VERSION ""

NS_ :

BS_:

BU_: PowertrainControlModule AtmosphericSensor SafetyRestraintSystem2 Aftertreatment_2_GasOutlet Aftertreatment_2_GasIntake DieselParticulateFilterControl Turbocharger SafetyRestraintSystem1 CabDisplay2 Aftertreatment_1_GasOutlet Aftertreatment_1_GasIntake OnBoardDataLogger OffBoardDiagnosticTool2 OffBoardDiagnosticTool1 FileServer ParkingBrakeController SeatController2 FanDriveController SteeringColumnUnit CommunicationUnitRadio CommunicationUnitSatellite CommunicationUnitCellular PropulsionBatteryCharger ChassisController2 ChassisController1 EngineValveControl AuxiliaryHeater2 AuxiliaryHeater1 ClutchUnit RampControl InformationSystem1 SuspensionSystemController2 OilSensor VehicleDynamicStability ExhaustEmissionController TransmissionDisplay2 TransmissionDisplay1 ClimateControl2 WaterPumpController RearAxleSteeringController LightingOperatorControl SeatController1 IgnitionController2 IgnitionController1 TirePressureController CabController2 CabController1 PneumaticSystemController SuspensionSystemController1 HydraulicPumpController EnduranceBrakingSystem RetarderExhaustEngine2 OnBoardDiagnosticUnit HeadwayController RetarderExhaustEngine1 CabDisplay1 ManagementComputer VirtualTerminal OffVehicleGateway PowerTakeOffFront HitchControl AuxiliaryValveControl BodyController TractorTrailerBridge1 StarterSystem ElectricalSystem VehicleSecurity VehicleNavigation AerodynamicControl ElectricalChargingSystem ClimateControl1 TripRecorder InstrumentCluster SuspensionDriveAxle2 SuspensionDriveAxle1 SuspensionSteerAxle SteeringController FuelSystem CruiseControl RetarderDriveline RetarderEngine BrakesDriveAxle2 BrakesDriveAxle1 BrakesSystemController BrakesSteerAxle AxleDrive2 AxleDrive1 AxleSteering PowerTakeOff ShiftConsoleSecondary ShiftConsolePrimary Transmission2 Transmission1 Engine2 Engine1

BO_ 2566835710 DM4: 13 Vector__XXX
 SG_ EngIntakeManifold1Press : 48|8@1+ (2,0) [0|500] "kPa" Vector__XXX
 SG_ FreezeFrameLength : 0|8@1+ (1,0) [0|255] "" Vector__XXX
 SG_ EngSpeed : 56|16@1+ (0.125,0) [0|8031.875] "rpm" Vector__XXX
 SG_ EngTorqueMode : 40|4@1+ (1,0) [0|15] "" Vector__XXX
 SG_ WheelBasedVehicleSpeed : 88|16@1+ (0.00390625,0) [0|250.996] "km/h" Vector__XXX
 SG_ EngPercentLoadAtCurrentSpeed : 72|8@1+ (1,0) [0|125] "%" Vector__XXX
 SG_ EngCoolantTemp : 80|8@1+ (1,-40) [-40|210] "°C" Vector__XXX
 SG_ DTC1 : 8|32@1+ (1,0) [0|4294967295] "" Vector__XXX

BO_ 2365508862 DM3: 0 Vector__XXX

BO_ 2566764542 DM25: 13 Vector__XXX
 SG_ ExpandedFreezeFrameLength : 0|8@1+ (1,0) [0|255] "" Vector__XXX
 SG_ DTC1 : 8|32@1+ (1,0) [0|4294967295] "" Vector__XXX

BO_ 2566764286 DM24: 12 Vector__XXX
 SG_ SPNSupported1High : 21|3@1+ (1,0) [0|7] "" Vector__XXX
 SG_ SPNSupportTypeSTR3 : 82|1@1+ (1,0) [0|1] "" Vector__XXX
 SG_ SPNSupportTypeSTR2 : 50|1@1+ (1,0) [0|1] "" Vector__XXX
 SG_ SPNSupportTypeEFF3 : 80|1@1+ (1,0) [0|1] "" Vector__XXX
 SG_ SPNSupportTypeEFF2 : 48|1@1+ (1,0) [0|1] "" Vector__XXX
 SG_ SPNSupportTypeDS3 : 81|1@1+ (1,0) [0|1] "" Vector__XXX
 SG_ SPNSupportTypeDS2 : 49|1@1+ (1,0) [0|1] "" Vector__XXX
 SG_ SPNSupported3High : 85|3@1+ (1,0) [0|7] "" Vector__XXX
 SG_ SPNSupported2High : 53|3@1+ (1,0) [0|7] "" Vector__XXX
 SG_ SPNSupported3 : 64|16@1+ (1,0) [0|65535] "" Vector__XXX
 SG_ SPNSupported2 : 32|16@1+ (1,0) [0|65535] "" Vector__XXX
 SG_ SPNDataLength3 : 88|8@1+ (1,0) [0|240] "" Vector__XXX
 SG_ SPNSupportTypeSTR1 : 18|1@1+ (1,0) [0|1] "" Vector__XXX
 SG_ SPNSupportTypeDS1 : 17|1@1+ (1,0) [0|1] "" Vector__XXX
 SG_ SPNSupportTypeEFF1 : 16|1@1+ (1,0) [0|1] "" Vector__XXX
 SG_ SPNDataLength2 : 56|8@1+ (1,0) [0|240] "" Vector__XXX
 SG_ SPNDataLength1 : 24|8@1+ (1,0) [0|250] "" Vector__XXX
 SG_ SPNSupported1 : 0|16@1+ (1,0) [0|524287] "" Vector__XXX

BO_ 2566764030 DM23: 22 Vector__XXX
 SG_ FlashRedStopLamp : 12|2@1+ (1,0) [0|3] "" Vector__XXX
 SG_ FlashProtectLamp : 8|2@1+ (1,0) [0|3] "" Vector__XXX
 SG_ FlashMalfuncIndicatorLamp : 14|2@1+ (1,0) [0|3] "" Vector__XXX
 SG_ FlashAmberWarningLamp : 10|2@1+ (1,0) [0|3] "" Vector__XXX
 SG_ MalfunctionIndicatorLampStatus : 6|2@1+ (1,0) [0|3] "" Vector__XXX
 SG_ RedStopLampState : 4|2@1+ (1,0) [0|3] "" Vector__XXX
 SG_ AmberWarningLampStatus : 2|2@1+ (1,0) [0|3] "" Vector__XXX
 SG_ ProtectLampStatus : 0|2@1+ (1,0) [0|3] "" Vector__XXX
 SG_ DTC5 : 144|32@1+ (1,0) [0|4294967295] "" Vector__XXX
 SG_ DTC4 : 112|32@1+ (1,0) [0|4294967295] "" Vector__XXX
 SG_ DTC3 : 80|32@1+ (1,0) [0|4294967295] "" Vector__XXX
 SG_ DTC2 : 48|32@1+ (1,0) [0|4294967295] "" Vector__XXX
 SG_ DTC1 : 16|32@1+ (1,0) [0|4294967295] "" Vector__XXX

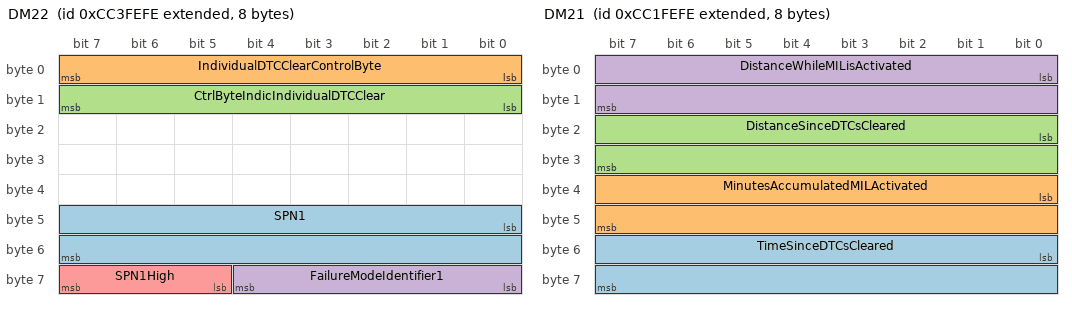
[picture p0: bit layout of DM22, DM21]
BO_ 2361655038 DM22: 8 Vector__XXX
 SG_ SPN1 : 40|16@1+ (1,0) [0|524287] "" Vector__XXX
 SG_ IndividualDTCClearControlByte : 0|8@1+ (1,0) [0|255] "" Vector__XXX
 SG_ CtrlByteIndicIndividualDTCClear : 8|8@1+ (1,0) [0|255] "" Vector__XXX
 SG_ FailureModeIdentifier1 : 56|5@1+ (1,0) [0|31] "" Vector__XXX
 SG_ SPN1High : 61|3@1+ (1,0) [0|7] "" Vector__XXX

BO_ 2361523966 DM21: 8 Vector__XXX
 SG_ TimeSinceDTCsCleared : 48|16@1+ (1,0) [0|64255] "min" Vector__XXX
 SG_ MinutesAccumulatedMILActivated : 32|16@1+ (1,0) [0|64255] "min" Vector__XXX
 SG_ DistanceSinceDTCsCleared : 16|16@1+ (1,0) [0|64255] "km" Vector__XXX
 SG_ DistanceWhileMILisActivated : 0|16@1+ (1,0) [0|64255] "km" Vector__XXX

BO_ 2562916094 DM20: 11 Vector__XXX
 SG_ ApplSysMonitorDenominator : 72|16@1+ (1,0) [0|65535] "" Vector__XXX
 SG_ ApplSysMonitorNumerator : 56|16@1+ (1,0) [0|65535] "" Vector__XXX
 SG_ SPNofApplSysMonitor : 32|24@1+ (1,0) [0|524287] "" Vector__XXX
 SG_ OBDMonitoringCondEncountered : 16|16@1+ (1,0) [0|65535] "" Vector__XXX
 SG_ IgnitionCycleCounter : 0|16@1+ (1,0) [0|65535] "" Vector__XXX

BO_ 2566834945 DM2: 22 Vector__XXX
 SG_ MalfunctionIndicatorLampStatus : 6|2@1+ (1,0) [0|3] "" Vector__XXX
 SG_ RedStopLampState : 4|2@1+ (1,0) [0|3] "" Vector__XXX
 SG_ AmberWarningLampStatus : 2|2@1+ (1,0) [0|3] "" Vector__XXX
 SG_ ProtectLampStatus : 0|2@1+ (1,0) [0|3] "" Vector__XXX
 SG_ FlashRedStopLamp : 12|2@1+ (1,0) [0|3] "" Vector__XXX
 SG_ FlashProtectLamp : 8|2@1+ (1,0) [0|3] "" Vector__XXX
 SG_ FlashMalfuncIndicatorLamp : 14|2@1+ (1,0) [0|3] "" Vector__XXX
 SG_ FlashAmberWarningLamp : 10|2@1+ (1,0) [0|3] "" Vector__XXX
 SG_ DTC5 : 144|32@1+ (1,0) [0|4294967295] "" Vector__XXX
 SG_ DTC4 : 112|32@1+ (1,0) [0|4294967295] "" Vector__XXX
 SG_ DTC3 : 80|32@1+ (1,0) [0|4294967295] "" Vector__XXX
 SG_ DTC2 : 48|32@1+ (1,0) [0|4294967295] "" Vector__XXX
 SG_ DTC1 : 16|32@1+ (1,0) [0|4294967295] "" Vector__XXX

BO_ 2564030206 DM19: 20 Vector__XXX
 SG_ CalibrationID4 : 128|32@1+ (1,0) [0|4294967295] "" Vector__XXX
 SG_ CalibrationID3 : 96|32@1+ (1,0) [0|4294967295] "" Vector__XXX
 SG_ CalibrationID2 : 64|32@1+ (1,0) [0|4294967295] "" Vector__XXX
 SG_ CalibrationID1 : 32|32@1+ (1,0) [0|255] "" Vector__XXX
 SG_ CalibrationVerificationNumber : 0|32@1+ (1,0) [0|4294967295] "" Vector__XXX

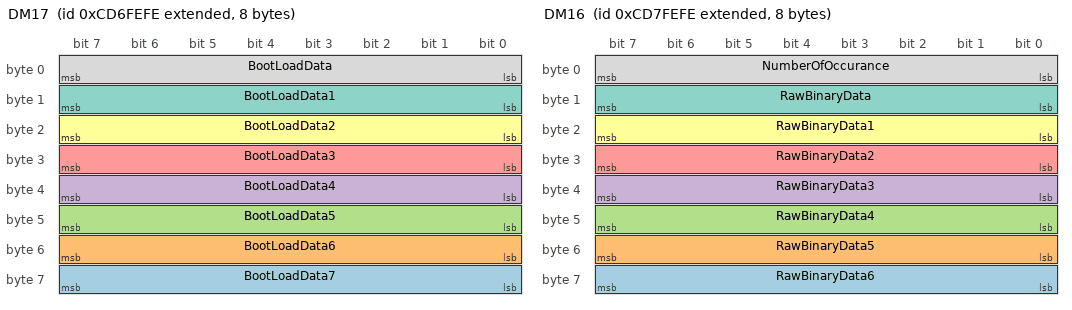
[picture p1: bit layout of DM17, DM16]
BO_ 2362900222 DM17: 8 Vector__XXX
 SG_ BootLoadData7 : 56|8@1- (1,0) [0|0] "" Vector__XXX
 SG_ BootLoadData6 : 48|8@1- (1,0) [0|0] "" Vector__XXX
 SG_ BootLoadData5 : 40|8@1- (1,0) [0|0] "" Vector__XXX
 SG_ BootLoadData4 : 32|8@1- (1,0) [0|0] "" Vector__XXX
 SG_ BootLoadData3 : 24|8@1- (1,0) [0|0] "" Vector__XXX
 SG_ BootLoadData2 : 16|8@1- (1,0) [0|0] "" Vector__XXX
 SG_ BootLoadData1 : 8|8@1- (1,0) [0|0] "" Vector__XXX
 SG_ BootLoadData : 0|8@1+ (1,0) [0|0] "" Vector__XXX

BO_ 2362965758 DM16: 8 Vector__XXX
 SG_ RawBinaryData6 : 56|8@1- (1,0) [0|0] "" Vector__XXX
 SG_ RawBinaryData5 : 48|8@1- (1,0) [0|0] "" Vector__XXX
 SG_ RawBinaryData4 : 40|8@1- (1,0) [0|0] "" Vector__XXX
 SG_ RawBinaryData3 : 32|8@1- (1,0) [0|0] "" Vector__XXX
 SG_ RawBinaryData2 : 24|8@1- (1,0) [0|0] "" Vector__XXX
 SG_ RawBinaryData1 : 16|8@1- (1,0) [0|0] "" Vector__XXX
 SG_ RawBinaryData : 8|8@1+ (1,0) [0|0] "" Vector__XXX
 SG_ NumberOfOccurance : 0|8@1+ (1,0) [0|255] "" Vector__XXX

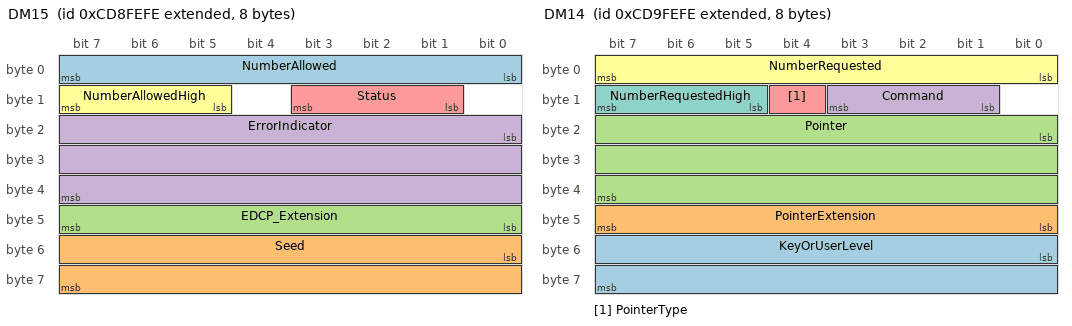
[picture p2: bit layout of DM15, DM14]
BO_ 2363031294 DM15: 8 Vector__XXX
 SG_ NumberAllowed : 0|8@1+ (1,0) [0|2047] "" Vector__XXX
 SG_ Seed : 48|16@1+ (1,0) [0|65535] "" Vector__XXX
 SG_ EDCP_Extension : 40|8@1+ (1,0) [0|255] "" Vector__XXX
 SG_ ErrorIndicator : 16|24@1+ (1,0) [0|16777215] "" Vector__XXX
 SG_ Status : 9|3@1+ (1,0) [0|7] "" Vector__XXX
 SG_ NumberAllowedHigh : 13|3@1+ (1,0) [0|7] "" Vector__XXX

BO_ 2363096830 DM14: 8 Vector__XXX
 SG_ KeyOrUserLevel : 48|16@1+ (1,0) [0|65535] "" Vector__XXX
 SG_ PointerExtension : 40|8@1+ (1,0) [0|255] "" Vector__XXX
 SG_ Pointer : 16|24@1+ (1,0) [0|16777215] "" Vector__XXX
 SG_ Command : 9|3@1+ (1,0) [0|7] "" Vector__XXX
 SG_ PointerType : 12|1@1+ (1,0) [0|1] "" Vector__XXX
 SG_ NumberRequested : 0|8@1+ (1,0) [0|2047] "" Vector__XXX
 SG_ NumberRequestedHigh : 13|3@1+ (1,0) [0|7] "" Vector__XXX

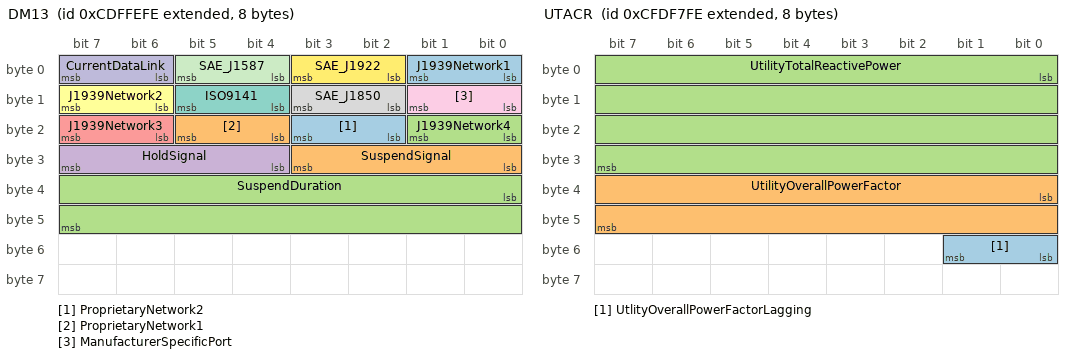
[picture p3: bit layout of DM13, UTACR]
BO_ 2363490046 DM13: 8 Vector__XXX
 SG_ ProprietaryNetwork2 : 18|2@1+ (1,0) [0|3] "" Vector__XXX
 SG_ ProprietaryNetwork1 : 20|2@1+ (1,0) [0|3] "" Vector__XXX
 SG_ J1939Network4 : 16|2@1+ (1,0) [0|3] "" Vector__XXX
 SG_ HoldSignal : 28|4@1+ (1,0) [0|15] "" Vector__XXX
 SG_ J1939Network3 : 22|2@1+ (1,0) [0|3] "" Vector__XXX
 SG_ J1939Network2 : 14|2@1+ (1,0) [0|3] "" Vector__XXX
 SG_ ISO9141 : 12|2@1+ (1,0) [0|3] "" Vector__XXX
 SG_ SAE_J1850 : 10|2@1+ (1,0) [0|3] "" Vector__XXX
 SG_ ManufacturerSpecificPort : 8|2@1+ (1,0) [0|3] "" Vector__XXX
 SG_ CurrentDataLink : 6|2@1+ (1,0) [0|3] "" Vector__XXX
 SG_ SAE_J1587 : 4|2@1+ (1,0) [0|3] "" Vector__XXX
 SG_ SAE_J1922 : 2|2@1+ (1,0) [0|3] "" Vector__XXX
 SG_ J1939Network1 : 0|2@1+ (1,0) [0|3] "" Vector__XXX
 SG_ SuspendSignal : 24|4@1+ (1,0) [0|15] "" Vector__XXX
 SG_ SuspendDuration : 32|16@1+ (1,0) [0|64255] "s" Vector__XXX

BO_ 2566837502 DM12: 22 Vector__XXX
 SG_ FlashRedStopLamp : 12|2@1+ (1,0) [0|3] "" Vector__XXX
 SG_ FlashProtectLamp : 8|2@1+ (1,0) [0|3] "" Vector__XXX
 SG_ MalfunctionIndicatorLampStatus : 6|2@1+ (1,0) [0|3] "" Vector__XXX
 SG_ RedStopLampState : 4|2@1+ (1,0) [0|3] "" Vector__XXX
 SG_ AmberWarningLampStatus : 2|2@1+ (1,0) [0|3] "" Vector__XXX
 SG_ ProtectLampStatus : 0|2@1+ (1,0) [0|3] "" Vector__XXX
 SG_ FlashMalfuncIndicatorLamp : 14|2@1+ (1,0) [0|3] "" Vector__XXX
 SG_ FlashAmberWarningLamp : 10|2@1+ (1,0) [0|3] "" Vector__XXX
 SG_ DTC5 : 144|32@1+ (1,0) [0|4294967295] "" Vector__XXX
 SG_ DTC4 : 112|32@1+ (1,0) [0|4294967295] "" Vector__XXX
 SG_ DTC3 : 80|32@1+ (1,0) [0|4294967295] "" Vector__XXX
 SG_ DTC2 : 48|32@1+ (1,0) [0|4294967295] "" Vector__XXX
 SG_ DTC1 : 16|32@1+ (1,0) [0|4294967295] "" Vector__XXX

BO_ 2365510654 DM11: 0 Vector__XXX

BO_ 2365510398 DM10: 8 Vector__XXX
 SG_ TestIdentifierSupported : 0|64@1+ (1,0) [0|0] "" Vector__XXX

BO_ 2566834942 DM1: 22 Vector__XXX
 SG_ FlashRedStopLamp : 12|2@1+ (1,0) [0|3] "" Vector__XXX
 SG_ FlashProtectLamp : 8|2@1+ (1,0) [0|3] "" Vector__XXX
 SG_ FlashMalfuncIndicatorLamp : 14|2@1+ (1,0) [0|3] "" Vector__XXX
 SG_ FlashAmberWarningLamp : 10|2@1+ (1,0) [0|3] "" Vector__XXX
 SG_ MalfunctionIndicatorLampStatus : 6|2@1+ (1,0) [0|3] "" Vector__XXX
 SG_ AmberWarningLampStatus : 2|2@1+ (1,0) [0|3] "" Vector__XXX
 SG_ RedStopLampState : 4|2@1+ (1,0) [0|3] "" Vector__XXX
 SG_ ProtectLampStatus : 0|2@1+ (1,0) [0|3] "" Vector__XXX
 SG_ DTC5 : 144|32@1+ (1,0) [0|4294967295] "" Vector__XXX
 SG_ DTC4 : 112|32@1+ (1,0) [0|4294967295] "" Vector__XXX
 SG_ DTC3 : 80|32@1+ (1,0) [0|4294967295] "" Vector__XXX
 SG_ DTC2 : 48|32@1+ (1,0) [0|4294967295] "" Vector__XXX
 SG_ DTC1 : 16|32@1+ (1,0) [0|4294967295] "" Vector__XXX

BO_ 2365454334 UTACR: 8 Vector__XXX
 SG_ UtlityOverallPowerFactorLagging : 48|2@1+ (1,0) [0|3] "" Vector__XXX
 SG_ UtilityOverallPowerFactor : 32|16@1+ (6.103515625E-005,-1) [-1|2.921814] "" Vector__XXX
 SG_ UtilityTotalReactivePower : 0|32@1+ (1,-2000000000) [-2000000000|2211081215] "VAr" Vector__XXX

BO_ 2365454590 UTACP: 8 Vector__XXX
 SG_ UtilityTotalApparentPower : 32|32@1+ (1,-2000000000) [-2000000000|2211081215] "VA" Vector__XXX
 SG_ UtilityTotalRealPower : 0|32@1+ (1,-2000000000) [-2000000000|2211081215] "W" Vector__XXX

BO_ 2365451774 UTACE: 8 Vector__XXX
 SG_ UtilityTotalKWHoursImport : 32|32@1+ (1,0) [0|4211081215] "kWh" Vector__XXX
 SG_ UtilityTotalKWHoursExport : 0|32@1+ (1,0) [0|4211081215] "kWh" Vector__XXX

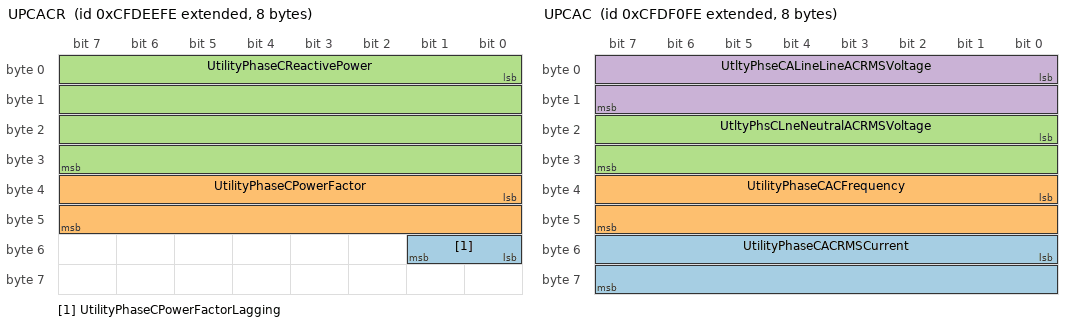
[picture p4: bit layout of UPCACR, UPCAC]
BO_ 2365452030 UPCACR: 8 Vector__XXX
 SG_ UtilityPhaseCPowerFactorLagging : 48|2@1+ (1,0) [0|3] "" Vector__XXX
 SG_ UtilityPhaseCPowerFactor : 32|16@1+ (6.103515625E-005,-1) [-1|2.921814] "" Vector__XXX
 SG_ UtilityPhaseCReactivePower : 0|32@1+ (1,-2000000000) [-2000000000|2211081215] "VAr" Vector__XXX

BO_ 2365452286 UPCACP: 8 Vector__XXX
 SG_ UtilityPhaseCApparentPower : 32|32@1+ (1,-2000000000) [-2000000000|2211081215] "VA" Vector__XXX
 SG_ UtilityPhaseCRealPower : 0|32@1+ (1,-2000000000) [-2000000000|2211081215] "W" Vector__XXX

BO_ 2365452542 UPCAC: 8 Vector__XXX
 SG_ UtilityPhaseCACRMSCurrent : 48|16@1+ (1,0) [0|64255] "A" Vector__XXX
 SG_ UtilityPhaseCACFrequency : 32|16@1+ (0.0078125,0) [0|501.9921875] "Hz" Vector__XXX
 SG_ UtltyPhsCLneNeutralACRMSVoltage : 16|16@1+ (1,0) [0|64255] "V" Vector__XXX
 SG_ UtltyPhseCALineLineACRMSVoltage : 0|16@1+ (1,0) [0|64255] "V" Vector__XXX

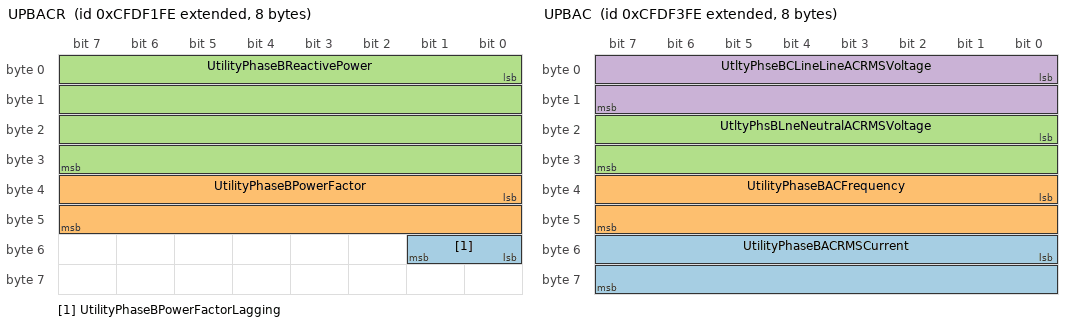
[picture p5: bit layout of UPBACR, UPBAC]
BO_ 2365452798 UPBACR: 8 Vector__XXX
 SG_ UtilityPhaseBPowerFactorLagging : 48|2@1+ (1,0) [0|3] "" Vector__XXX
 SG_ UtilityPhaseBPowerFactor : 32|16@1+ (6.103515625E-005,-1) [-1|2.921814] "" Vector__XXX
 SG_ UtilityPhaseBReactivePower : 0|32@1+ (1,-2000000000) [-2000000000|2211081215] "VAr" Vector__XXX

BO_ 2365453054 UPBACP: 8 Vector__XXX
 SG_ UtilityPhaseBApparentPower : 32|32@1+ (1,-2000000000) [-2000000000|2211081215] "VA" Vector__XXX
 SG_ UtilityPhaseBRealPower : 0|32@1+ (1,-2000000000) [-2000000000|2211081215] "W" Vector__XXX

BO_ 2365453310 UPBAC: 8 Vector__XXX
 SG_ UtilityPhaseBACRMSCurrent : 48|16@1+ (1,0) [0|64255] "A" Vector__XXX
 SG_ UtilityPhaseBACFrequency : 32|16@1+ (0.0078125,0) [0|501.9921875] "Hz" Vector__XXX
 SG_ UtltyPhsBLneNeutralACRMSVoltage : 16|16@1+ (1,0) [0|64255] "V" Vector__XXX
 SG_ UtltyPhseBCLineLineACRMSVoltage : 0|16@1+ (1,0) [0|64255] "V" Vector__XXX

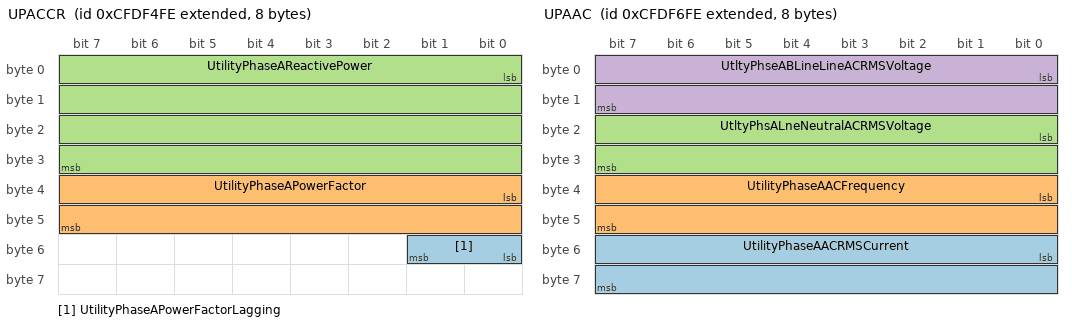
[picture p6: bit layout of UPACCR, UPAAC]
BO_ 2365453566 UPACCR: 8 Vector__XXX
 SG_ UtilityPhaseAPowerFactorLagging : 48|2@1+ (1,0) [0|3] "" Vector__XXX
 SG_ UtilityPhaseAPowerFactor : 32|16@1+ (6.103515625E-005,-1) [-1|2.921814] "" Vector__XXX
 SG_ UtilityPhaseAReactivePower : 0|32@1+ (1,-2000000000) [-2000000000|2211081215] "VAr" Vector__XXX

BO_ 2365453822 UPAACP: 8 Vector__XXX
 SG_ UtilityPhaseAApparentPower : 32|32@1+ (1,-2000000000) [-2000000000|2211081215] "VA" Vector__XXX
 SG_ UtilityPhaseARealPower : 0|32@1+ (1,-2000000000) [-2000000000|2211081215] "W" Vector__XXX

BO_ 2365454078 UPAAC: 8 Vector__XXX
 SG_ UtilityPhaseAACRMSCurrent : 48|16@1+ (1,0) [0|64255] "A" Vector__XXX
 SG_ UtilityPhaseAACFrequency : 32|16@1+ (0.0078125,0) [0|501.9921875] "Hz" Vector__XXX
 SG_ UtltyPhsALneNeutralACRMSVoltage : 16|16@1+ (1,0) [0|64255] "V" Vector__XXX
 SG_ UtltyPhseABLineLineACRMSVoltage : 0|16@1+ (1,0) [0|64255] "V" Vector__XXX

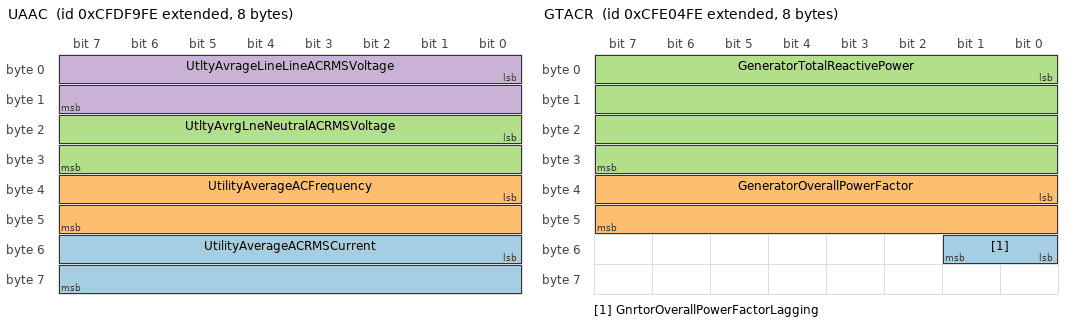
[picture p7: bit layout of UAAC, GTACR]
BO_ 2365454846 UAAC: 8 Vector__XXX
 SG_ UtilityAverageACRMSCurrent : 48|16@1+ (1,0) [0|64255] "A" Vector__XXX
 SG_ UtilityAverageACFrequency : 32|16@1+ (0.0078125,0) [0|501.9921875] "Hz" Vector__XXX
 SG_ UtltyAvrgLneNeutralACRMSVoltage : 16|16@1+ (1,0) [0|64255] "V" Vector__XXX
 SG_ UtltyAvrageLineLineACRMSVoltage : 0|16@1+ (1,0) [0|64255] "V" Vector__XXX

BO_ 2365457662 GTACR: 8 Vector__XXX
 SG_ GnrtorOverallPowerFactorLagging : 48|2@1+ (1,0) [0|3] "" Vector__XXX
 SG_ GeneratorOverallPowerFactor : 32|16@1+ (6.103515625E-005,-1) [-1|1] "" Vector__XXX
 SG_ GeneratorTotalReactivePower : 0|32@1+ (1,-2000000000) [-2000000000|2211081215] "VAr" Vector__XXX

BO_ 2365457918 GTACP: 8 Vector__XXX
 SG_ GeneratorTotalApparentPower : 32|32@1+ (1,-2000000000) [-2000000000|2211081215] "VA" Vector__XXX
 SG_ GeneratorTotalRealPower : 0|32@1+ (1,-2000000000) [-2000000000|2211081215] "W" Vector__XXX

BO_ 2365455102 GTACE: 8 Vector__XXX
 SG_ GeneratorTotalKWHoursImport : 32|32@1+ (1,0) [0|4211081215] "kWh" Vector__XXX
 SG_ GeneratorTotalKWHoursExport : 0|32@1+ (1,0) [0|4211081215] "kWh" Vector__XXX

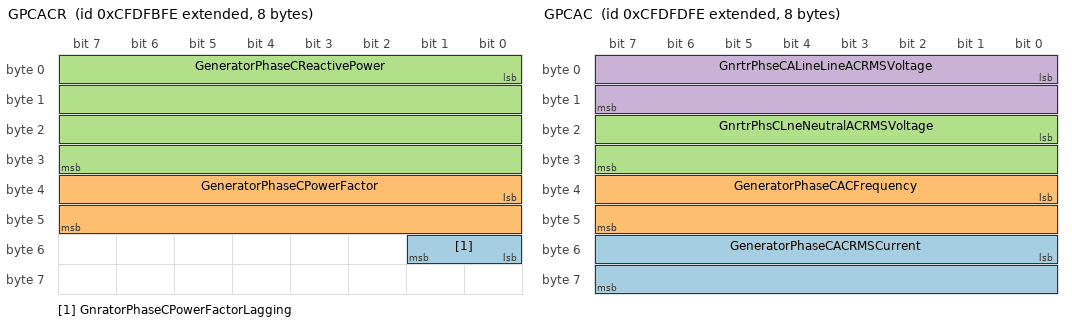
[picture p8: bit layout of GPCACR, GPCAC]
BO_ 2365455358 GPCACR: 8 Vector__XXX
 SG_ GnratorPhaseCPowerFactorLagging : 48|2@1+ (1,0) [0|3] "" Vector__XXX
 SG_ GeneratorPhaseCPowerFactor : 32|16@1+ (6.103515625E-005,-1) [-1|1] "" Vector__XXX
 SG_ GeneratorPhaseCReactivePower : 0|32@1+ (1,-2000000000) [-2000000000|2211081215] "VAr" Vector__XXX

BO_ 2365455614 GPCACP: 8 Vector__XXX
 SG_ GeneratorPhaseCApparentPower : 32|32@1+ (1,-2000000000) [-2000000000|2211081215] "VA" Vector__XXX
 SG_ GeneratorPhaseCRealPower : 0|32@1+ (1,-2000000000) [-2000000000|2211081215] "W" Vector__XXX

BO_ 2365455870 GPCAC: 8 Vector__XXX
 SG_ GeneratorPhaseCACRMSCurrent : 48|16@1+ (1,0) [0|64255] "A" Vector__XXX
 SG_ GeneratorPhaseCACFrequency : 32|16@1+ (0.0078125,0) [0|501.9921875] "Hz" Vector__XXX
 SG_ GnrtrPhsCLneNeutralACRMSVoltage : 16|16@1+ (1,0) [0|64255] "V" Vector__XXX
 SG_ GnrtrPhseCALineLineACRMSVoltage : 0|16@1+ (1,0) [0|64255] "V" Vector__XXX

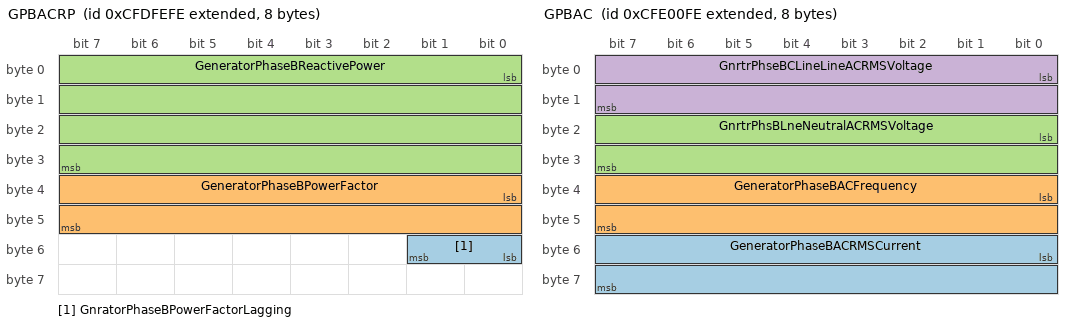
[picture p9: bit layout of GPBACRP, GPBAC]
BO_ 2365456126 GPBACRP: 8 Vector__XXX
 SG_ GnratorPhaseBPowerFactorLagging : 48|2@1+ (1,0) [0|3] "" Vector__XXX
 SG_ GeneratorPhaseBPowerFactor : 32|16@1+ (6.103515625E-005,-1) [-1|1] "" Vector__XXX
 SG_ GeneratorPhaseBReactivePower : 0|32@1+ (1,-2000000000) [-2000000000|2211081215] "VAr" Vector__XXX

BO_ 2365456382 GPBACP: 8 Vector__XXX
 SG_ GeneratorPhaseBApparentPower : 32|32@1+ (1,-2000000000) [-2000000000|2211081215] "VA" Vector__XXX
 SG_ GeneratorPhaseBRealPower : 0|32@1+ (1,-2000000000) [-2000000000|2211081215] "W" Vector__XXX

BO_ 2365456638 GPBAC: 8 Vector__XXX
 SG_ GeneratorPhaseBACRMSCurrent : 48|16@1+ (1,0) [0|64255] "A" Vector__XXX
 SG_ GeneratorPhaseBACFrequency : 32|16@1+ (0.0078125,0) [0|501.9921875] "Hz" Vector__XXX
 SG_ GnrtrPhsBLneNeutralACRMSVoltage : 16|16@1+ (1,0) [0|64255] "V" Vector__XXX
 SG_ GnrtrPhseBCLineLineACRMSVoltage : 0|16@1+ (1,0) [0|64255] "V" Vector__XXX

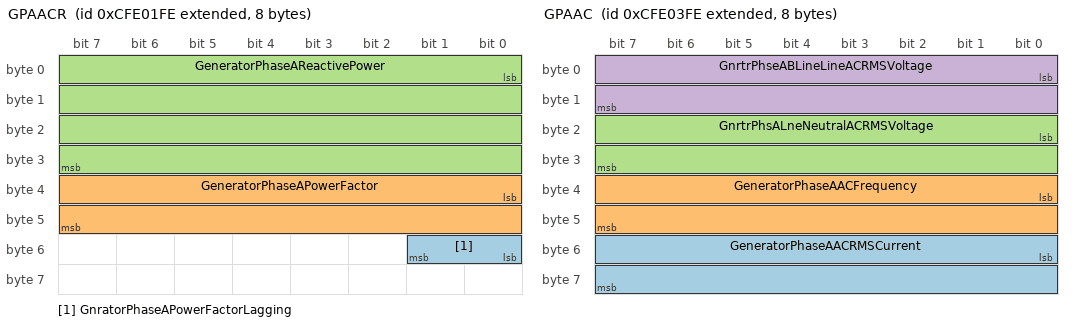
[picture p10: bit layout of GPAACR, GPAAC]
BO_ 2365456894 GPAACR: 8 Vector__XXX
 SG_ GnratorPhaseAPowerFactorLagging : 48|2@1+ (1,0) [0|3] "" Vector__XXX
 SG_ GeneratorPhaseAPowerFactor : 32|16@1+ (6.103515625E-005,-1) [-1|1] "" Vector__XXX
 SG_ GeneratorPhaseAReactivePower : 0|32@1+ (1,-2000000000) [-2000000000|2211081215] "VAr" Vector__XXX

BO_ 2365457150 GPAACP: 8 Vector__XXX
 SG_ GeneratorPhaseAApparentPower : 32|32@1+ (1,-2000000000) [-2000000000|2211081215] "VA" Vector__XXX
 SG_ GeneratorPhaseARealPower : 0|32@1+ (1,-2000000000) [-2000000000|2211081215] "W" Vector__XXX

BO_ 2365457406 GPAAC: 8 Vector__XXX
 SG_ GeneratorPhaseAACRMSCurrent : 48|16@1+ (1,0) [0|64255] "A" Vector__XXX
 SG_ GeneratorPhaseAACFrequency : 32|16@1+ (0.0078125,0) [0|501.9921875] "Hz" Vector__XXX
 SG_ GnrtrPhsALneNeutralACRMSVoltage : 16|16@1+ (1,0) [0|64255] "V" Vector__XXX
 SG_ GnrtrPhseABLineLineACRMSVoltage : 0|16@1+ (1,0) [0|64255] "V" Vector__XXX

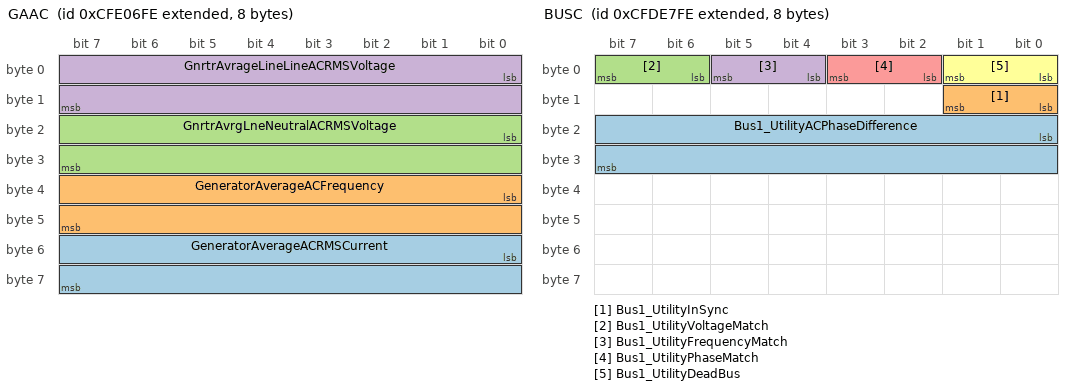
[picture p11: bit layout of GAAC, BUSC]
BO_ 2365458174 GAAC: 8 Vector__XXX
 SG_ GeneratorAverageACRMSCurrent : 48|16@1+ (1,0) [0|64255] "A" Vector__XXX
 SG_ GeneratorAverageACFrequency : 32|16@1+ (0.0078125,0) [0|501.9921875] "Hz" Vector__XXX
 SG_ GnrtrAvrgLneNeutralACRMSVoltage : 16|16@1+ (1,0) [0|64255] "V" Vector__XXX
 SG_ GnrtrAvrageLineLineACRMSVoltage : 0|16@1+ (1,0) [0|64255] "V" Vector__XXX

BO_ 2365450238 BUSC: 8 Vector__XXX
 SG_ Bus1_UtilityACPhaseDifference : 16|16@1+ (0.0078125,-200) [-200|301.99] "deg" Vector__XXX
 SG_ Bus1_UtilityInSync : 8|2@1+ (1,0) [0|3] "" Vector__XXX
 SG_ Bus1_UtilityVoltageMatch : 6|2@1+ (1,0) [0|3] "" Vector__XXX
 SG_ Bus1_UtilityFrequencyMatch : 4|2@1+ (1,0) [0|3] "" Vector__XXX
 SG_ Bus1_UtilityPhaseMatch : 2|2@1+ (1,0) [0|3] "" Vector__XXX
 SG_ Bus1_UtilityDeadBus : 0|2@1+ (1,0) [0|3] "" Vector__XXX

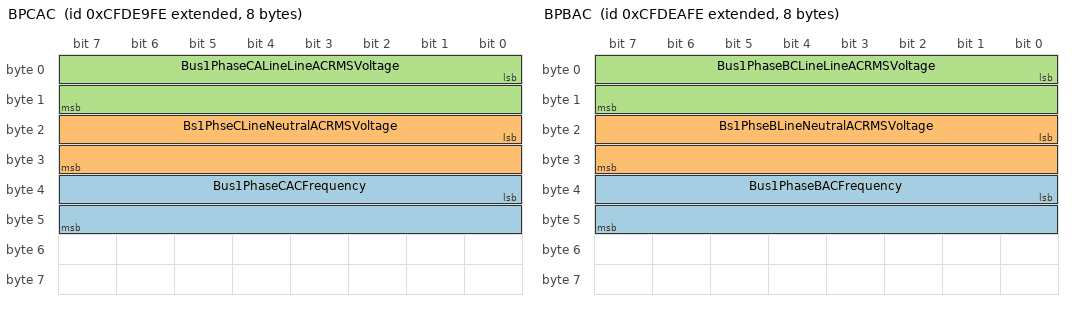
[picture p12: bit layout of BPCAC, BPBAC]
BO_ 2365450750 BPCAC: 8 Vector__XXX
 SG_ Bus1PhaseCACFrequency : 32|16@1+ (0.0078125,0) [0|501.9921875] "Hz" Vector__XXX
 SG_ Bs1PhseCLineNeutralACRMSVoltage : 16|16@1+ (1,0) [0|64255] "V" Vector__XXX
 SG_ Bus1PhaseCALineLineACRMSVoltage : 0|16@1+ (1,0) [0|64255] "V" Vector__XXX

BO_ 2365451006 BPBAC: 8 Vector__XXX
 SG_ Bus1PhaseBACFrequency : 32|16@1+ (0.0078125,0) [0|501.9921875] "Hz" Vector__XXX
 SG_ Bs1PhseBLineNeutralACRMSVoltage : 16|16@1+ (1,0) [0|64255] "V" Vector__XXX
 SG_ Bus1PhaseBCLineLineACRMSVoltage : 0|16@1+ (1,0) [0|64255] "V" Vector__XXX

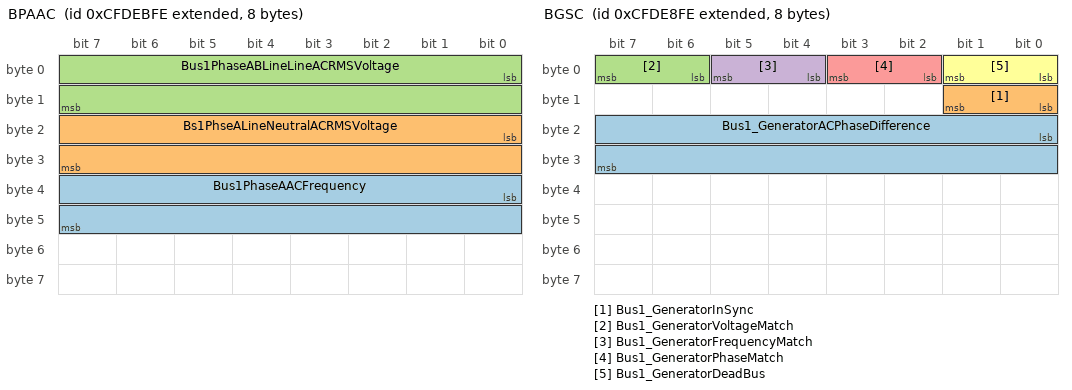
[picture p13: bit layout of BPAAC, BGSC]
BO_ 2365451262 BPAAC: 8 Vector__XXX
 SG_ Bus1PhaseAACFrequency : 32|16@1+ (0.0078125,0) [0|501.9921875] "Hz" Vector__XXX
 SG_ Bs1PhseALineNeutralACRMSVoltage : 16|16@1+ (1,0) [0|64255] "V" Vector__XXX
 SG_ Bus1PhaseABLineLineACRMSVoltage : 0|16@1+ (1,0) [0|64255] "V" Vector__XXX

BO_ 2365450494 BGSC: 8 Vector__XXX
 SG_ Bus1_GeneratorACPhaseDifference : 16|16@1+ (0.0078125,-200) [-200|301.99] "deg" Vector__XXX
 SG_ Bus1_GeneratorInSync : 8|2@1+ (1,0) [0|3] "" Vector__XXX
 SG_ Bus1_GeneratorVoltageMatch : 6|2@1+ (1,0) [0|3] "" Vector__XXX
 SG_ Bus1_GeneratorFrequencyMatch : 4|2@1+ (1,0) [0|3] "" Vector__XXX
 SG_ Bus1_GeneratorPhaseMatch : 2|2@1+ (1,0) [0|3] "" Vector__XXX
 SG_ Bus1_GeneratorDeadBus : 0|2@1+ (1,0) [0|3] "" Vector__XXX

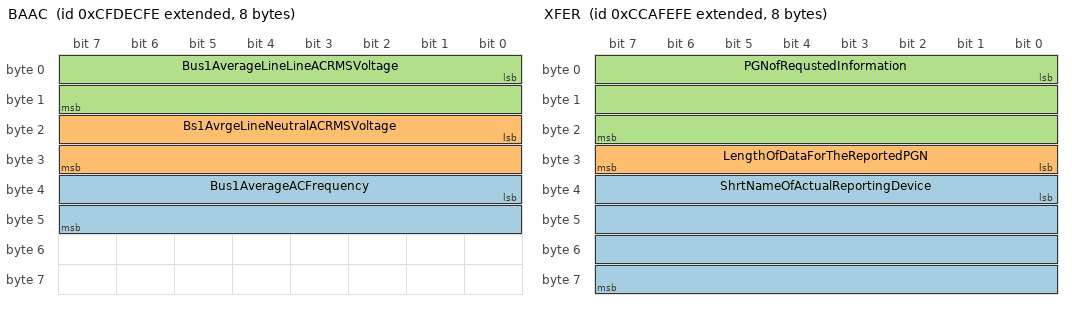
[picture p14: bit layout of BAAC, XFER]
BO_ 2365451518 BAAC: 8 Vector__XXX
 SG_ Bus1AverageACFrequency : 32|16@1+ (0.0078125,0) [0|501.9921875] "Hz" Vector__XXX
 SG_ Bs1AvrgeLineNeutralACRMSVoltage : 16|16@1+ (1,0) [0|64255] "V" Vector__XXX
 SG_ Bus1AverageLineLineACRMSVoltage : 0|16@1+ (1,0) [0|64255] "V" Vector__XXX

BO_ 2365459966 WSMSTR: 8 Vector__XXX
 SG_ NumberOfMembers : 0|8@1+ (1,0) [0|0] "" Vector__XXX

BO_ 2566838526 CA: 9 Vector__XXX
 SG_ AddressAssignment : 64|8@1+ (1,0) [0|255] "" Vector__XXX
 SG_ ArbitraryAddressCapable : 63|1@1+ (1,0) [0|1] "" Vector__XXX
 SG_ IndustryGroup M : 60|3@1+ (1,0) [0|7] "" Vector__XXX
 SG_ VehicleSystemInstance : 56|4@1+ (1,0) [0|15] "" Vector__XXX
 SG_ Function : 40|8@1+ (1,0) [0|255] "" Vector__XXX
 SG_ VehicleSystem m0 : 49|7@1+ (1,0) [0|127] "" Vector__XXX
 SG_ FunctionInstance : 35|5@1+ (1,0) [0|31] "" Vector__XXX
 SG_ ECUInstance : 32|3@1+ (1,0) [0|7] "" Vector__XXX
 SG_ ManufacturerCode : 21|11@1+ (1,0) [0|2047] "" Vector__XXX
 SG_ IdentityNumber : 0|21@1+ (1,0) [0|2097152] "" Vector__XXX
 SG_ VehicleSystem5 m5 : 49|7@1+ (1,0) [0|127] "" Vector__XXX
 SG_ VehicleSystem4 m4 : 49|7@1+ (1,0) [0|127] "" Vector__XXX
 SG_ VehicleSystem3 m3 : 49|7@1+ (1,0) [0|127] "" Vector__XXX
 SG_ VehicleSystem2 m2 : 49|7@1+ (1,0) [0|127] "" Vector__XXX
 SG_ VehicleSystem1 m1 : 49|7@1+ (1,0) [0|127] "" Vector__XXX

BO_ 2364473086 ACL: 8 Vector__XXX
 SG_ ArbitraryAddressCapable : 63|1@1+ (1,0) [0|1] "" Vector__XXX
 SG_ IndustryGroup M : 60|3@1+ (1,0) [0|7] "" Vector__XXX
 SG_ VehicleSystemInstance : 56|4@1+ (1,0) [0|15] "" Vector__XXX
 SG_ Function : 40|8@1+ (1,0) [0|255] "" Vector__XXX
 SG_ FunctionInstance : 35|5@1+ (1,0) [0|31] "" Vector__XXX
 SG_ ECUInstance : 32|3@1+ (1,0) [0|7] "" Vector__XXX
 SG_ ManufacturerCode : 21|11@1+ (1,0) [0|2047] "" Vector__XXX
 SG_ IdentityNumber : 0|21@1+ (1,0) [0|2097152] "" Vector__XXX
 SG_ VehicleSystem m0 : 49|7@1+ (1,0) [0|127] "" Vector__XXX
 SG_ VehicleSystem5 m5 : 49|7@1+ (1,0) [0|127] "" Vector__XXX
 SG_ VehicleSystem4 m4 : 49|7@1+ (1,0) [0|127] "" Vector__XXX
 SG_ VehicleSystem3 m3 : 49|7@1+ (1,0) [0|127] "" Vector__XXX
 SG_ VehicleSystem2 m2 : 49|7@1+ (1,0) [0|127] "" Vector__XXX
 SG_ VehicleSystem1 m1 : 49|7@1+ (1,0) [0|127] "" Vector__XXX

BO_ 2362113790 XFER: 8 Vector__XXX
 SG_ ShrtNameOfActualReportingDevice : 32|32@1+ (1,0) [0|0] "" Vector__XXX
 SG_ LengthOfDataForTheReportedPGN : 24|8@1+ (1,0) [0|255] "" Vector__XXX
 SG_ PGNofRequstedInformation : 0|24@1+ (1,0) [0|16777215] "" Vector__XXX

BO_ 2364276478 TPDT: 8 Vector__XXX
 SG_ SequenceNumber : 0|8@1+ (1,0) [0|255] "" Vector__XXX

BO_ 2364342014 TPCM: 8 Vector__XXX
 SG_ TotalNumberOfPacketsEoMA m19 : 24|8@1+ (1,0) [0|255] "" Vector__XXX
 SG_ TotalMessageSizeEoMA m19 : 8|16@1+ (1,0) [0|64255] "" Vector__XXX
 SG_ TotalMessageSizeBAM m32 : 8|16@1+ (1,0) [0|64255] "" Vector__XXX
 SG_ TotalNumberOfPacketsBAM m32 : 24|8@1+ (1,0) [0|255] "" Vector__XXX
 SG_ ConnectionAbortReason m255 : 8|8@1+ (1,0) [0|255] "" Vector__XXX
 SG_ NextPacketNumberToBeSent m17 : 16|8@1+ (1,0) [0|255] "" Vector__XXX
 SG_ NumberOfPacketsThatCanBeSent m17 : 8|8@1+ (1,0) [0|255] "" Vector__XXX
 SG_ PGNumber : 40|24@1+ (1,0) [0|16777200] "" Vector__XXX
 SG_ MaximumNumberOfPackets m16 : 32|8@1+ (1,0) [0|255] "" Vector__XXX
 SG_ TotalNumberOfPackets m16 : 24|8@1+ (1,0) [0|255] "" Vector__XXX
 SG_ TotalMessageSize m16 : 8|16@1+ (1,0) [0|64255] "" Vector__XXX
 SG_ ControlByte M : 0|8@1+ (1,0) [0|255] "" Vector__XXX

BO_ 2362048254 RQST2: 8 Vector__XXX
 SG_ ParameterGroupNumber : 0|24@1+ (1,0) [0|16777215] "" Vector__XXX
 SG_ UseTransferMode : 24|2@1+ (1,0) [0|3] "" Vector__XXX

BO_ 2364210942 RQST: 3 Vector__XXX
 SG_ ParameterGroupNumber : 0|24@1+ (1,0) [0|16777215] "" Vector__XXX

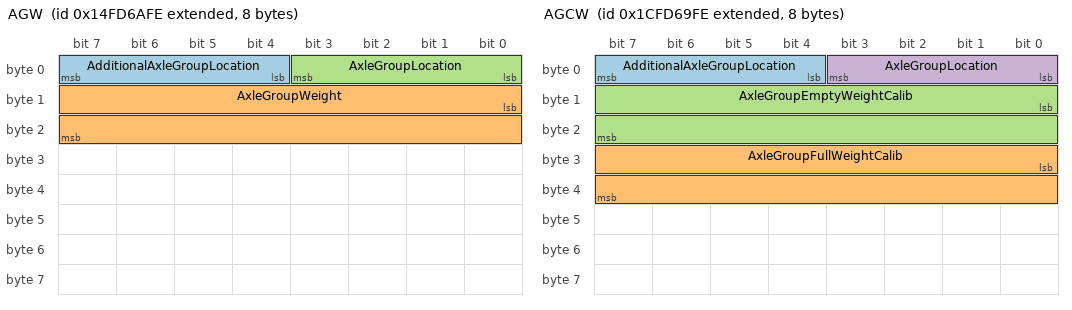
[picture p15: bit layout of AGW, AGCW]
BO_ 2499635966 AGW: 8 Vector__XXX
 SG_ AdditionalAxleGroupLocation : 4|4@1+ (1,0) [0|15] "" Vector__XXX
 SG_ AxleGroupWeight : 8|16@1+ (2,0) [0|128510] "kg" Vector__XXX
 SG_ AxleGroupLocation : 0|4@1+ (1,0) [0|15] "" Vector__XXX

BO_ 2633853438 AGCW: 8 Vector__XXX
 SG_ AdditionalAxleGroupLocation : 4|4@1+ (1,0) [0|15] "" Vector__XXX
 SG_ AxleGroupFullWeightCalib : 24|16@1+ (2,0) [0|128510] "kg" Vector__XXX
 SG_ AxleGroupEmptyWeightCalib : 8|16@1+ (2,0) [0|128510] "kg" Vector__XXX
 SG_ AxleGroupLocation : 0|4@1+ (1,0) [0|15] "" Vector__XXX

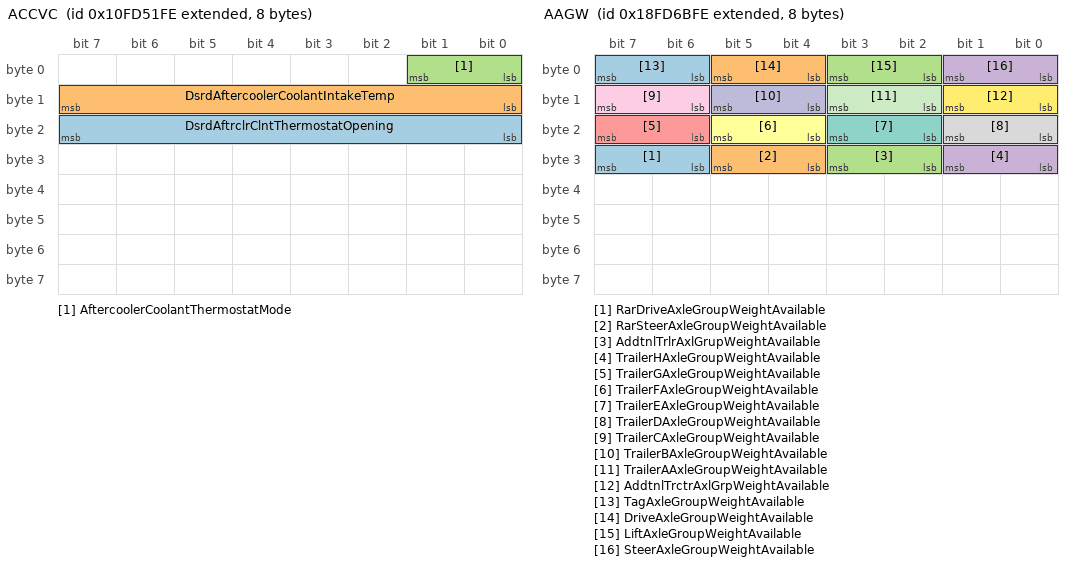
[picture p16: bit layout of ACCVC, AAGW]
BO_ 2432520702 ACCVC: 8 Vector__XXX
 SG_ DsrdAftrclrClntThermostatOpening : 16|8@1+ (0.4,0) [0|100] "%" Vector__XXX
 SG_ DsrdAftercoolerCoolantIntakeTemp : 8|8@1+ (1,-40) [-40|210] "°C" Vector__XXX
 SG_ AftercoolerCoolantThermostatMode : 0|2@1+ (1,0) [0|3] "" Vector__XXX

BO_ 2566745086 AAGW: 8 Vector__XXX
 SG_ RarDriveAxleGroupWeightAvailable : 30|2@1+ (1,0) [0|3] "" Vector__XXX
 SG_ RarSteerAxleGroupWeightAvailable : 28|2@1+ (1,0) [0|3] "" Vector__XXX
 SG_ AddtnlTrlrAxlGrupWeightAvailable : 26|2@1+ (1,0) [0|3] "" Vector__XXX
 SG_ TrailerHAxleGroupWeightAvailable : 24|2@1+ (1,0) [0|3] "" Vector__XXX
 SG_ TrailerGAxleGroupWeightAvailable : 22|2@1+ (1,0) [0|3] "" Vector__XXX
 SG_ TrailerFAxleGroupWeightAvailable : 20|2@1+ (1,0) [0|3] "" Vector__XXX
 SG_ TrailerEAxleGroupWeightAvailable : 18|2@1+ (1,0) [0|3] "" Vector__XXX
 SG_ TrailerDAxleGroupWeightAvailable : 16|2@1+ (1,0) [0|3] "" Vector__XXX
 SG_ TrailerCAxleGroupWeightAvailable : 14|2@1+ (1,0) [0|3] "" Vector__XXX
 SG_ TrailerBAxleGroupWeightAvailable : 12|2@1+ (1,0) [0|3] "" Vector__XXX
 SG_ TrailerAAxleGroupWeightAvailable : 10|2@1+ (1,0) [0|3] "" Vector__XXX
 SG_ AddtnlTrctrAxlGrpWeightAvailable : 8|2@1+ (1,0) [0|3] "" Vector__XXX
 SG_ TagAxleGroupWeightAvailable : 6|2@1+ (1,0) [0|3] "" Vector__XXX
 SG_ DriveAxleGroupWeightAvailable : 4|2@1+ (1,0) [0|3] "" Vector__XXX
 SG_ LiftAxleGroupWeightAvailable : 2|2@1+ (1,0) [0|3] "" Vector__XXX
 SG_ SteerAxleGroupWeightAvailable : 0|2@1+ (1,0) [0|3] "" Vector__XXX

BO_ 2566739198 DM52: 22 Vector__XXX
 SG_ FlashRedStopLamp : 12|2@1+ (1,0) [0|3] "" Vector__XXX
 SG_ FlashProtectLamp : 8|2@1+ (1,0) [0|3] "" Vector__XXX
 SG_ FlashMalfuncIndicatorLamp : 14|2@1+ (1,0) [0|3] "" Vector__XXX
 SG_ FlashAmberWarningLamp : 10|2@1+ (1,0) [0|3] "" Vector__XXX
 SG_ MalfunctionIndicatorLampStatus : 6|2@1+ (1,0) [0|3] "" Vector__XXX
 SG_ AmberWarningLampStatus : 2|2@1+ (1,0) [0|3] "" Vector__XXX
 SG_ RedStopLampState : 4|2@1+ (1,0) [0|3] "" Vector__XXX
 SG_ ProtectLampStatus : 0|2@1+ (1,0) [0|3] "" Vector__XXX
 SG_ DTC5 : 144|32@1+ (1,0) [0|4294967295] "" Vector__XXX
 SG_ DTC4 : 112|32@1+ (1,0) [0|4294967295] "" Vector__XXX
 SG_ DTC3 : 80|32@1+ (1,0) [0|4294967295] "" Vector__XXX
 SG_ DTC2 : 48|32@1+ (1,0) [0|4294967295] "" Vector__XXX
 SG_ DTC1 : 16|32@1+ (1,0) [0|4294967295] "" Vector__XXX

BO_ 2566739454 DM51: 22 Vector__XXX
 SG_ FlashRedStopLamp : 12|2@1+ (1,0) [0|3] "" Vector__XXX
 SG_ FlashProtectLamp : 8|2@1+ (1,0) [0|3] "" Vector__XXX
 SG_ FlashMalfuncIndicatorLamp : 14|2@1+ (1,0) [0|3] "" Vector__XXX
 SG_ FlashAmberWarningLamp : 10|2@1+ (1,0) [0|3] "" Vector__XXX
 SG_ MalfunctionIndicatorLampStatus : 6|2@1+ (1,0) [0|3] "" Vector__XXX
 SG_ AmberWarningLampStatus : 2|2@1+ (1,0) [0|3] "" Vector__XXX
 SG_ RedStopLampState : 4|2@1+ (1,0) [0|3] "" Vector__XXX
 SG_ ProtectLampStatus : 0|2@1+ (1,0) [0|3] "" Vector__XXX
 SG_ DTC5 : 144|32@1+ (1,0) [0|4294967295] "" Vector__XXX
 SG_ DTC4 : 112|32@1+ (1,0) [0|4294967295] "" Vector__XXX
 SG_ DTC3 : 80|32@1+ (1,0) [0|4294967295] "" Vector__XXX
 SG_ DTC2 : 48|32@1+ (1,0) [0|4294967295] "" Vector__XXX
 SG_ DTC1 : 16|32@1+ (1,0) [0|4294967295] "" Vector__XXX

BO_ 2566739710 DM50: 22 Vector__XXX
 SG_ FlashRedStopLamp : 12|2@1+ (1,0) [0|3] "" Vector__XXX
 SG_ FlashProtectLamp : 8|2@1+ (1,0) [0|3] "" Vector__XXX
 SG_ FlashMalfuncIndicatorLamp : 14|2@1+ (1,0) [0|3] "" Vector__XXX
 SG_ FlashAmberWarningLamp : 10|2@1+ (1,0) [0|3] "" Vector__XXX
 SG_ MalfunctionIndicatorLampStatus : 6|2@1+ (1,0) [0|3] "" Vector__XXX
 SG_ AmberWarningLampStatus : 2|2@1+ (1,0) [0|3] "" Vector__XXX
 SG_ RedStopLampState : 4|2@1+ (1,0) [0|3] "" Vector__XXX
 SG_ ProtectLampStatus : 0|2@1+ (1,0) [0|3] "" Vector__XXX
 SG_ DTC5 : 144|32@1+ (1,0) [0|4294967295] "" Vector__XXX
 SG_ DTC4 : 112|32@1+ (1,0) [0|4294967295] "" Vector__XXX
 SG_ DTC3 : 80|32@1+ (1,0) [0|4294967295] "" Vector__XXX
 SG_ DTC2 : 48|32@1+ (1,0) [0|4294967295] "" Vector__XXX
 SG_ DTC1 : 16|32@1+ (1,0) [0|4294967295] "" Vector__XXX

BO_ 2566739966 DM49: 22 Vector__XXX
 SG_ FlashRedStopLamp : 12|2@1+ (1,0) [0|3] "" Vector__XXX
 SG_ FlashProtectLamp : 8|2@1+ (1,0) [0|3] "" Vector__XXX
 SG_ FlashMalfuncIndicatorLamp : 14|2@1+ (1,0) [0|3] "" Vector__XXX
 SG_ FlashAmberWarningLamp : 10|2@1+ (1,0) [0|3] "" Vector__XXX
 SG_ MalfunctionIndicatorLampStatus : 6|2@1+ (1,0) [0|3] "" Vector__XXX
 SG_ AmberWarningLampStatus : 2|2@1+ (1,0) [0|3] "" Vector__XXX
 SG_ RedStopLampState : 4|2@1+ (1,0) [0|3] "" Vector__XXX
 SG_ ProtectLampStatus : 0|2@1+ (1,0) [0|3] "" Vector__XXX
 SG_ DTC5 : 144|32@1+ (1,0) [0|4294967295] "" Vector__XXX
 SG_ DTC4 : 112|32@1+ (1,0) [0|4294967295] "" Vector__XXX
 SG_ DTC3 : 80|32@1+ (1,0) [0|4294967295] "" Vector__XXX
 SG_ DTC2 : 48|32@1+ (1,0) [0|4294967295] "" Vector__XXX
 SG_ DTC1 : 16|32@1+ (1,0) [0|4294967295] "" Vector__XXX

BO_ 2566740222 DM48: 22 Vector__XXX
 SG_ FlashRedStopLamp : 12|2@1+ (1,0) [0|3] "" Vector__XXX
 SG_ FlashProtectLamp : 8|2@1+ (1,0) [0|3] "" Vector__XXX
 SG_ FlashMalfuncIndicatorLamp : 14|2@1+ (1,0) [0|3] "" Vector__XXX
 SG_ FlashAmberWarningLamp : 10|2@1+ (1,0) [0|3] "" Vector__XXX
 SG_ MalfunctionIndicatorLampStatus : 6|2@1+ (1,0) [0|3] "" Vector__XXX
 SG_ AmberWarningLampStatus : 2|2@1+ (1,0) [0|3] "" Vector__XXX
 SG_ RedStopLampState : 4|2@1+ (1,0) [0|3] "" Vector__XXX
 SG_ ProtectLampStatus : 0|2@1+ (1,0) [0|3] "" Vector__XXX
 SG_ DTC5 : 144|32@1+ (1,0) [0|4294967295] "" Vector__XXX
 SG_ DTC4 : 112|32@1+ (1,0) [0|4294967295] "" Vector__XXX
 SG_ DTC3 : 80|32@1+ (1,0) [0|4294967295] "" Vector__XXX
 SG_ DTC2 : 48|32@1+ (1,0) [0|4294967295] "" Vector__XXX
 SG_ DTC1 : 16|32@1+ (1,0) [0|4294967295] "" Vector__XXX

BO_ 2566740478 DM47: 22 Vector__XXX
 SG_ FlashRedStopLamp : 12|2@1+ (1,0) [0|3] "" Vector__XXX
 SG_ FlashProtectLamp : 8|2@1+ (1,0) [0|3] "" Vector__XXX
 SG_ FlashMalfuncIndicatorLamp : 14|2@1+ (1,0) [0|3] "" Vector__XXX
 SG_ FlashAmberWarningLamp : 10|2@1+ (1,0) [0|3] "" Vector__XXX
 SG_ MalfunctionIndicatorLampStatus : 6|2@1+ (1,0) [0|3] "" Vector__XXX
 SG_ AmberWarningLampStatus : 2|2@1+ (1,0) [0|3] "" Vector__XXX
 SG_ RedStopLampState : 4|2@1+ (1,0) [0|3] "" Vector__XXX
 SG_ ProtectLampStatus : 0|2@1+ (1,0) [0|3] "" Vector__XXX
 SG_ DTC5 : 144|32@1+ (1,0) [0|4294967295] "" Vector__XXX
 SG_ DTC4 : 112|32@1+ (1,0) [0|4294967295] "" Vector__XXX
 SG_ DTC3 : 80|32@1+ (1,0) [0|4294967295] "" Vector__XXX
 SG_ DTC2 : 48|32@1+ (1,0) [0|4294967295] "" Vector__XXX
 SG_ DTC1 : 16|32@1+ (1,0) [0|4294967295] "" Vector__XXX

BO_ 2566740734 DM46: 22 Vector__XXX
 SG_ FlashRedStopLamp : 12|2@1+ (1,0) [0|3] "" Vector__XXX
 SG_ FlashProtectLamp : 8|2@1+ (1,0) [0|3] "" Vector__XXX
 SG_ FlashMalfuncIndicatorLamp : 14|2@1+ (1,0) [0|3] "" Vector__XXX
 SG_ FlashAmberWarningLamp : 10|2@1+ (1,0) [0|3] "" Vector__XXX
 SG_ MalfunctionIndicatorLampStatus : 6|2@1+ (1,0) [0|3] "" Vector__XXX
 SG_ AmberWarningLampStatus : 2|2@1+ (1,0) [0|3] "" Vector__XXX
 SG_ RedStopLampState : 4|2@1+ (1,0) [0|3] "" Vector__XXX
 SG_ ProtectLampStatus : 0|2@1+ (1,0) [0|3] "" Vector__XXX
 SG_ DTC5 : 144|32@1+ (1,0) [0|4294967295] "" Vector__XXX
 SG_ DTC4 : 112|32@1+ (1,0) [0|4294967295] "" Vector__XXX
 SG_ DTC3 : 80|32@1+ (1,0) [0|4294967295] "" Vector__XXX
 SG_ DTC2 : 48|32@1+ (1,0) [0|4294967295] "" Vector__XXX
 SG_ DTC1 : 16|32@1+ (1,0) [0|4294967295] "" Vector__XXX

BO_ 2566740990 DM45: 22 Vector__XXX
 SG_ FlashRedStopLamp : 12|2@1+ (1,0) [0|3] "" Vector__XXX
 SG_ FlashProtectLamp : 8|2@1+ (1,0) [0|3] "" Vector__XXX
 SG_ FlashMalfuncIndicatorLamp : 14|2@1+ (1,0) [0|3] "" Vector__XXX
 SG_ FlashAmberWarningLamp : 10|2@1+ (1,0) [0|3] "" Vector__XXX
 SG_ MalfunctionIndicatorLampStatus : 6|2@1+ (1,0) [0|3] "" Vector__XXX
 SG_ AmberWarningLampStatus : 2|2@1+ (1,0) [0|3] "" Vector__XXX
 SG_ RedStopLampState : 4|2@1+ (1,0) [0|3] "" Vector__XXX
 SG_ ProtectLampStatus : 0|2@1+ (1,0) [0|3] "" Vector__XXX
 SG_ DTC5 : 144|32@1+ (1,0) [0|4294967295] "" Vector__XXX
 SG_ DTC4 : 112|32@1+ (1,0) [0|4294967295] "" Vector__XXX
 SG_ DTC3 : 80|32@1+ (1,0) [0|4294967295] "" Vector__XXX
 SG_ DTC2 : 48|32@1+ (1,0) [0|4294967295] "" Vector__XXX
 SG_ DTC1 : 16|32@1+ (1,0) [0|4294967295] "" Vector__XXX

BO_ 2566741246 DM44: 22 Vector__XXX
 SG_ FlashRedStopLamp : 12|2@1+ (1,0) [0|3] "" Vector__XXX
 SG_ FlashProtectLamp : 8|2@1+ (1,0) [0|3] "" Vector__XXX
 SG_ FlashMalfuncIndicatorLamp : 14|2@1+ (1,0) [0|3] "" Vector__XXX
 SG_ FlashAmberWarningLamp : 10|2@1+ (1,0) [0|3] "" Vector__XXX
 SG_ MalfunctionIndicatorLampStatus : 6|2@1+ (1,0) [0|3] "" Vector__XXX
 SG_ AmberWarningLampStatus : 2|2@1+ (1,0) [0|3] "" Vector__XXX
 SG_ RedStopLampState : 4|2@1+ (1,0) [0|3] "" Vector__XXX
 SG_ ProtectLampStatus : 0|2@1+ (1,0) [0|3] "" Vector__XXX
 SG_ DTC5 : 144|32@1+ (1,0) [0|4294967295] "" Vector__XXX
 SG_ DTC4 : 112|32@1+ (1,0) [0|4294967295] "" Vector__XXX
 SG_ DTC3 : 80|32@1+ (1,0) [0|4294967295] "" Vector__XXX
 SG_ DTC2 : 48|32@1+ (1,0) [0|4294967295] "" Vector__XXX
 SG_ DTC1 : 16|32@1+ (1,0) [0|4294967295] "" Vector__XXX

BO_ 2566741502 DM43: 22 Vector__XXX
 SG_ FlashRedStopLamp : 12|2@1+ (1,0) [0|3] "" Vector__XXX
 SG_ FlashProtectLamp : 8|2@1+ (1,0) [0|3] "" Vector__XXX
 SG_ FlashMalfuncIndicatorLamp : 14|2@1+ (1,0) [0|3] "" Vector__XXX
 SG_ FlashAmberWarningLamp : 10|2@1+ (1,0) [0|3] "" Vector__XXX
 SG_ MalfunctionIndicatorLampStatus : 6|2@1+ (1,0) [0|3] "" Vector__XXX
 SG_ AmberWarningLampStatus : 2|2@1+ (1,0) [0|3] "" Vector__XXX
 SG_ RedStopLampState : 4|2@1+ (1,0) [0|3] "" Vector__XXX
 SG_ ProtectLampStatus : 0|2@1+ (1,0) [0|3] "" Vector__XXX
 SG_ DTC5 : 144|32@1+ (1,0) [0|4294967295] "" Vector__XXX
 SG_ DTC4 : 112|32@1+ (1,0) [0|4294967295] "" Vector__XXX
 SG_ DTC3 : 80|32@1+ (1,0) [0|4294967295] "" Vector__XXX
 SG_ DTC2 : 48|32@1+ (1,0) [0|4294967295] "" Vector__XXX
 SG_ DTC1 : 16|32@1+ (1,0) [0|4294967295] "" Vector__XXX

CM_ BO_ 2566835710 "A freeze frame is defined as the list of recorded parameters at the time a diagnostic trouble code was captured";
CM_ SG_ 2566835710 EngIntakeManifold1Press "The gage pressure measurement of the air intake manifold. If there are multiple air pressure sensors in the intake stream, this is the last one in flow direction before entering the combustion chamber.  This should be the pressure used to drive ...";
CM_ SG_ 2566835710 FreezeFrameLength "The Freeze Frame Length shall be equal to the number of bytes in the required parameters plus the number of bytes in the manufacturer specific parameters.";
CM_ SG_ 2566835710 EngSpeed "Actual engine speed which is calculated over a minimum crankshaft angle of 720 degrees divided by the number of cylinders.";
CM_ SG_ 2566835710 EngTorqueMode "State signal which indicates which engine torque mode is currently generating, limiting, or controlling the torque.  Note that the modes are not in prioritized order. Not all modes may be relevant for a given device.  Some devices may not implement ...";
CM_ SG_ 2566835710 WheelBasedVehicleSpeed "Speed of the vehicle as calculated from wheel or tailshaft speed.";
CM_ SG_ 2566835710 EngPercentLoadAtCurrentSpeed "The ratio of actual engine percent torque (indicated) to maximum indicated torque available at the current engine speed, clipped to zero torque during engine braking.";
CM_ SG_ 2566835710 EngCoolantTemp "Temperature of liquid found in engine cooling system.";
CM_ SG_ 2566835710 DTC1 "Diagnostic Trouble Code";
CM_ BO_ 2566764542 "This message defines the expanded freeze frame length";
CM_ SG_ 2566764542 ExpandedFreezeFrameLength "The Freeze Frame Length is the length plus the number of bytes to convey the data of all parameters (SPNs) in Freeze Frame.";
CM_ SG_ 2566764542 DTC1 "Diagnostic Trouble Code";
CM_ BO_ 2566764286 "This message is used to identify those SPNs supported by the product for freeze frames and data stream messages.";
CM_ SG_ 2566764286 SPNSupported1High "This parameter defines the SPN(s) that is/are supported for the freeze frame and/or data stream information.";
CM_ SG_ 2566764286 SPNSupportTypeSTR3 "This parameter defines whether the applicable parameter (that is the SPN) is supported in the freeze frame, the data stream or both the freeze frame and data stream.";
CM_ SG_ 2566764286 SPNSupportTypeSTR2 "This parameter defines whether the applicable parameter (that is the SPN) is supported in the freeze frame, the data stream or both the freeze frame and data stream.";
CM_ SG_ 2566764286 SPNSupportTypeEFF3 "This parameter defines whether the applicable parameter (that is the SPN) is supported in the freeze frame, the data stream or both the freeze frame and data stream.";
CM_ SG_ 2566764286 SPNSupportTypeEFF2 "This parameter defines whether the applicable parameter (that is the SPN) is supported in the freeze frame, the data stream or both the freeze frame and data stream.";
CM_ SG_ 2566764286 SPNSupportTypeDS3 "This parameter defines whether the applicable parameter (that is the SPN) is supported in the freeze frame, the data stream or both the freeze frame and data stream.";
CM_ SG_ 2566764286 SPNSupportTypeDS2 "This parameter defines whether the applicable parameter (that is the SPN) is supported in the freeze frame, the data stream or both the freeze frame and data stream.";
CM_ SG_ 2566764286 SPNSupported3High "This parameter defines the SPN(s) that is/are supported for the freeze frame and/or data stream information.";
CM_ SG_ 2566764286 SPNSupported2High "This parameter defines the SPN(s) that is/are supported for the freeze frame and/or data stream information.";
CM_ SG_ 2566764286 SPNSupported3 "This parameter defines the SPN(s) that is/are supported for the freeze frame and/or data stream information.";
CM_ SG_ 2566764286 SPNSupported2 "This parameter defines the SPN(s) that is/are supported for the freeze frame and/or data stream information.";
CM_ SG_ 2566764286 SPNDataLength3 "The number of data bytes associated with the SPN in the Freeze Frame.";
CM_ SG_ 2566764286 SPNSupportTypeSTR1 "This parameter defines whether the applicable parameter (that is the SPN) is supported in the Scaled Test Results message, DM30.";
CM_ SG_ 2566764286 SPNSupportTypeDS1 "This parameter defines whether the applicable parameter (that is the SPN) is supported in the Data Stream messages.";
CM_ SG_ 2566764286 SPNSupportTypeEFF1 "This parameter defines whether the applicable parameter (that is the SPN) is supported in the expanded freeze frame message, DM25.";
CM_ SG_ 2566764286 SPNDataLength2 "The number of data bytes associated with the SPN in the Freeze Frame.";
CM_ SG_ 2566764286 SPNDataLength1 "The number of data bytes associated with the SPN in the Freeze Frame.";
CM_ SG_ 2566764286 SPNSupported1 "This parameter defines the SPN(s) that is/are supported for the freeze frame and/or data stream information.";
CM_ BO_ 2566764030 "This message contains DTCs that are confirmed but for which the MIL is off.";
CM_ SG_ 2566764030 FlashRedStopLamp "This parameter provides the capability to flash the RSL";
CM_ SG_ 2566764030 FlashProtectLamp "This parameter provides the capability to flash the engine protect lamp";
CM_ SG_ 2566764030 FlashMalfuncIndicatorLamp "This parameter provides the capability to flash the MIL";
CM_ SG_ 2566764030 FlashAmberWarningLamp "This parameter provides the capability to flash the AWL";
CM_ SG_ 2566764030 MalfunctionIndicatorLampStatus "A lamp used to relay only emissions-related trouble code information. This lamp is only illuminated when there is an emission-related trouble code active.";
CM_ SG_ 2566764030 RedStopLampState "This lamp is used to relay trouble code information that is of a severe enough condition that it warrants stopping the vehicle.";
CM_ SG_ 2566764030 AmberWarningLampStatus "This lamp is used to relay trouble code information that is reporting a problem with the vehicle system but the vehicle need not be immediately stopped.";
CM_ SG_ 2566764030 ProtectLampStatus "This lamp is used to relay trouble code information that is reporting a problem with a vehicle system that is most probably not electronic subsystem related. For instance, engine coolant temperature is exceeding its prescribed temperature range.";
CM_ SG_ 2566764030 DTC5 "Diagnostic Trouble Code";
CM_ SG_ 2566764030 DTC4 "Diagnostic Trouble Code";
CM_ SG_ 2566764030 DTC3 "Diagnostic Trouble Code";
CM_ SG_ 2566764030 DTC2 "Diagnostic Trouble Code";
CM_ SG_ 2566764030 DTC1 "Diagnostic Trouble Code";
CM_ BO_ 2361655038 "All of the diagnostic information pertaining to the specified diagnostic trouble code should be erased when the CLR_PA_REQ or CLR_ACT_REQ action of this PG is requested.";
CM_ SG_ 2361655038 SPN1 "DM22 the SPN of the DTC to Clear.";
CM_ SG_ 2361655038 IndividualDTCClearControlByte "DM22 Control byte is used to identify the function being performed by this message.";
CM_ SG_ 2361655038 CtrlByteIndicIndividualDTCClear "DM22 parameter which is the Negative Acknowledge Indicator For Individual DTC Clear.";
CM_ SG_ 2361655038 FailureModeIdentifier1 "DM22 the FMI of the DTC to Clear.";
CM_ SG_ 2361655038 SPN1High "SPN #1 (Conversion Version 4)";
CM_ BO_ 2361523966 "Message to convey information relevant to the readiness of the OBD system.";
CM_ SG_ 2361523966 TimeSinceDTCsCleared "Time accumulated since DTCs were cleared (via an external test equipment or possibly, a battery disconnect).";
CM_ SG_ 2361523966 MinutesAccumulatedMILActivated "Accumulated count (in minutes) while the MIL is activated (on).";
CM_ SG_ 2361523966 DistanceSinceDTCsCleared "Distance accumulated since DTCs were cleared (via an external test equipment or possibly, a battery disconnect).";
CM_ SG_ 2361523966 DistanceWhileMILisActivated "The kilometers accumulated while the MIL is activated.";
CM_ BO_ 2562916094 "Legislated On-Board Diagnostics requirements specify that manufacturers must monitor all emission and OBD system related components throughout the expected life of the vehicle.";
CM_ SG_ 2562916094 ApplSysMonitorDenominator "Identifies the number of times a vehicle has been operated that constitues a driving cycle where the Applicable System Monitor could be operated per regulatory requirements.";
CM_ SG_ 2562916094 ApplSysMonitorNumerator "Idenitifes the number of times the vehicle has been operated such that all conditions necessary for the Applicable System Monitor to detect a malfunction have been encountered.";
CM_ SG_ 2562916094 SPNofApplSysMonitor "Idenifies the SPN of the system monitor for which Monitor ratio is being reported.";
CM_ SG_ 2562916094 OBDMonitoringCondEncountered "Count the number of times that the vehicle has been operated in the specified OBD monitoring conditions.";
CM_ SG_ 2562916094 IgnitionCycleCounter "Count of the number of ignition cycles.";
CM_ BO_ 2566834945 "The information communicated is DM service to communicate the previously active trouble codes.";
CM_ SG_ 2566834945 MalfunctionIndicatorLampStatus "A lamp used to relay only emissions-related trouble code information. This lamp is only illuminated when there is an emission-related trouble code active.";
CM_ SG_ 2566834945 RedStopLampState "This lamp is used to relay trouble code information that is of a severe enough condition that it warrants stopping the vehicle.";
CM_ SG_ 2566834945 AmberWarningLampStatus "This lamp is used to relay trouble code information that is reporting a problem with the vehicle system but the vehicle need not be immediately stopped.";
CM_ SG_ 2566834945 ProtectLampStatus "This lamp is used to relay trouble code information that is reporting a problem with a vehicle system that is most probably not electronic subsystem related. For instance, engine coolant temperature is exceeding its prescribed temperature range.";
CM_ SG_ 2566834945 FlashRedStopLamp "This parameter provides the capability to flash the RSL";
CM_ SG_ 2566834945 FlashProtectLamp "This parameter provides the capability to flash the engine protect lamp";
CM_ SG_ 2566834945 FlashMalfuncIndicatorLamp "This parameter provides the capability to flash the MIL";
CM_ SG_ 2566834945 FlashAmberWarningLamp "This parameter provides the capability to flash the AWL";
CM_ SG_ 2566834945 DTC5 "Diagnostic Trouble Code";
CM_ SG_ 2566834945 DTC4 "Diagnostic Trouble Code";
CM_ SG_ 2566834945 DTC3 "Diagnostic Trouble Code";
CM_ SG_ 2566834945 DTC2 "Diagnostic Trouble Code";
CM_ SG_ 2566834945 DTC1 "Diagnostic Trouble Code";
CM_ BO_ 2564030206 "Provide information about the calibration to scan tool";
CM_ SG_ 2564030206 CalibrationID1 "Sixteen-byte calibration identification number. Uniquely identifies the software installed in the control module. The calibration ID must be unique, but does not need to be 16 bytes long.";
CM_ SG_ 2564030206 CalibrationVerificationNumber "Checksum of entire calibration, including code and data.  Excludes RAM parameters, nonvolatile parameters that change during the life cycle of the module (hours of operation, freeze frame data, etc), or non emissions related parameters that may be ...";
CM_ BO_ 2362900222 "Used primarily to load boot data/program into a device when a memory access boot load command has been issued.";
CM_ SG_ 2362900222 BootLoadData "This is a 1-byte parameter using the same SLOT as the Raw Binary Data.";
CM_ BO_ 2362965758 "Used primarily to transfer data for the memory access commands.";
CM_ SG_ 2362965758 RawBinaryData "This is a 1-byte parameter representing the value for 1 byte of memory. It can have any value between 0 and 255 (0 and 0xFF) with no reserved values.
";
CM_ SG_ 2362965758 NumberOfOccurance "This is an 8-bit (1-byte) parameter to be sent within the Binary Data Transfer PGN to provide information on the number of Raw Binary Data parameters which will follow when the message is single packet.";
CM_ BO_ 2363031294 "The main use for the Memory_Access_Response is for a device to answer a tool which has attempted to access the memory within the device.";
CM_ SG_ 2363031294 NumberAllowed "When the Status of the Memory Access Response message is a Proceed, an 11-bit parameter identifies the amount of memory (i.e. the range of memory) over which the Device is willing to allow a particular operation to be carried out.";
CM_ SG_ 2363031294 Seed "This is a 16-bit parameter which is used by the Device primarily to send a Seed to a Tool, when using a Seed/Key type security system";
CM_ SG_ 2363031294 EDCP_Extension "This is an 8-bit parameter used to identify how to handle the data in the Error Indicator/ EDC Parameter.";
CM_ SG_ 2363031294 ErrorIndicator "Used to transfer a checksum, CRC or other type of EDC parameter (or any segment thereof) or to send an Error Indicator any time the Device is not able to complete or act upon a Tool’s request.";
CM_ SG_ 2363031294 Status "This is a 3-bit parameter which allows the Device to return its Status.";
CM_ BO_ 2363096830 "The main use for the Memory_Access_Request message is by a tool wishing to alter the memory of a device.";
CM_ SG_ 2363096830 KeyOrUserLevel "Used by the tool to primarily send a key to the device, but which can also be used by the tool to provide a password or a User_Level to the device if desired.";
CM_ SG_ 2363096830 PointerExtension "This parameter is either the high order 8 bits of a complete direct memory address or the identifier of a particular spacial address.";
CM_ SG_ 2363096830 Pointer "Address based on Pointer type 0 or type 1.";
CM_ SG_ 2363096830 Command "This is a 3-bit parameter which allows the Tool to send Commands to the Device.";
CM_ SG_ 2363096830 PointerType "Indicates whether the Pointer and Pointer Extension are direct memory addresses or direct spatial addresses.";
CM_ SG_ 2363096830 NumberRequested "Identifies the amount of memory over which the tool desires an operation to be carried out.";
CM_ SG_ 2363096830 NumberRequestedHigh "Length/Number Requested";
CM_ BO_ 2363490046 "This message is used to stop or start broadcast messages. These broadcast messages may be on networks other than SAE J1939.";
CM_ SG_ 2363490046 ProprietaryNetwork2 "Identifies the action to be performed on the Proprietary Network #2 communications port.";
CM_ SG_ 2363490046 ProprietaryNetwork1 "Identifies the action to be performed on the Proprietary Network #1 communications port.";
CM_ SG_ 2363490046 J1939Network4 "Identifies the action to be performed on the J1939 Network #4 communications port.";
CM_ SG_ 2363490046 HoldSignal "Indicator to all nodes that the communication ports that have been acted upon by the Stop Start Broadcast
PGN are remaining in the modified state.";
CM_ SG_ 2363490046 J1939Network3 "Identifies the action to be performed on the J1939 Network #3 communications port.";
CM_ SG_ 2363490046 J1939Network2 "Identifies the action to be performed on the J1939 Network #2 communications port.";
CM_ SG_ 2363490046 ISO9141 "Identifies the action to be performed on the ISO 9141 communications port.";
CM_ SG_ 2363490046 SAE_J1850 "Identifies the action to be performed on the J1850 communications port.";
CM_ SG_ 2363490046 ManufacturerSpecificPort "Identifies the action to be performed on the “Other, Manufacture Specified Port” communications port.";
CM_ SG_ 2363490046 CurrentDataLink "Identifies the action to be performed on the communications port that this parameter was received on.";
CM_ SG_ 2363490046 SAE_J1587 "Identifies the action to be performed on the J1587 communications port.";
CM_ SG_ 2363490046 SAE_J1922 "Identifies the action to be performed on the J1922 communications port.";
CM_ SG_ 2363490046 J1939Network1 "Identifies the action to be performed on the J1939 Network #1, Primary Vehicle Network” communications port.";
CM_ SG_ 2363490046 SuspendSignal "Indicator to all nodes that the current communication port broadcast messages are being suspended";
CM_ SG_ 2363490046 SuspendDuration "Indicates the duration of a suspension of broadcast messages when that duration is known by the transmitting device.";
CM_ BO_ 2566837502 "The information communicated is limited to the currently active emission-related diagnostic trouble codes preceded by the diagnostic lamp status.";
CM_ SG_ 2566837502 FlashRedStopLamp "This parameter provides the capability to flash the RSL";
CM_ SG_ 2566837502 FlashProtectLamp "This parameter provides the capability to flash the engine protect lamp";
CM_ SG_ 2566837502 MalfunctionIndicatorLampStatus "A lamp used to relay only emissions-related trouble code information. This lamp is only illuminated when there is an emission-related trouble code active.";
CM_ SG_ 2566837502 RedStopLampState "This lamp is used to relay trouble code information that is of a severe enough condition that it warrants stopping the vehicle.";
CM_ SG_ 2566837502 AmberWarningLampStatus "This lamp is used to relay trouble code information that is reporting a problem with the vehicle system but the vehicle need not be immediately stopped.";
CM_ SG_ 2566837502 ProtectLampStatus "This lamp is used to relay trouble code information that is reporting a problem with a vehicle system that is most probably not electronic subsystem related. For instance, engine coolant temperature is exceeding its prescribed temperature range.";
CM_ SG_ 2566837502 FlashMalfuncIndicatorLamp "This parameter provides the capability to flash the MIL";
CM_ SG_ 2566837502 FlashAmberWarningLamp "This parameter provides the capability to flash the AWL";
CM_ SG_ 2566837502 DTC5 "Diagnostic Trouble Code";
CM_ SG_ 2566837502 DTC4 "Diagnostic Trouble Code";
CM_ SG_ 2566837502 DTC3 "Diagnostic Trouble Code";
CM_ SG_ 2566837502 DTC2 "Diagnostic Trouble Code";
CM_ SG_ 2566837502 DTC1 "Diagnostic Trouble Code";
CM_ BO_ 2365510654 "All of the diagnostic information pertaining to the active diagnostic trouble codes should be erased. Sent as a request whenever the service tool wishes to clear/reset diagnostic data for active DTCs.";
CM_ BO_ 2365510398 "The purpose of this PG is to report the list of non-continuously monitored systems tests supported by the controller.";
CM_ SG_ 2365510398 TestIdentifierSupported "Indicates the test identifiers that the controller supports.";
CM_ BO_ 2566834942 "Active Diagnostic Trouble Codes";
CM_ SG_ 2566834942 FlashRedStopLamp "This parameter provides the capability to flash the RSL";
CM_ SG_ 2566834942 FlashProtectLamp "This parameter provides the capability to flash the engine protect lamp";
CM_ SG_ 2566834942 FlashMalfuncIndicatorLamp "This parameter provides the capability to flash the MIL";
CM_ SG_ 2566834942 FlashAmberWarningLamp "This parameter provides the capability to flash the AWL";
CM_ SG_ 2566834942 MalfunctionIndicatorLampStatus "A lamp used to relay only emissions-related trouble code information. This lamp is only illuminated when there is an emission-related trouble code active.";
CM_ SG_ 2566834942 AmberWarningLampStatus "This lamp is used to relay trouble code information that is reporting a problem with the vehicle system but the vehicle need not be immediately stopped.";
CM_ SG_ 2566834942 RedStopLampState "This lamp is used to relay trouble code information that is of a severe enough condition that it warrants stopping the vehicle.";
CM_ SG_ 2566834942 ProtectLampStatus "This lamp is used to relay trouble code information that is reporting a problem with a vehicle system that is most probably not electronic subsystem related. For instance, engine coolant temperature is exceeding its prescribed temperature range.";
CM_ SG_ 2566834942 DTC5 "Diagnostic Trouble Code";
CM_ SG_ 2566834942 DTC4 "Diagnostic Trouble Code";
CM_ SG_ 2566834942 DTC3 "Diagnostic Trouble Code";
CM_ SG_ 2566834942 DTC2 "Diagnostic Trouble Code";
CM_ SG_ 2566834942 DTC1 "Diagnostic Trouble Code";
CM_ SG_ 2365454334 UtlityOverallPowerFactorLagging "Lead/lag status for utility incomer average power factor.

00 Leading
01 Lagging
10 Error
11 Not Available or Not Installed";
CM_ SG_ 2365454334 UtilityOverallPowerFactor "The average power factor of the utility incomer.";
CM_ SG_ 2365454334 UtilityTotalReactivePower "The total reactive power delivered by the utility incomer";
CM_ SG_ 2365454590 UtilityTotalApparentPower "The total apparent power delivered by the utility incomer.";
CM_ SG_ 2365454590 UtilityTotalRealPower "Total real power delivered by the utility incomer.";
CM_ SG_ 2365451774 UtilityTotalKWHoursImport "The total kilowatt-hours that have been imported by the utility incomer.";
CM_ SG_ 2365451774 UtilityTotalKWHoursExport "The total kilowatt-hours that have been exported by the utility incomer.";
CM_ SG_ 2365452030 UtilityPhaseCPowerFactorLagging "Lead/lag status for utility incomer phase C power factor.

00 Leading
01 Lagging
10 Error
11 Not Available or Not Installed";
CM_ SG_ 2365452030 UtilityPhaseCPowerFactor "The power factor of phases C of the utility incomer.";
CM_ SG_ 2365452030 UtilityPhaseCReactivePower "The reactive power delivered by phase C of the utility incomer";
CM_ SG_ 2365452286 UtilityPhaseCApparentPower "The apparent power delivered by phase C of the utility incomer.";
CM_ SG_ 2365452286 UtilityPhaseCRealPower "The real power delivered by phase C of the utility incomer.";
CM_ SG_ 2365452542 UtilityPhaseCACRMSCurrent "RMS current measured at the utility incomer phase C.";
CM_ SG_ 2365452542 UtilityPhaseCACFrequency "AC frequency measured at the utility incomer phase C.";
CM_ SG_ 2365452542 UtltyPhsCLneNeutralACRMSVoltage "Line to Neutral RMS voltage measured at the utility incomer phase C.";
CM_ SG_ 2365452542 UtltyPhseCALineLineACRMSVoltage "Line to Line RMS voltage measured at the utility incomer phase CA.";
CM_ SG_ 2365452798 UtilityPhaseBPowerFactorLagging "Lead/lag status for utility incomer phase B power factor.

00 Leading
01 Lagging
10 Error
11 Not Available or Not Installed";
CM_ SG_ 2365452798 UtilityPhaseBPowerFactor "The power factor of phases B of the utility incomer.";
CM_ SG_ 2365452798 UtilityPhaseBReactivePower "The reactive power delivered by phase B of the utility incomer";
CM_ SG_ 2365453054 UtilityPhaseBApparentPower "The apparent power delivered by phase B of the utility incomer.";
CM_ SG_ 2365453054 UtilityPhaseBRealPower "The real power delivered by phase B of the utility incomer.";
CM_ SG_ 2365453310 UtilityPhaseBACRMSCurrent "RMS current measured at the utility incomer phase B.";
CM_ SG_ 2365453310 UtilityPhaseBACFrequency "AC frequency measured at the utility incomer phase B.";
CM_ SG_ 2365453310 UtltyPhsBLneNeutralACRMSVoltage "Line to Neutral RMS voltage measured at the utility incomer phase B.";
CM_ SG_ 2365453310 UtltyPhseBCLineLineACRMSVoltage "Line to Line RMS voltage measured at the utility incomer phase BC.";
CM_ SG_ 2365453566 UtilityPhaseAPowerFactorLagging "Lead/lag status for utility incomer phase A power factor.

00 Leading
01 Lagging
10 Error
11 Not Available or Not Installed";
CM_ SG_ 2365453566 UtilityPhaseAPowerFactor "The power factor of phase A of the utility incomer.";
CM_ SG_ 2365453566 UtilityPhaseAReactivePower "The reactive power delivered by phase A of the utility incomer";
CM_ SG_ 2365453822 UtilityPhaseAApparentPower "The apparent power delivered by phase A of the utility incomer.";
CM_ SG_ 2365453822 UtilityPhaseARealPower "The real power delivered by phase A of the utility incomer.";
CM_ SG_ 2365454078 UtilityPhaseAACRMSCurrent "RMS current measured at the utility incomer phase A.";
CM_ SG_ 2365454078 UtilityPhaseAACFrequency "AC frequency measured at the utility incomer phase A.";
CM_ SG_ 2365454078 UtltyPhsALneNeutralACRMSVoltage "Line to Neutral RMS voltage measured at the utility incomer phase A.";
CM_ SG_ 2365454078 UtltyPhseABLineLineACRMSVoltage "Line to Line RMS voltage measured at the utility incomer phase AB.";
CM_ SG_ 2365454846 UtilityAverageACRMSCurrent "Average RMS current measured at the utility incomer.";
CM_ SG_ 2365454846 UtilityAverageACFrequency "Average AC frequency measured at the utility incomer.";
CM_ SG_ 2365454846 UtltyAvrgLneNeutralACRMSVoltage "The average Line to Neutral AC RMS voltage measured at the utility incomer .";
CM_ SG_ 2365454846 UtltyAvrageLineLineACRMSVoltage "Average Line to Line RMS voltage measured at the utility incomer .";
CM_ SG_ 2365457662 GnrtorOverallPowerFactorLagging "Lead/lag status for generator average power factor.

00 Leading
01 Lagging
10 Error
11 Not Available or Not Installed";
CM_ SG_ 2365457662 GeneratorOverallPowerFactor "The average power factor of the generator.";
CM_ SG_ 2365457662 GeneratorTotalReactivePower "The total reactive power delivered by the generator";
CM_ SG_ 2365457918 GeneratorTotalApparentPower "The total apparent power delivered by the generator.";
CM_ SG_ 2365457918 GeneratorTotalRealPower "Total real power delivered by the generator.";
CM_ SG_ 2365455102 GeneratorTotalKWHoursImport "The total kilowatt-hours that have been imported by the generator.";
CM_ SG_ 2365455102 GeneratorTotalKWHoursExport "The total kilowatt-hours that have been exported by the generator.";
CM_ SG_ 2365455358 GnratorPhaseCPowerFactorLagging "Lead/lag status for generator phase C power factor.

00 Leading
01 Lagging
10 Error
11 Not Available or Not Installed";
CM_ SG_ 2365455358 GeneratorPhaseCPowerFactor "The power factor of phases C of the generator.";
CM_ SG_ 2365455358 GeneratorPhaseCReactivePower "The reactive power delivered by phase C of the generator";
CM_ SG_ 2365455614 GeneratorPhaseCApparentPower "The apparent power delivered by phase C of the generator.";
CM_ SG_ 2365455614 GeneratorPhaseCRealPower "The real power delivered by phase C of the generator.";
CM_ SG_ 2365455870 GeneratorPhaseCACRMSCurrent "RMS current measured at the generator phase C output.";
CM_ SG_ 2365455870 GeneratorPhaseCACFrequency "AC frequency measured at the generator phase C output.";
CM_ SG_ 2365455870 GnrtrPhsCLneNeutralACRMSVoltage "Line to Neutral RMS voltage measured at the generator phase C output.";
CM_ SG_ 2365455870 GnrtrPhseCALineLineACRMSVoltage "Line to Line RMS voltage measured at the generator phase CA output.";
CM_ SG_ 2365456126 GnratorPhaseBPowerFactorLagging "Lead/lag status for generator phase B power factor.

00 Leading
01 Lagging
10 Error
11 Not Available or Not Installed";
CM_ SG_ 2365456126 GeneratorPhaseBPowerFactor "The power factor of phases B of the generator.";
CM_ SG_ 2365456126 GeneratorPhaseBReactivePower "The reactive power delivered by phase B of the generator";
CM_ SG_ 2365456382 GeneratorPhaseBApparentPower "The apparent power delivered by phase B of the generator.";
CM_ SG_ 2365456382 GeneratorPhaseBRealPower "The real power delivered by phase B of the generator.";
CM_ SG_ 2365456638 GeneratorPhaseBACRMSCurrent "RMS current measured at the generator phase B output.";
CM_ SG_ 2365456638 GeneratorPhaseBACFrequency "AC frequency measured at the generator phase B output.";
CM_ SG_ 2365456638 GnrtrPhsBLneNeutralACRMSVoltage "Line to Neutral RMS voltage measured at the generator phase B output.";
CM_ SG_ 2365456638 GnrtrPhseBCLineLineACRMSVoltage "Line to Line RMS voltage measured at the generator phase BC output.";
CM_ SG_ 2365456894 GnratorPhaseAPowerFactorLagging "Lead/lag status for generator phase A power factor.

00 Leading
01 Lagging
10 Error
11 Not Available or Not Installed";
CM_ SG_ 2365456894 GeneratorPhaseAPowerFactor "The power factor of phase A of the generator.";
CM_ SG_ 2365456894 GeneratorPhaseAReactivePower "The reactive power delivered by phase A of the generator";
CM_ SG_ 2365457150 GeneratorPhaseAApparentPower "The apparent power delivered by phase A of the generator.";
CM_ SG_ 2365457150 GeneratorPhaseARealPower "The real power delivered by phase A of the generator.";
CM_ SG_ 2365457406 GeneratorPhaseAACRMSCurrent "RMS current measured at the generator phase A output.";
CM_ SG_ 2365457406 GeneratorPhaseAACFrequency "AC frequency measured at the generator phase A output.";
CM_ SG_ 2365457406 GnrtrPhsALneNeutralACRMSVoltage "Line to Neutral RMS voltage measured at the generator phase A output.";
CM_ SG_ 2365457406 GnrtrPhseABLineLineACRMSVoltage "Line to Line RMS voltage measured at the generator phase AB output.";
CM_ SG_ 2365458174 GeneratorAverageACRMSCurrent "Average RMS current measured at the generator output.";
CM_ SG_ 2365458174 GeneratorAverageACFrequency "Average AC frequency measured at the generator output.";
CM_ SG_ 2365458174 GnrtrAvrgLneNeutralACRMSVoltage "The average Line to Neutral AC RMS voltage measured at the Generator output.";
CM_ SG_ 2365458174 GnrtrAvrageLineLineACRMSVoltage "Average Line to Line RMS voltage measured at the generator output.";
CM_ SG_ 2365450238 Bus1_UtilityACPhaseDifference "The phase difference between the Bus #1 voltage and Utility voltage.";
CM_ SG_ 2365450238 Bus1_UtilityInSync "Indicator of whether Bus #1 and Utility are properly synchronized for paralleling. This indicator will be based on parameters such as Voltage Match, Frequency Match, and Phase Match.
00 Not synchronized
01 Synchronized
10 Error
11 Not Available ...";
CM_ SG_ 2365450238 Bus1_UtilityVoltageMatch "Indicator of whether voltage difference between Bus #1 and Utility is adequate for paralleling. This indicator will be based on the measured AC voltages qualified using parameters such as Voltage Tolerance.
00 Voltages do not match
01 Voltages ...";
CM_ SG_ 2365450238 Bus1_UtilityFrequencyMatch "Indicator of whether frequency difference between Bus #1 and Utility is adequate for paralleling. This indicator will be based on the measured AC frequencies qualified using parameters such as Frequency Tolerance, Phase Tolerance, and Dwell Time.
 ...";
CM_ SG_ 2365450238 Bus1_UtilityPhaseMatch "Indicator of whether phase difference between Bus #1 and Utility is adequate for paralleling. This indicator will be based on the measured AC phase difference qualified using parameters such as Phase Tolerance and Dwell Time.
00 Phases do not match
 ...";
CM_ SG_ 2365450238 Bus1_UtilityDeadBus "Indicator of whether Bus #1 is considered dead for closing to the utility. This indicator will be based on parameters such as Bus #1 Voltage and dead bus threshold values.
00 Bus is not dead
01 Bus is dead
10 Error
11 Not Available or Not ...";
CM_ SG_ 2365450750 Bus1PhaseCACFrequency "AC frequency measured at bus #1 phase C.";
CM_ SG_ 2365450750 Bs1PhseCLineNeutralACRMSVoltage "Line to Neutral RMS voltage measured at bus #1 phase C.";
CM_ SG_ 2365450750 Bus1PhaseCALineLineACRMSVoltage "Line to Line RMS voltage measured at bus #1 phase CA.";
CM_ SG_ 2365451006 Bus1PhaseBACFrequency "AC frequency measured at bus #1 phase B.";
CM_ SG_ 2365451006 Bs1PhseBLineNeutralACRMSVoltage "Line to Neutral RMS voltage measured at bus #1 phase B.";
CM_ SG_ 2365451006 Bus1PhaseBCLineLineACRMSVoltage "Line to Line RMS voltage measured at bus #1 phase BC.";
CM_ SG_ 2365451262 Bus1PhaseAACFrequency "AC frequency measured at bus #1 phase A.";
CM_ SG_ 2365451262 Bs1PhseALineNeutralACRMSVoltage "Line to Neutral RMS voltage measured at bus #1 phase A.";
CM_ SG_ 2365451262 Bus1PhaseABLineLineACRMSVoltage "Line to Line RMS voltage measured at bus #1 phase AB.";
CM_ SG_ 2365450494 Bus1_GeneratorACPhaseDifference "The phase difference between the Bus #1 voltage and Generator voltage.";
CM_ SG_ 2365450494 Bus1_GeneratorInSync "Indicator of whether Bus #1 and Generator are properly synchronized for paralleling. This indicator will be based on parameters such as Voltage Match, Frequency Match, and Phase Match.
00 Not synchronized
01 Synchronized
10 Error
11 Not ...";
CM_ SG_ 2365450494 Bus1_GeneratorVoltageMatch "Indicator of whether voltage difference between Bus #1 and Generator is adequate for paralleling. This indicator will be based on the measured AC voltages qualified using parameters such as Voltage Tolerance.
00 Voltages do not match
01 Voltages ...";
CM_ SG_ 2365450494 Bus1_GeneratorFrequencyMatch "Indicator of whether frequency difference between Bus #1 and Generator is adequate for paralleling. This indicator will be based on the measured AC frequencies qualified using parameters such as Frequency Tolerance, Phase Tolerance, and Dwell Time.
 ...";
CM_ SG_ 2365450494 Bus1_GeneratorPhaseMatch "Indicator of whether phase difference between Bus #1 and Generator is adequate for paralleling. This indicator will be based on the measured AC phase difference qualified using parameters such as Phase Tolerance and Dwell Time.
00 Phases do not ...";
CM_ SG_ 2365450494 Bus1_GeneratorDeadBus "Indicator of whether Bus #1 is considered dead for closing to the generator. This indicator will be based on parameters such as Bus #1 Voltage and dead bus threshold values.
00 Bus is not dead
01 Bus is dead
10 Error
11 Not Available or Not ...";
CM_ SG_ 2365451518 Bus1AverageACFrequency "Average AC frequency measured at bus #1.";
CM_ SG_ 2365451518 Bs1AvrgeLineNeutralACRMSVoltage "The average Line to Neutral AC RMS voltage measured at bus #1 .";
CM_ SG_ 2365451518 Bus1AverageLineLineACRMSVoltage "Average Line to Line RMS voltage measured at bus #1 .";
CM_ BO_ 2365459966 "This message is sent by the Master of a Working Set to identify how many members there are in said set.";
CM_ BO_ 2566838526 "Message that is used to assign a source address to a specific Controller Application Name.";
CM_ SG_ 2566838526 AddressAssignment "The source address that is to be assigned to the CA that has the NAME corresponding to the one conveyed in the first eight bytes of this Commanded Address message.";
CM_ SG_ 2566838526 IndustryGroup "0 = Global; 
   1  = On-Highway; 
   2  = Agricultural and Forestry; 
   3  = Construction; 
   4  = Marine;
   5  = Industrial - Process
          Control - Stationary (Gen-Sets)
   6  = Reserve for SAE
   7  = Reserve for SAE";
CM_ SG_ 2566838526 ManufacturerCode "Assigned by NMEA 2000 Committee";
CM_ BO_ 2364473086 "Message used to claim an address for a Controller Application.";
CM_ SG_ 2364473086 IndustryGroup "0 = Global; 
   1  = On-Highway; 
   2  = Agricultural and Forestry; 
   3  = Construction; 
   4  = Marine;
   5  = Industrial - Process
          Control - Stationary (Gen-Sets)
   6  = Reserve for SAE
   7  = Reserve for SAE";
CM_ SG_ 2364473086 ManufacturerCode "Assigned by NMEA 2000 Committee";
CM_ BO_ 2362113790 "The Transfer PGN provides a mechanism for reporting multiple data sets for a given PGN.";
CM_ SG_ 2362113790 ShrtNameOfActualReportingDevice "Subset of the 64-bit NAME (SPN 2848), consisting of the most significant 32 bits, which identifies the controller application.  It excludes the manufacturer code and identity number.";
CM_ SG_ 2362113790 LengthOfDataForTheReportedPGN "Length of data reported with the associated PGN via the Transfer PGN.";
CM_ SG_ 2362113790 PGNofRequstedInformation "PGN associated with this transfer message";
CM_ BO_ 2364276478 "Used for the transfer of data associated with Parameter Groups that have more than 8 bytes of data.";
CM_ SG_ 2364276478 SequenceNumber "Sequence Number (TP.DT)";
CM_ BO_ 2364342014 "Used for the transfer of Parameter Groups that have 9 or more bytes of data.";
CM_ SG_ 2364342014 TotalNumberOfPacketsEoMA "Total number of packets received for RTS/CTS message.";
CM_ SG_ 2364342014 TotalMessageSizeEoMA "Total message size (in bytes) received for RTS/CTS message.";
CM_ SG_ 2364342014 TotalMessageSizeBAM "Total message size (in bytes) for BAM message.";
CM_ SG_ 2364342014 TotalNumberOfPacketsBAM "Total number of packets for BAM message.";
CM_ SG_ 2364342014 ConnectionAbortReason "Reason for connection abort message.";
CM_ SG_ 2364342014 NextPacketNumberToBeSent "Next Packet Number to be sent (TP.CM_CTS)";
CM_ SG_ 2364342014 NumberOfPacketsThatCanBeSent "Number of Packets that can be sent (TP.CM_CTS)";
CM_ SG_ 2364342014 PGNumber "Requested PGN in the TP.CM_RTS message";
CM_ SG_ 2364342014 MaximumNumberOfPackets "Maximum number of packets for RTS/CTS message.";
CM_ SG_ 2364342014 TotalNumberOfPackets "Total number of packets for RTS/CTS message.";
CM_ SG_ 2364342014 TotalMessageSize "Total message size (in bytes) for RTS/CTS message.";
CM_ SG_ 2364342014 ControlByte "Control byte (I.e. Group Function) associated with the Transport Protocol - Connection Management (PGN 60,416)";
CM_ BO_ 2362048254 "Used to Request a PGN from network device or devices and to specify whether the response should use the Transfer PGN or not. PGN and data set for all devices it is tasked with reporting.";
CM_ SG_ 2362048254 ParameterGroupNumber "PGN which is requested by Request2 message";
CM_ SG_ 2362048254 UseTransferMode "Requester is to respond via the Transfer PGN";
CM_ BO_ 2364210942 "This message type, identified by the PGN, provides the capability to request information globally or from a specific destination.";
CM_ SG_ 2364210942 ParameterGroupNumber "Whenever it is necessary to identify a Parameter Group Number in the data field of a CAN data frame, it will be expressed in 24 bits.";
CM_ BO_ 2499635966 "Combination of specific axle group and the weight imposed on that axle group.";
CM_ SG_ 2499635966 AdditionalAxleGroupLocation "Location of the axle group, listed from front of the vehicle to rear.  If the value of SPN 4073 is 15, then this SPN is used to indicate the axle group referred to by this PGN. Otherwise, this SPN should be broadcast as 15.
0 = Reserved
1 = Rear ...";
CM_ SG_ 2499635966 AxleGroupWeight "Total mass imposed on the road surface by all the tires in the axle group";
CM_ SG_ 2499635966 AxleGroupLocation "Specific axle group used in conjunction with and when communicating the axle group weight, listed from the front of the vehicle to the rear.
If the value of SPN 5935 is 15, then this SPN is used to indicate the axle group referred to by this PGN ...";
CM_ BO_ 2633853438 "Indicates axle group calibration weights";
CM_ SG_ 2633853438 AdditionalAxleGroupLocation "Location of the axle group, listed from front of the vehicle to rear.  If the value of SPN 4074 is 15, then this SPN is used to indicate the axle group referred to by this PGN. Otherwise, this SPN should be broadcast as 15.
0 = Reserved
1 = Rear ...";
CM_ SG_ 2633853438 AxleGroupFullWeightCalib "The full weight calibration measurement of an axle group";
CM_ SG_ 2633853438 AxleGroupEmptyWeightCalib "The empty weight calibration measurement of an axle group";
CM_ SG_ 2633853438 AxleGroupLocation "Specific axle group used in conjunction with and when communicating the axle group calibration, listed from the front of the vehicle to the rear.
If the value of SPN 5936 is 15, then this SPN is used to indicate the axle group referred to by this ...";
CM_ BO_ 2432520702 "Transmit status information from the Master ECU to an electronic thermostat";
CM_ SG_ 2432520702 DsrdAftrclrClntThermostatOpening "Used to transmit the desired position of the low temperature aftercooler temperature control valve.  0% represents the thermostat allows flow to completely bypass the aftercooler and 100% represents the flow is fully through the aftercooler.   If ...";
CM_ SG_ 2432520702 DsrdAftercoolerCoolantIntakeTemp "Indicates the desired temperature of the fluid in the low temperature aftercooler circuit to an electronic thermostat.  If the aftercooler coolant thermostat valve is operating in position control mode (see SPN 4198) then this value should be 0xFF.";
CM_ SG_ 2432520702 AftercoolerCoolantThermostatMode "Specifies if the aftercooler coolant thermostat valve will operate in temperature control mode or position control mode.

00 = temperature control mode
01 = position control mode (used for service only)
10 = reserved
11 = don't care/reserved";
CM_ BO_ 2566745086 "Indicates which axle groups are included in the current weight calculation";
CM_ SG_ 2566745086 RarDriveAxleGroupWeightAvailable "Indicates if a second (or rear) drive axle group weight is available.
00 = Rear drive axle group not present
01 = Rear drive axle group present
10 = Reserved
11 = Not available / not applicable
Note:  If there is only one drive axle, use SPN ...";
CM_ SG_ 2566745086 RarSteerAxleGroupWeightAvailable "Indicates if a second (or rear) steer axle group weight is available.
00 = Rear Steer axle group not present
01 = Rear Steer axle group present
10 = Reserved
11 = Not available / not applicable
Note:  If there is only one steer axle, use SPN ...";
CM_ SG_ 2566745086 AddtnlTrlrAxlGrupWeightAvailable "Indicates the availability of the additional trailer axle group for purposes of weight measurement

00 = Additional trailer axle group not present
01 = Additional trailer axle group present
10 = Reserved
11 = Not available / not applicable";
CM_ SG_ 2566745086 TrailerHAxleGroupWeightAvailable "Indicates the availability of the trailer H axle group for purposes of weight measurement

00 = Trailer H axle group not present
01 = Trailer H axle group present
10 = Reserved
11 = Not available / not applicable";
CM_ SG_ 2566745086 TrailerGAxleGroupWeightAvailable "Indicates the availability of the trailer G axle group for purposes of weight measurement

00 = Trailer G axle group not present
01 = Trailer G axle group present
10 = Reserved
11 = Not available / not applicable";
CM_ SG_ 2566745086 TrailerFAxleGroupWeightAvailable "Indicates the availability of the trailer F axle group for purposes of weight measurement

00 = Trailer F axle group not present
01 = Trailer F axle group present
10 = Reserved
11 = Not available / not applicable";
CM_ SG_ 2566745086 TrailerEAxleGroupWeightAvailable "Indicates the availability of the trailer E axle group for purposes of weight measurement

00 = Trailer E axle group not present
01 = Trailer E axle group present
10 = Reserved
11 = Not available / not applicable";
CM_ SG_ 2566745086 TrailerDAxleGroupWeightAvailable "Indicates the availability of the trailer D axle group for purposes of weight measurement

00 = Trailer D axle group not present
01 = Trailer D axle group present
10 = Reserved
11 = Not available / not applicable";
CM_ SG_ 2566745086 TrailerCAxleGroupWeightAvailable "Indicates the availability of the trailer C axle group for purposes of weight measurement

00 = Trailer C axle group not present
01 = Trailer C axle group present
10 = Reserved
11 = Not available / not applicable";
CM_ SG_ 2566745086 TrailerBAxleGroupWeightAvailable "Indicates the availability of the trailer B axle group for purposes of weight measurement

00 = Trailer B axle group not present
01 = Trailer B axle group present
10 = Reserved
11 = Not available / not applicable";
CM_ SG_ 2566745086 TrailerAAxleGroupWeightAvailable "Indicates the availability of the trailer A axle group for purposes of weight measurement

00 = Trailer A axle group not present
01 = Trailer A axle group present
10 = Reserved
11 = Not available / not applicable";
CM_ SG_ 2566745086 AddtnlTrctrAxlGrpWeightAvailable "Indicates the availability of the additional tractor axle group for purposes of weight measurement

00 = Additional tractor axle group not present
01 = Additional tractor axle group present
10 = Reserved
11 = Not available / not applicable";
CM_ SG_ 2566745086 TagAxleGroupWeightAvailable "Indicates the availability of the tag axle group for purposes of weight measurement

00 = Tag axle group not present
01 = Tag axle group present
10 = Reserved
11 = Not available / not applicable";
CM_ SG_ 2566745086 DriveAxleGroupWeightAvailable "Indicates the availability of the sole or forward-most drive axle group for purposes of weight measurement
00 = Drive axle group not present
01 = Drive axle group present
10 = Reserved
11 = Not available / not applicable
If there is only one ...";
CM_ SG_ 2566745086 LiftAxleGroupWeightAvailable "Indicates the availability of the lift axle group for purposes of weight measurement

00 = Lift axle group not present
01 = Lift axle group present
10 = Reserved
11 = Not available / not applicable";
CM_ SG_ 2566745086 SteerAxleGroupWeightAvailable "Indicates the availability of the sole or forward-most steer axle group for purposes of weight measurement
00 = Steer axle group not present
01 = Steer axle group present
10 = Reserved
11 = Not available / not applicable
If there is only one ...";
CM_ BO_ 2566739198 "Previously Active DTCs that are classified as class C severity.";
CM_ SG_ 2566739198 FlashRedStopLamp "This parameter provides the capability to flash the RSL";
CM_ SG_ 2566739198 FlashProtectLamp "This parameter provides the capability to flash the engine protect lamp";
CM_ SG_ 2566739198 FlashMalfuncIndicatorLamp "This parameter provides the capability to flash the MIL";
CM_ SG_ 2566739198 FlashAmberWarningLamp "This parameter provides the capability to flash the AWL";
CM_ SG_ 2566739198 MalfunctionIndicatorLampStatus "A lamp used to relay only emissions-related trouble code information. This lamp is only illuminated when there is an emission-related trouble code active.";
CM_ SG_ 2566739198 AmberWarningLampStatus "This lamp is used to relay trouble code information that is reporting a problem with the vehicle system but the vehicle need not be immediately stopped.";
CM_ SG_ 2566739198 RedStopLampState "This lamp is used to relay trouble code information that is of a severe enough condition that it warrants stopping the vehicle.";
CM_ SG_ 2566739198 ProtectLampStatus "This lamp is used to relay trouble code information that is reporting a problem with a vehicle system that is most probably not electronic subsystem related. For instance, engine coolant temperature is exceeding its prescribed temperature range.";
CM_ SG_ 2566739198 DTC5 "Diagnostic Trouble Code";
CM_ SG_ 2566739198 DTC4 "Diagnostic Trouble Code";
CM_ SG_ 2566739198 DTC3 "Diagnostic Trouble Code";
CM_ SG_ 2566739198 DTC2 "Diagnostic Trouble Code";
CM_ SG_ 2566739198 DTC1 "Diagnostic Trouble Code";
CM_ BO_ 2566739454 "Confirmed and Active DTCs that are classified as class C severity.";
CM_ SG_ 2566739454 FlashRedStopLamp "This parameter provides the capability to flash the RSL";
CM_ SG_ 2566739454 FlashProtectLamp "This parameter provides the capability to flash the engine protect lamp";
CM_ SG_ 2566739454 FlashMalfuncIndicatorLamp "This parameter provides the capability to flash the MIL";
CM_ SG_ 2566739454 FlashAmberWarningLamp "This parameter provides the capability to flash the AWL";
CM_ SG_ 2566739454 MalfunctionIndicatorLampStatus "A lamp used to relay only emissions-related trouble code information. This lamp is only illuminated when there is an emission-related trouble code active.";
CM_ SG_ 2566739454 AmberWarningLampStatus "This lamp is used to relay trouble code information that is reporting a problem with the vehicle system but the vehicle need not be immediately stopped.";
CM_ SG_ 2566739454 RedStopLampState "This lamp is used to relay trouble code information that is of a severe enough condition that it warrants stopping the vehicle.";
CM_ SG_ 2566739454 ProtectLampStatus "This lamp is used to relay trouble code information that is reporting a problem with a vehicle system that is most probably not electronic subsystem related. For instance, engine coolant temperature is exceeding its prescribed temperature range.";
CM_ SG_ 2566739454 DTC5 "Diagnostic Trouble Code";
CM_ SG_ 2566739454 DTC4 "Diagnostic Trouble Code";
CM_ SG_ 2566739454 DTC3 "Diagnostic Trouble Code";
CM_ SG_ 2566739454 DTC2 "Diagnostic Trouble Code";
CM_ SG_ 2566739454 DTC1 "Diagnostic Trouble Code";
CM_ BO_ 2566739710 "Pending DTCs that are classified as class C severity.";
CM_ SG_ 2566739710 FlashRedStopLamp "This parameter provides the capability to flash the RSL";
CM_ SG_ 2566739710 FlashProtectLamp "This parameter provides the capability to flash the engine protect lamp";
CM_ SG_ 2566739710 FlashMalfuncIndicatorLamp "This parameter provides the capability to flash the MIL";
CM_ SG_ 2566739710 FlashAmberWarningLamp "This parameter provides the capability to flash the AWL";
CM_ SG_ 2566739710 MalfunctionIndicatorLampStatus "A lamp used to relay only emissions-related trouble code information. This lamp is only illuminated when there is an emission-related trouble code active.";
CM_ SG_ 2566739710 AmberWarningLampStatus "This lamp is used to relay trouble code information that is reporting a problem with the vehicle system but the vehicle need not be immediately stopped.";
CM_ SG_ 2566739710 RedStopLampState "This lamp is used to relay trouble code information that is of a severe enough condition that it warrants stopping the vehicle.";
CM_ SG_ 2566739710 ProtectLampStatus "This lamp is used to relay trouble code information that is reporting a problem with a vehicle system that is most probably not electronic subsystem related. For instance, engine coolant temperature is exceeding its prescribed temperature range.";
CM_ SG_ 2566739710 DTC5 "Diagnostic Trouble Code";
CM_ SG_ 2566739710 DTC4 "Diagnostic Trouble Code";
CM_ SG_ 2566739710 DTC3 "Diagnostic Trouble Code";
CM_ SG_ 2566739710 DTC2 "Diagnostic Trouble Code";
CM_ SG_ 2566739710 DTC1 "Diagnostic Trouble Code";
CM_ BO_ 2566739966 "Previously Active DTCs that are classified as class B2 severity.";
CM_ SG_ 2566739966 FlashRedStopLamp "This parameter provides the capability to flash the RSL";
CM_ SG_ 2566739966 FlashProtectLamp "This parameter provides the capability to flash the engine protect lamp";
CM_ SG_ 2566739966 FlashMalfuncIndicatorLamp "This parameter provides the capability to flash the MIL";
CM_ SG_ 2566739966 FlashAmberWarningLamp "This parameter provides the capability to flash the AWL";
CM_ SG_ 2566739966 MalfunctionIndicatorLampStatus "A lamp used to relay only emissions-related trouble code information. This lamp is only illuminated when there is an emission-related trouble code active.";
CM_ SG_ 2566739966 AmberWarningLampStatus "This lamp is used to relay trouble code information that is reporting a problem with the vehicle system but the vehicle need not be immediately stopped.";
CM_ SG_ 2566739966 RedStopLampState "This lamp is used to relay trouble code information that is of a severe enough condition that it warrants stopping the vehicle.";
CM_ SG_ 2566739966 ProtectLampStatus "This lamp is used to relay trouble code information that is reporting a problem with a vehicle system that is most probably not electronic subsystem related. For instance, engine coolant temperature is exceeding its prescribed temperature range.";
CM_ SG_ 2566739966 DTC5 "Diagnostic Trouble Code";
CM_ SG_ 2566739966 DTC4 "Diagnostic Trouble Code";
CM_ SG_ 2566739966 DTC3 "Diagnostic Trouble Code";
CM_ SG_ 2566739966 DTC2 "Diagnostic Trouble Code";
CM_ SG_ 2566739966 DTC1 "Diagnostic Trouble Code";
CM_ BO_ 2566740222 "Confirmed and Active DTCs that are classified as class B2 severity.";
CM_ SG_ 2566740222 FlashRedStopLamp "This parameter provides the capability to flash the RSL";
CM_ SG_ 2566740222 FlashProtectLamp "This parameter provides the capability to flash the engine protect lamp";
CM_ SG_ 2566740222 FlashMalfuncIndicatorLamp "This parameter provides the capability to flash the MIL";
CM_ SG_ 2566740222 FlashAmberWarningLamp "This parameter provides the capability to flash the AWL";
CM_ SG_ 2566740222 MalfunctionIndicatorLampStatus "A lamp used to relay only emissions-related trouble code information. This lamp is only illuminated when there is an emission-related trouble code active.";
CM_ SG_ 2566740222 AmberWarningLampStatus "This lamp is used to relay trouble code information that is reporting a problem with the vehicle system but the vehicle need not be immediately stopped.";
CM_ SG_ 2566740222 RedStopLampState "This lamp is used to relay trouble code information that is of a severe enough condition that it warrants stopping the vehicle.";
CM_ SG_ 2566740222 ProtectLampStatus "This lamp is used to relay trouble code information that is reporting a problem with a vehicle system that is most probably not electronic subsystem related. For instance, engine coolant temperature is exceeding its prescribed temperature range.";
CM_ SG_ 2566740222 DTC5 "Diagnostic Trouble Code";
CM_ SG_ 2566740222 DTC4 "Diagnostic Trouble Code";
CM_ SG_ 2566740222 DTC3 "Diagnostic Trouble Code";
CM_ SG_ 2566740222 DTC2 "Diagnostic Trouble Code";
CM_ SG_ 2566740222 DTC1 "Diagnostic Trouble Code";
CM_ BO_ 2566740478 "Pending DTCs that are classified as class B2 severity.";
CM_ SG_ 2566740478 FlashRedStopLamp "This parameter provides the capability to flash the RSL";
CM_ SG_ 2566740478 FlashProtectLamp "This parameter provides the capability to flash the engine protect lamp";
CM_ SG_ 2566740478 FlashMalfuncIndicatorLamp "This parameter provides the capability to flash the MIL";
CM_ SG_ 2566740478 FlashAmberWarningLamp "This parameter provides the capability to flash the AWL";
CM_ SG_ 2566740478 MalfunctionIndicatorLampStatus "A lamp used to relay only emissions-related trouble code information. This lamp is only illuminated when there is an emission-related trouble code active.";
CM_ SG_ 2566740478 AmberWarningLampStatus "This lamp is used to relay trouble code information that is reporting a problem with the vehicle system but the vehicle need not be immediately stopped.";
CM_ SG_ 2566740478 RedStopLampState "This lamp is used to relay trouble code information that is of a severe enough condition that it warrants stopping the vehicle.";
CM_ SG_ 2566740478 ProtectLampStatus "This lamp is used to relay trouble code information that is reporting a problem with a vehicle system that is most probably not electronic subsystem related. For instance, engine coolant temperature is exceeding its prescribed temperature range.";
CM_ SG_ 2566740478 DTC5 "Diagnostic Trouble Code";
CM_ SG_ 2566740478 DTC4 "Diagnostic Trouble Code";
CM_ SG_ 2566740478 DTC3 "Diagnostic Trouble Code";
CM_ SG_ 2566740478 DTC2 "Diagnostic Trouble Code";
CM_ SG_ 2566740478 DTC1 "Diagnostic Trouble Code";
CM_ BO_ 2566740734 "Previously Active DTCs that are classified as class B1 severity.";
CM_ SG_ 2566740734 FlashRedStopLamp "This parameter provides the capability to flash the RSL";
CM_ SG_ 2566740734 FlashProtectLamp "This parameter provides the capability to flash the engine protect lamp";
CM_ SG_ 2566740734 FlashMalfuncIndicatorLamp "This parameter provides the capability to flash the MIL";
CM_ SG_ 2566740734 FlashAmberWarningLamp "This parameter provides the capability to flash the AWL";
CM_ SG_ 2566740734 MalfunctionIndicatorLampStatus "A lamp used to relay only emissions-related trouble code information. This lamp is only illuminated when there is an emission-related trouble code active.";
CM_ SG_ 2566740734 AmberWarningLampStatus "This lamp is used to relay trouble code information that is reporting a problem with the vehicle system but the vehicle need not be immediately stopped.";
CM_ SG_ 2566740734 RedStopLampState "This lamp is used to relay trouble code information that is of a severe enough condition that it warrants stopping the vehicle.";
CM_ SG_ 2566740734 ProtectLampStatus "This lamp is used to relay trouble code information that is reporting a problem with a vehicle system that is most probably not electronic subsystem related. For instance, engine coolant temperature is exceeding its prescribed temperature range.";
CM_ SG_ 2566740734 DTC5 "Diagnostic Trouble Code";
CM_ SG_ 2566740734 DTC4 "Diagnostic Trouble Code";
CM_ SG_ 2566740734 DTC3 "Diagnostic Trouble Code";
CM_ SG_ 2566740734 DTC2 "Diagnostic Trouble Code";
CM_ SG_ 2566740734 DTC1 "Diagnostic Trouble Code";
CM_ BO_ 2566740990 "Confirmed and Active DTCs that are classified as class B1 severity.";
CM_ SG_ 2566740990 FlashRedStopLamp "This parameter provides the capability to flash the RSL";
CM_ SG_ 2566740990 FlashProtectLamp "This parameter provides the capability to flash the engine protect lamp";
CM_ SG_ 2566740990 FlashMalfuncIndicatorLamp "This parameter provides the capability to flash the MIL";
CM_ SG_ 2566740990 FlashAmberWarningLamp "This parameter provides the capability to flash the AWL";
CM_ SG_ 2566740990 MalfunctionIndicatorLampStatus "A lamp used to relay only emissions-related trouble code information. This lamp is only illuminated when there is an emission-related trouble code active.";
CM_ SG_ 2566740990 AmberWarningLampStatus "This lamp is used to relay trouble code information that is reporting a problem with the vehicle system but the vehicle need not be immediately stopped.";
CM_ SG_ 2566740990 RedStopLampState "This lamp is used to relay trouble code information that is of a severe enough condition that it warrants stopping the vehicle.";
CM_ SG_ 2566740990 ProtectLampStatus "This lamp is used to relay trouble code information that is reporting a problem with a vehicle system that is most probably not electronic subsystem related. For instance, engine coolant temperature is exceeding its prescribed temperature range.";
CM_ SG_ 2566740990 DTC5 "Diagnostic Trouble Code";
CM_ SG_ 2566740990 DTC4 "Diagnostic Trouble Code";
CM_ SG_ 2566740990 DTC3 "Diagnostic Trouble Code";
CM_ SG_ 2566740990 DTC2 "Diagnostic Trouble Code";
CM_ SG_ 2566740990 DTC1 "Diagnostic Trouble Code";
CM_ BO_ 2566741246 "Pending DTCs that are classified as class B1 severity.";
CM_ SG_ 2566741246 FlashRedStopLamp "This parameter provides the capability to flash the RSL";
CM_ SG_ 2566741246 FlashProtectLamp "This parameter provides the capability to flash the engine protect lamp";
CM_ SG_ 2566741246 FlashMalfuncIndicatorLamp "This parameter provides the capability to flash the MIL";
CM_ SG_ 2566741246 FlashAmberWarningLamp "This parameter provides the capability to flash the AWL";
CM_ SG_ 2566741246 MalfunctionIndicatorLampStatus "A lamp used to relay only emissions-related trouble code information. This lamp is only illuminated when there is an emission-related trouble code active.";
CM_ SG_ 2566741246 AmberWarningLampStatus "This lamp is used to relay trouble code information that is reporting a problem with the vehicle system but the vehicle need not be immediately stopped.";
CM_ SG_ 2566741246 RedStopLampState "This lamp is used to relay trouble code information that is of a severe enough condition that it warrants stopping the vehicle.";
CM_ SG_ 2566741246 ProtectLampStatus "This lamp is used to relay trouble code information that is reporting a problem with a vehicle system that is most probably not electronic subsystem related. For instance, engine coolant temperature is exceeding its prescribed temperature range.";
CM_ SG_ 2566741246 DTC5 "Diagnostic Trouble Code";
CM_ SG_ 2566741246 DTC4 "Diagnostic Trouble Code";
CM_ SG_ 2566741246 DTC3 "Diagnostic Trouble Code";
CM_ SG_ 2566741246 DTC2 "Diagnostic Trouble Code";
CM_ SG_ 2566741246 DTC1 "Diagnostic Trouble Code";
CM_ BO_ 2566741502 "Previously Active DTCs that are classified as class A severity.";
CM_ SG_ 2566741502 FlashRedStopLamp "This parameter provides the capability to flash the RSL";
CM_ SG_ 2566741502 FlashProtectLamp "This parameter provides the capability to flash the engine protect lamp";
CM_ SG_ 2566741502 FlashMalfuncIndicatorLamp "This parameter provides the capability to flash the MIL";
CM_ SG_ 2566741502 FlashAmberWarningLamp "This parameter provides the capability to flash the AWL";
CM_ SG_ 2566741502 MalfunctionIndicatorLampStatus "A lamp used to relay only emissions-related trouble code information. This lamp is only illuminated when there is an emission-related trouble code active.";
CM_ SG_ 2566741502 AmberWarningLampStatus "This lamp is used to relay trouble code information that is reporting a problem with the vehicle system but the vehicle need not be immediately stopped.";
CM_ SG_ 2566741502 RedStopLampState "This lamp is used to relay trouble code information that is of a severe enough condition that it warrants stopping the vehicle.";
CM_ SG_ 2566741502 ProtectLampStatus "This lamp is used to relay trouble code information that is reporting a problem with a vehicle system that is most probably not electronic subsystem related. For instance, engine coolant temperature is exceeding its prescribed temperature range.";
CM_ SG_ 2566741502 DTC5 "Diagnostic Trouble Code";
CM_ SG_ 2566741502 DTC4 "Diagnostic Trouble Code";
CM_ SG_ 2566741502 DTC3 "Diagnostic Trouble Code";
CM_ SG_ 2566741502 DTC2 "Diagnostic Trouble Code";
CM_ SG_ 2566741502 DTC1 "Diagnostic Trouble Code";
BA_DEF_ SG_  "SigType" ENUM  "Default","Range","RangeSigned","ASCII","Discrete","Control","ReferencePGN","DTC","StringDelimiter","StringLength","StringLengthControl","MessageCounter","MessageChecksum";
BA_DEF_ SG_  "GenSigStartValue" INT 0 10000;
BA_DEF_ SG_  "GenSigSendType" ENUM  "Cyclic","OnWrite","OnWriteWithRepetition","OnChange","OnChangeWithRepetition","IfActive","IfActiveWithRepetition","NoSigSendType";
BA_DEF_ SG_  "GenSigILSupport" ENUM  "No","Yes";
BA_DEF_ SG_  "GenSigEVName" STRING ;
BA_DEF_ SG_  "SPN" INT 0 524287;
BA_DEF_ BO_  "GenMsgStartDelayTime" INT 0 100000;
BA_DEF_ BO_  "GenMsgILSupport" ENUM  "No","Yes";
BA_DEF_ BO_  "GenMsgRequestable" INT 0 1;
BA_DEF_ BO_  "GenMsgSendType" ENUM  "cyclic","NotUsed","NotUsed","NotUsed","NotUsed","NotUsed","NotUsed","IfActive","noMsgSendType";
BA_DEF_ BO_  "VFrameFormat" ENUM  "StandardCAN","ExtendedCAN","reserved","J1939PG";
BA_DEF_ BO_  "GenMsgCycleTime" INT 0 3600000;
BA_DEF_ SG_  "SystemSignalLongSymbol" STRING ;
BA_DEF_DEF_  "SigType" "Default";
BA_DEF_DEF_  "GenSigStartValue" 0;
BA_DEF_DEF_  "GenSigSendType" "NoSigSendType";
BA_DEF_DEF_  "GenSigILSupport" "Yes";
BA_DEF_DEF_  "GenSigEVName" "Env@Nodename_@Signame";
BA_DEF_DEF_  "SPN" 0;
BA_DEF_DEF_  "GenMsgStartDelayTime" 0;
BA_DEF_DEF_  "GenMsgILSupport" "Yes";
BA_DEF_DEF_  "GenMsgRequestable" 1;
BA_DEF_DEF_  "GenMsgSendType" "noMsgSendType";
BA_DEF_DEF_  "VFrameFormat" "J1939PG";
BA_DEF_DEF_  "GenMsgCycleTime" 0;
BA_DEF_DEF_  "SystemSignalLongSymbol" "";
BA_ "GenMsgCycleTime" BO_ 2365454334 100;
BA_ "GenMsgSendType" BO_ 2365454334 0;
BA_ "GenMsgCycleTime" BO_ 2365454590 100;
BA_ "GenMsgSendType" BO_ 2365454590 0;
BA_ "GenMsgCycleTime" BO_ 2365451774 100;
BA_ "GenMsgSendType" BO_ 2365451774 0;
BA_ "GenMsgCycleTime" BO_ 2365452030 100;
BA_ "GenMsgSendType" BO_ 2365452030 0;
BA_ "GenMsgCycleTime" BO_ 2365452286 100;
BA_ "GenMsgSendType" BO_ 2365452286 0;
BA_ "GenMsgCycleTime" BO_ 2365452542 100;
BA_ "GenMsgSendType" BO_ 2365452542 0;
BA_ "GenMsgCycleTime" BO_ 2365452798 100;
BA_ "GenMsgSendType" BO_ 2365452798 0;
BA_ "GenMsgCycleTime" BO_ 2365453054 100;
BA_ "GenMsgSendType" BO_ 2365453054 0;
BA_ "GenMsgCycleTime" BO_ 2365453310 100;
BA_ "GenMsgSendType" BO_ 2365453310 0;
BA_ "GenMsgCycleTime" BO_ 2365453566 100;
BA_ "GenMsgSendType" BO_ 2365453566 0;
BA_ "GenMsgCycleTime" BO_ 2365453822 100;
BA_ "GenMsgSendType" BO_ 2365453822 0;
BA_ "GenMsgCycleTime" BO_ 2365454078 100;
BA_ "GenMsgSendType" BO_ 2365454078 0;
BA_ "GenMsgCycleTime" BO_ 2365454846 100;
BA_ "GenMsgSendType" BO_ 2365454846 0;
BA_ "GenMsgCycleTime" BO_ 2365457662 100;
BA_ "GenMsgSendType" BO_ 2365457662 0;
BA_ "GenMsgCycleTime" BO_ 2365457918 100;
BA_ "GenMsgSendType" BO_ 2365457918 0;
BA_ "GenMsgCycleTime" BO_ 2365455102 100;
BA_ "GenMsgSendType" BO_ 2365455102 0;
BA_ "GenMsgCycleTime" BO_ 2365455358 100;
BA_ "GenMsgSendType" BO_ 2365455358 0;
BA_ "GenMsgCycleTime" BO_ 2365455614 100;
BA_ "GenMsgSendType" BO_ 2365455614 0;
BA_ "GenMsgCycleTime" BO_ 2365455870 100;
BA_ "GenMsgSendType" BO_ 2365455870 0;
BA_ "GenMsgCycleTime" BO_ 2365456126 100;
BA_ "GenMsgSendType" BO_ 2365456126 0;
BA_ "GenMsgCycleTime" BO_ 2365456382 100;
BA_ "GenMsgSendType" BO_ 2365456382 0;
BA_ "GenMsgCycleTime" BO_ 2365456638 100;
BA_ "GenMsgSendType" BO_ 2365456638 0;
BA_ "GenMsgCycleTime" BO_ 2365456894 100;
BA_ "GenMsgSendType" BO_ 2365456894 0;
BA_ "GenMsgCycleTime" BO_ 2365457150 100;
BA_ "GenMsgSendType" BO_ 2365457150 0;
BA_ "GenMsgCycleTime" BO_ 2365457406 100;
BA_ "GenMsgSendType" BO_ 2365457406 0;
BA_ "GenMsgCycleTime" BO_ 2365458174 100;
BA_ "GenMsgSendType" BO_ 2365458174 0;
BA_ "GenMsgCycleTime" BO_ 2365450238 100;
BA_ "GenMsgSendType" BO_ 2365450238 0;
BA_ "GenMsgCycleTime" BO_ 2365450750 100;
BA_ "GenMsgSendType" BO_ 2365450750 0;
BA_ "GenMsgCycleTime" BO_ 2365451006 100;
BA_ "GenMsgSendType" BO_ 2365451006 0;
BA_ "GenMsgCycleTime" BO_ 2365451262 100;
BA_ "GenMsgSendType" BO_ 2365451262 0;
BA_ "GenMsgCycleTime" BO_ 2365450494 100;
BA_ "GenMsgSendType" BO_ 2365450494 0;
BA_ "GenMsgCycleTime" BO_ 2365451518 100;
BA_ "GenMsgSendType" BO_ 2365451518 0;
BA_ "GenMsgCycleTime" BO_ 2432520702 1000;
BA_ "GenMsgSendType" BO_ 2432520702 0;
BA_ "SPN" SG_ 2566835710 EngIntakeManifold1Press 102;
BA_ "SigType" SG_ 2566835710 EngIntakeManifold1Press 1;
BA_ "SPN" SG_ 2566835710 FreezeFrameLength 1217;
BA_ "SPN" SG_ 2566835710 EngSpeed 190;
BA_ "SigType" SG_ 2566835710 EngSpeed 1;
BA_ "SPN" SG_ 2566835710 EngTorqueMode 899;
BA_ "SPN" SG_ 2566835710 WheelBasedVehicleSpeed 84;
BA_ "SigType" SG_ 2566835710 WheelBasedVehicleSpeed 1;
BA_ "SPN" SG_ 2566835710 EngPercentLoadAtCurrentSpeed 92;
BA_ "SigType" SG_ 2566835710 EngPercentLoadAtCurrentSpeed 1;
BA_ "SPN" SG_ 2566835710 EngCoolantTemp 110;
BA_ "SigType" SG_ 2566835710 EngCoolantTemp 1;
BA_ "SigType" SG_ 2566835710 DTC1 7;
BA_ "SPN" SG_ 2566764542 ExpandedFreezeFrameLength 3300;
BA_ "SigType" SG_ 2566764542 DTC1 7;
BA_ "SigType" SG_ 2566764286 SPNDataLength3 1;
BA_ "SPN" SG_ 2566764286 SPNSupportTypeSTR1 4102;
BA_ "SPN" SG_ 2566764286 SPNSupportTypeDS1 4101;
BA_ "SPN" SG_ 2566764286 SPNSupportTypeEFF1 4100;
BA_ "SigType" SG_ 2566764286 SPNDataLength2 1;
BA_ "SPN" SG_ 2566764286 SPNDataLength1 4103;
BA_ "SigType" SG_ 2566764286 SPNDataLength1 1;
BA_ "SPN" SG_ 2566764286 SPNSupported1 3297;
BA_ "SPN" SG_ 2566764030 FlashRedStopLamp 3039;
BA_ "SigType" SG_ 2566764030 FlashRedStopLamp 5;
BA_ "SPN" SG_ 2566764030 FlashProtectLamp 3041;
BA_ "SigType" SG_ 2566764030 FlashProtectLamp 5;
BA_ "SPN" SG_ 2566764030 FlashMalfuncIndicatorLamp 3038;
BA_ "SigType" SG_ 2566764030 FlashMalfuncIndicatorLamp 5;
BA_ "SPN" SG_ 2566764030 FlashAmberWarningLamp 3040;
BA_ "SigType" SG_ 2566764030 FlashAmberWarningLamp 5;
BA_ "SPN" SG_ 2566764030 MalfunctionIndicatorLampStatus 1213;
BA_ "SigType" SG_ 2566764030 MalfunctionIndicatorLampStatus 5;
BA_ "SPN" SG_ 2566764030 RedStopLampState 623;
BA_ "SigType" SG_ 2566764030 RedStopLampState 4;
BA_ "SPN" SG_ 2566764030 AmberWarningLampStatus 624;
BA_ "SigType" SG_ 2566764030 AmberWarningLampStatus 5;
BA_ "SPN" SG_ 2566764030 ProtectLampStatus 987;
BA_ "SigType" SG_ 2566764030 ProtectLampStatus 5;
BA_ "SigType" SG_ 2566764030 DTC5 7;
BA_ "SigType" SG_ 2566764030 DTC4 7;
BA_ "SigType" SG_ 2566764030 DTC3 7;
BA_ "SigType" SG_ 2566764030 DTC2 7;
BA_ "SigType" SG_ 2566764030 DTC1 7;
BA_ "SPN" SG_ 2361655038 SPN1 3036;
BA_ "SPN" SG_ 2361655038 IndividualDTCClearControlByte 3034;
BA_ "SPN" SG_ 2361655038 CtrlByteIndicIndividualDTCClear 3035;
BA_ "SPN" SG_ 2361655038 FailureModeIdentifier1 3037;
BA_ "SPN" SG_ 2361523966 TimeSinceDTCsCleared 3296;
BA_ "SigType" SG_ 2361523966 TimeSinceDTCsCleared 1;
BA_ "SPN" SG_ 2361523966 MinutesAccumulatedMILActivated 3295;
BA_ "SigType" SG_ 2361523966 MinutesAccumulatedMILActivated 1;
BA_ "SPN" SG_ 2361523966 DistanceSinceDTCsCleared 3294;
BA_ "SigType" SG_ 2361523966 DistanceSinceDTCsCleared 1;
BA_ "SPN" SG_ 2361523966 DistanceWhileMILisActivated 3069;
BA_ "SigType" SG_ 2361523966 DistanceWhileMILisActivated 1;
BA_ "SPN" SG_ 2562916094 ApplSysMonitorDenominator 3068;
BA_ "SPN" SG_ 2562916094 ApplSysMonitorNumerator 3067;
BA_ "SPN" SG_ 2562916094 SPNofApplSysMonitor 3066;
BA_ "SPN" SG_ 2562916094 OBDMonitoringCondEncountered 3049;
BA_ "SPN" SG_ 2562916094 IgnitionCycleCounter 3048;
BA_ "SPN" SG_ 2566834945 MalfunctionIndicatorLampStatus 1213;
BA_ "SigType" SG_ 2566834945 MalfunctionIndicatorLampStatus 5;
BA_ "SPN" SG_ 2566834945 RedStopLampState 623;
BA_ "SigType" SG_ 2566834945 RedStopLampState 4;
BA_ "SPN" SG_ 2566834945 AmberWarningLampStatus 624;
BA_ "SigType" SG_ 2566834945 AmberWarningLampStatus 5;
BA_ "SPN" SG_ 2566834945 ProtectLampStatus 987;
BA_ "SigType" SG_ 2566834945 ProtectLampStatus 5;
BA_ "SPN" SG_ 2566834945 FlashRedStopLamp 3039;
BA_ "SigType" SG_ 2566834945 FlashRedStopLamp 5;
BA_ "SPN" SG_ 2566834945 FlashProtectLamp 3041;
BA_ "SigType" SG_ 2566834945 FlashProtectLamp 5;
BA_ "SPN" SG_ 2566834945 FlashMalfuncIndicatorLamp 3038;
BA_ "SigType" SG_ 2566834945 FlashMalfuncIndicatorLamp 5;
BA_ "SPN" SG_ 2566834945 FlashAmberWarningLamp 3040;
BA_ "SigType" SG_ 2566834945 FlashAmberWarningLamp 5;
BA_ "SigType" SG_ 2566834945 DTC5 7;
BA_ "SigType" SG_ 2566834945 DTC4 7;
BA_ "SigType" SG_ 2566834945 DTC3 7;
BA_ "SigType" SG_ 2566834945 DTC2 7;
BA_ "SigType" SG_ 2566834945 DTC1 7;
BA_ "SPN" SG_ 2564030206 CalibrationID1 1635;
BA_ "SigType" SG_ 2564030206 CalibrationID1 1;
BA_ "SPN" SG_ 2564030206 CalibrationVerificationNumber 1634;
BA_ "SPN" SG_ 2362900222 BootLoadData 1652;
BA_ "SPN" SG_ 2362965758 RawBinaryData 1651;
BA_ "SPN" SG_ 2362965758 NumberOfOccurance 1650;
BA_ "SPN" SG_ 2363031294 NumberAllowed 1649;
BA_ "SPN" SG_ 2363031294 Seed 1599;
BA_ "SPN" SG_ 2363031294 EDCP_Extension 1647;
BA_ "SPN" SG_ 2363031294 ErrorIndicator 1648;
BA_ "SPN" SG_ 2363031294 Status 1646;
BA_ "SPN" SG_ 2363096830 KeyOrUserLevel 1645;
BA_ "SPN" SG_ 2363096830 PointerExtension 1643;
BA_ "SPN" SG_ 2363096830 Pointer 1644;
BA_ "SPN" SG_ 2363096830 Command 1642;
BA_ "SPN" SG_ 2363096830 PointerType 1641;
BA_ "SPN" SG_ 2363096830 NumberRequested 1640;
BA_ "SPN" SG_ 2363490046 ProprietaryNetwork2 5588;
BA_ "SigType" SG_ 2363490046 ProprietaryNetwork2 5;
BA_ "SPN" SG_ 2363490046 ProprietaryNetwork1 625;
BA_ "SigType" SG_ 2363490046 ProprietaryNetwork1 5;
BA_ "SPN" SG_ 2363490046 J1939Network4 1668;
BA_ "SigType" SG_ 2363490046 J1939Network4 5;
BA_ "SPN" SG_ 2363490046 HoldSignal 1236;
BA_ "SPN" SG_ 2363490046 J1939Network3 1235;
BA_ "SigType" SG_ 2363490046 J1939Network3 5;
BA_ "SPN" SG_ 2363490046 J1939Network2 1231;
BA_ "SigType" SG_ 2363490046 J1939Network2 5;
BA_ "SPN" SG_ 2363490046 ISO9141 1232;
BA_ "SigType" SG_ 2363490046 ISO9141 5;
BA_ "SPN" SG_ 2363490046 SAE_J1850 1233;
BA_ "SigType" SG_ 2363490046 SAE_J1850 5;
BA_ "SPN" SG_ 2363490046 ManufacturerSpecificPort 1234;
BA_ "SigType" SG_ 2363490046 ManufacturerSpecificPort 5;
BA_ "SPN" SG_ 2363490046 CurrentDataLink 1230;
BA_ "SigType" SG_ 2363490046 CurrentDataLink 5;
BA_ "SPN" SG_ 2363490046 SAE_J1587 608;
BA_ "SigType" SG_ 2363490046 SAE_J1587 5;
BA_ "SPN" SG_ 2363490046 SAE_J1922 622;
BA_ "SigType" SG_ 2363490046 SAE_J1922 5;
BA_ "SPN" SG_ 2363490046 J1939Network1 639;
BA_ "SigType" SG_ 2363490046 J1939Network1 5;
BA_ "SPN" SG_ 2363490046 SuspendSignal 2618;
BA_ "SPN" SG_ 2363490046 SuspendDuration 2619;
BA_ "SigType" SG_ 2363490046 SuspendDuration 1;
BA_ "SPN" SG_ 2566837502 FlashRedStopLamp 3039;
BA_ "SigType" SG_ 2566837502 FlashRedStopLamp 5;
BA_ "SPN" SG_ 2566837502 FlashProtectLamp 3041;
BA_ "SigType" SG_ 2566837502 FlashProtectLamp 5;
BA_ "SPN" SG_ 2566837502 MalfunctionIndicatorLampStatus 1213;
BA_ "SigType" SG_ 2566837502 MalfunctionIndicatorLampStatus 5;
BA_ "SPN" SG_ 2566837502 RedStopLampState 623;
BA_ "SigType" SG_ 2566837502 RedStopLampState 4;
BA_ "SPN" SG_ 2566837502 AmberWarningLampStatus 624;
BA_ "SigType" SG_ 2566837502 AmberWarningLampStatus 5;
BA_ "SPN" SG_ 2566837502 ProtectLampStatus 987;
BA_ "SigType" SG_ 2566837502 ProtectLampStatus 5;
BA_ "SPN" SG_ 2566837502 FlashMalfuncIndicatorLamp 3038;
BA_ "SigType" SG_ 2566837502 FlashMalfuncIndicatorLamp 5;
BA_ "SPN" SG_ 2566837502 FlashAmberWarningLamp 3040;
BA_ "SigType" SG_ 2566837502 FlashAmberWarningLamp 5;
BA_ "SigType" SG_ 2566837502 DTC5 7;
BA_ "SigType" SG_ 2566837502 DTC4 7;
BA_ "SigType" SG_ 2566837502 DTC3 7;
BA_ "SigType" SG_ 2566837502 DTC2 7;
BA_ "SigType" SG_ 2566837502 DTC1 7;
BA_ "SPN" SG_ 2365510398 TestIdentifierSupported 1229;
BA_ "SigType" SG_ 2365510398 TestIdentifierSupported 1;
BA_ "SPN" SG_ 2566834942 FlashRedStopLamp 3039;
BA_ "SigType" SG_ 2566834942 FlashRedStopLamp 5;
BA_ "SPN" SG_ 2566834942 FlashProtectLamp 3041;
BA_ "SigType" SG_ 2566834942 FlashProtectLamp 5;
BA_ "SPN" SG_ 2566834942 FlashMalfuncIndicatorLamp 3038;
BA_ "SigType" SG_ 2566834942 FlashMalfuncIndicatorLamp 5;
BA_ "SPN" SG_ 2566834942 FlashAmberWarningLamp 3040;
BA_ "SigType" SG_ 2566834942 FlashAmberWarningLamp 5;
BA_ "SPN" SG_ 2566834942 MalfunctionIndicatorLampStatus 1213;
BA_ "SigType" SG_ 2566834942 MalfunctionIndicatorLampStatus 5;
BA_ "SPN" SG_ 2566834942 AmberWarningLampStatus 624;
BA_ "SigType" SG_ 2566834942 AmberWarningLampStatus 5;
BA_ "SPN" SG_ 2566834942 RedStopLampState 623;
BA_ "SigType" SG_ 2566834942 RedStopLampState 4;
BA_ "SPN" SG_ 2566834942 ProtectLampStatus 987;
BA_ "SigType" SG_ 2566834942 ProtectLampStatus 5;
BA_ "SigType" SG_ 2566834942 DTC5 7;
BA_ "SigType" SG_ 2566834942 DTC4 7;
BA_ "SigType" SG_ 2566834942 DTC3 7;
BA_ "SigType" SG_ 2566834942 DTC2 7;
BA_ "SigType" SG_ 2566834942 DTC1 7;
BA_ "SPN" SG_ 2365454334 UtlityOverallPowerFactorLagging 2522;
BA_ "SigType" SG_ 2365454334 UtlityOverallPowerFactorLagging 4;
BA_ "SPN" SG_ 2365454334 UtilityOverallPowerFactor 2498;
BA_ "SigType" SG_ 2365454334 UtilityOverallPowerFactor 1;
BA_ "SPN" SG_ 2365454334 UtilityTotalReactivePower 2490;
BA_ "SigType" SG_ 2365454334 UtilityTotalReactivePower 1;
BA_ "SPN" SG_ 2365454590 UtilityTotalApparentPower 2494;
BA_ "SigType" SG_ 2365454590 UtilityTotalApparentPower 1;
BA_ "SPN" SG_ 2365454590 UtilityTotalRealPower 2486;
BA_ "SigType" SG_ 2365454590 UtilityTotalRealPower 1;
BA_ "SPN" SG_ 2365451774 UtilityTotalKWHoursImport 2503;
BA_ "SigType" SG_ 2365451774 UtilityTotalKWHoursImport 1;
BA_ "SPN" SG_ 2365451774 UtilityTotalKWHoursExport 2502;
BA_ "SigType" SG_ 2365451774 UtilityTotalKWHoursExport 1;
BA_ "SPN" SG_ 2365452030 UtilityPhaseCPowerFactorLagging 2525;
BA_ "SigType" SG_ 2365452030 UtilityPhaseCPowerFactorLagging 4;
BA_ "SPN" SG_ 2365452030 UtilityPhaseCPowerFactor 2501;
BA_ "SigType" SG_ 2365452030 UtilityPhaseCPowerFactor 1;
BA_ "SPN" SG_ 2365452030 UtilityPhaseCReactivePower 2493;
BA_ "SigType" SG_ 2365452030 UtilityPhaseCReactivePower 1;
BA_ "SPN" SG_ 2365452286 UtilityPhaseCApparentPower 2497;
BA_ "SigType" SG_ 2365452286 UtilityPhaseCApparentPower 1;
BA_ "SPN" SG_ 2365452286 UtilityPhaseCRealPower 2489;
BA_ "SigType" SG_ 2365452286 UtilityPhaseCRealPower 1;
BA_ "SPN" SG_ 2365452542 UtilityPhaseCACRMSCurrent 2485;
BA_ "SigType" SG_ 2365452542 UtilityPhaseCACRMSCurrent 1;
BA_ "SPN" SG_ 2365452542 UtilityPhaseCACFrequency 2473;
BA_ "SigType" SG_ 2365452542 UtilityPhaseCACFrequency 1;
BA_ "SPN" SG_ 2365452542 UtltyPhsCLneNeutralACRMSVoltage 2481;
BA_ "SigType" SG_ 2365452542 UtltyPhsCLneNeutralACRMSVoltage 1;
BA_ "SPN" SG_ 2365452542 UtltyPhseCALineLineACRMSVoltage 2477;
BA_ "SigType" SG_ 2365452542 UtltyPhseCALineLineACRMSVoltage 1;
BA_ "SPN" SG_ 2365452798 UtilityPhaseBPowerFactorLagging 2524;
BA_ "SigType" SG_ 2365452798 UtilityPhaseBPowerFactorLagging 4;
BA_ "SPN" SG_ 2365452798 UtilityPhaseBPowerFactor 2500;
BA_ "SigType" SG_ 2365452798 UtilityPhaseBPowerFactor 1;
BA_ "SPN" SG_ 2365452798 UtilityPhaseBReactivePower 2492;
BA_ "SigType" SG_ 2365452798 UtilityPhaseBReactivePower 1;
BA_ "SPN" SG_ 2365453054 UtilityPhaseBApparentPower 2496;
BA_ "SigType" SG_ 2365453054 UtilityPhaseBApparentPower 1;
BA_ "SPN" SG_ 2365453054 UtilityPhaseBRealPower 2488;
BA_ "SigType" SG_ 2365453054 UtilityPhaseBRealPower 1;
BA_ "SPN" SG_ 2365453310 UtilityPhaseBACRMSCurrent 2484;
BA_ "SigType" SG_ 2365453310 UtilityPhaseBACRMSCurrent 1;
BA_ "SPN" SG_ 2365453310 UtilityPhaseBACFrequency 2472;
BA_ "SigType" SG_ 2365453310 UtilityPhaseBACFrequency 1;
BA_ "SPN" SG_ 2365453310 UtltyPhsBLneNeutralACRMSVoltage 2480;
BA_ "SigType" SG_ 2365453310 UtltyPhsBLneNeutralACRMSVoltage 1;
BA_ "SPN" SG_ 2365453310 UtltyPhseBCLineLineACRMSVoltage 2476;
BA_ "SigType" SG_ 2365453310 UtltyPhseBCLineLineACRMSVoltage 1;
BA_ "SPN" SG_ 2365453566 UtilityPhaseAPowerFactorLagging 2523;
BA_ "SigType" SG_ 2365453566 UtilityPhaseAPowerFactorLagging 4;
BA_ "SPN" SG_ 2365453566 UtilityPhaseAPowerFactor 2499;
BA_ "SigType" SG_ 2365453566 UtilityPhaseAPowerFactor 1;
BA_ "SPN" SG_ 2365453566 UtilityPhaseAReactivePower 2491;
BA_ "SigType" SG_ 2365453566 UtilityPhaseAReactivePower 1;
BA_ "SPN" SG_ 2365453822 UtilityPhaseAApparentPower 2495;
BA_ "SigType" SG_ 2365453822 UtilityPhaseAApparentPower 1;
BA_ "SPN" SG_ 2365453822 UtilityPhaseARealPower 2487;
BA_ "SigType" SG_ 2365453822 UtilityPhaseARealPower 1;
BA_ "SPN" SG_ 2365454078 UtilityPhaseAACRMSCurrent 2483;
BA_ "SigType" SG_ 2365454078 UtilityPhaseAACRMSCurrent 1;
BA_ "SPN" SG_ 2365454078 UtilityPhaseAACFrequency 2471;
BA_ "SigType" SG_ 2365454078 UtilityPhaseAACFrequency 1;
BA_ "SPN" SG_ 2365454078 UtltyPhsALneNeutralACRMSVoltage 2479;
BA_ "SigType" SG_ 2365454078 UtltyPhsALneNeutralACRMSVoltage 1;
BA_ "SPN" SG_ 2365454078 UtltyPhseABLineLineACRMSVoltage 2475;
BA_ "SigType" SG_ 2365454078 UtltyPhseABLineLineACRMSVoltage 1;
BA_ "SPN" SG_ 2365454846 UtilityAverageACRMSCurrent 2482;
BA_ "SigType" SG_ 2365454846 UtilityAverageACRMSCurrent 1;
BA_ "SPN" SG_ 2365454846 UtilityAverageACFrequency 2470;
BA_ "SigType" SG_ 2365454846 UtilityAverageACFrequency 1;
BA_ "SPN" SG_ 2365454846 UtltyAvrgLneNeutralACRMSVoltage 2478;
BA_ "SigType" SG_ 2365454846 UtltyAvrgLneNeutralACRMSVoltage 1;
BA_ "SPN" SG_ 2365454846 UtltyAvrageLineLineACRMSVoltage 2474;
BA_ "SigType" SG_ 2365454846 UtltyAvrageLineLineACRMSVoltage 1;
BA_ "SPN" SG_ 2365457662 GnrtorOverallPowerFactorLagging 2518;
BA_ "SigType" SG_ 2365457662 GnrtorOverallPowerFactorLagging 4;
BA_ "SPN" SG_ 2365457662 GeneratorOverallPowerFactor 2464;
BA_ "SigType" SG_ 2365457662 GeneratorOverallPowerFactor 1;
BA_ "SPN" SG_ 2365457662 GeneratorTotalReactivePower 2456;
BA_ "SigType" SG_ 2365457662 GeneratorTotalReactivePower 1;
BA_ "SPN" SG_ 2365457918 GeneratorTotalApparentPower 2460;
BA_ "SigType" SG_ 2365457918 GeneratorTotalApparentPower 1;
BA_ "SPN" SG_ 2365457918 GeneratorTotalRealPower 2452;
BA_ "SigType" SG_ 2365457918 GeneratorTotalRealPower 1;
BA_ "SPN" SG_ 2365455102 GeneratorTotalKWHoursImport 2469;
BA_ "SigType" SG_ 2365455102 GeneratorTotalKWHoursImport 1;
BA_ "SPN" SG_ 2365455102 GeneratorTotalKWHoursExport 2468;
BA_ "SigType" SG_ 2365455102 GeneratorTotalKWHoursExport 1;
BA_ "SPN" SG_ 2365455358 GnratorPhaseCPowerFactorLagging 2521;
BA_ "SigType" SG_ 2365455358 GnratorPhaseCPowerFactorLagging 4;
BA_ "SPN" SG_ 2365455358 GeneratorPhaseCPowerFactor 2467;
BA_ "SigType" SG_ 2365455358 GeneratorPhaseCPowerFactor 1;
BA_ "SPN" SG_ 2365455358 GeneratorPhaseCReactivePower 2459;
BA_ "SigType" SG_ 2365455358 GeneratorPhaseCReactivePower 1;
BA_ "SPN" SG_ 2365455614 GeneratorPhaseCApparentPower 2463;
BA_ "SigType" SG_ 2365455614 GeneratorPhaseCApparentPower 1;
BA_ "SPN" SG_ 2365455614 GeneratorPhaseCRealPower 2455;
BA_ "SigType" SG_ 2365455614 GeneratorPhaseCRealPower 1;
BA_ "SPN" SG_ 2365455870 GeneratorPhaseCACRMSCurrent 2451;
BA_ "SigType" SG_ 2365455870 GeneratorPhaseCACRMSCurrent 1;
BA_ "SPN" SG_ 2365455870 GeneratorPhaseCACFrequency 2439;
BA_ "SigType" SG_ 2365455870 GeneratorPhaseCACFrequency 1;
BA_ "SPN" SG_ 2365455870 GnrtrPhsCLneNeutralACRMSVoltage 2447;
BA_ "SigType" SG_ 2365455870 GnrtrPhsCLneNeutralACRMSVoltage 1;
BA_ "SPN" SG_ 2365455870 GnrtrPhseCALineLineACRMSVoltage 2443;
BA_ "SigType" SG_ 2365455870 GnrtrPhseCALineLineACRMSVoltage 1;
BA_ "SPN" SG_ 2365456126 GnratorPhaseBPowerFactorLagging 2520;
BA_ "SigType" SG_ 2365456126 GnratorPhaseBPowerFactorLagging 4;
BA_ "SPN" SG_ 2365456126 GeneratorPhaseBPowerFactor 2466;
BA_ "SigType" SG_ 2365456126 GeneratorPhaseBPowerFactor 1;
BA_ "SPN" SG_ 2365456126 GeneratorPhaseBReactivePower 2458;
BA_ "SigType" SG_ 2365456126 GeneratorPhaseBReactivePower 1;
BA_ "SPN" SG_ 2365456382 GeneratorPhaseBApparentPower 2462;
BA_ "SigType" SG_ 2365456382 GeneratorPhaseBApparentPower 1;
BA_ "SPN" SG_ 2365456382 GeneratorPhaseBRealPower 2454;
BA_ "SigType" SG_ 2365456382 GeneratorPhaseBRealPower 1;
BA_ "SPN" SG_ 2365456638 GeneratorPhaseBACRMSCurrent 2450;
BA_ "SigType" SG_ 2365456638 GeneratorPhaseBACRMSCurrent 1;
BA_ "SPN" SG_ 2365456638 GeneratorPhaseBACFrequency 2438;
BA_ "SigType" SG_ 2365456638 GeneratorPhaseBACFrequency 1;
BA_ "SPN" SG_ 2365456638 GnrtrPhsBLneNeutralACRMSVoltage 2446;
BA_ "SigType" SG_ 2365456638 GnrtrPhsBLneNeutralACRMSVoltage 1;
BA_ "SPN" SG_ 2365456638 GnrtrPhseBCLineLineACRMSVoltage 2442;
BA_ "SigType" SG_ 2365456638 GnrtrPhseBCLineLineACRMSVoltage 1;
BA_ "SPN" SG_ 2365456894 GnratorPhaseAPowerFactorLagging 2519;
BA_ "SigType" SG_ 2365456894 GnratorPhaseAPowerFactorLagging 4;
BA_ "SPN" SG_ 2365456894 GeneratorPhaseAPowerFactor 2465;
BA_ "SigType" SG_ 2365456894 GeneratorPhaseAPowerFactor 1;
BA_ "SPN" SG_ 2365456894 GeneratorPhaseAReactivePower 2457;
BA_ "SigType" SG_ 2365456894 GeneratorPhaseAReactivePower 1;
BA_ "SPN" SG_ 2365457150 GeneratorPhaseAApparentPower 2461;
BA_ "SigType" SG_ 2365457150 GeneratorPhaseAApparentPower 1;
BA_ "SPN" SG_ 2365457150 GeneratorPhaseARealPower 2453;
BA_ "SigType" SG_ 2365457150 GeneratorPhaseARealPower 1;
BA_ "SPN" SG_ 2365457406 GeneratorPhaseAACRMSCurrent 2449;
BA_ "SigType" SG_ 2365457406 GeneratorPhaseAACRMSCurrent 1;
BA_ "SPN" SG_ 2365457406 GeneratorPhaseAACFrequency 2437;
BA_ "SigType" SG_ 2365457406 GeneratorPhaseAACFrequency 1;
BA_ "SPN" SG_ 2365457406 GnrtrPhsALneNeutralACRMSVoltage 2445;
BA_ "SigType" SG_ 2365457406 GnrtrPhsALneNeutralACRMSVoltage 1;
BA_ "SPN" SG_ 2365457406 GnrtrPhseABLineLineACRMSVoltage 2441;
BA_ "SigType" SG_ 2365457406 GnrtrPhseABLineLineACRMSVoltage 1;
BA_ "SPN" SG_ 2365458174 GeneratorAverageACRMSCurrent 2448;
BA_ "SigType" SG_ 2365458174 GeneratorAverageACRMSCurrent 1;
BA_ "SPN" SG_ 2365458174 GeneratorAverageACFrequency 2436;
BA_ "SigType" SG_ 2365458174 GeneratorAverageACFrequency 1;
BA_ "SPN" SG_ 2365458174 GnrtrAvrgLneNeutralACRMSVoltage 2444;
BA_ "SigType" SG_ 2365458174 GnrtrAvrgLneNeutralACRMSVoltage 1;
BA_ "SPN" SG_ 2365458174 GnrtrAvrageLineLineACRMSVoltage 2440;
BA_ "SigType" SG_ 2365458174 GnrtrAvrageLineLineACRMSVoltage 1;
BA_ "SPN" SG_ 2365450238 Bus1_UtilityACPhaseDifference 2517;
BA_ "SigType" SG_ 2365450238 Bus1_UtilityACPhaseDifference 1;
BA_ "SPN" SG_ 2365450238 Bus1_UtilityInSync 2534;
BA_ "SigType" SG_ 2365450238 Bus1_UtilityInSync 4;
BA_ "SPN" SG_ 2365450238 Bus1_UtilityVoltageMatch 2532;
BA_ "SigType" SG_ 2365450238 Bus1_UtilityVoltageMatch 4;
BA_ "SPN" SG_ 2365450238 Bus1_UtilityFrequencyMatch 2533;
BA_ "SigType" SG_ 2365450238 Bus1_UtilityFrequencyMatch 4;
BA_ "SPN" SG_ 2365450238 Bus1_UtilityPhaseMatch 2531;
BA_ "SigType" SG_ 2365450238 Bus1_UtilityPhaseMatch 4;
BA_ "SPN" SG_ 2365450238 Bus1_UtilityDeadBus 2535;
BA_ "SigType" SG_ 2365450238 Bus1_UtilityDeadBus 4;
BA_ "SPN" SG_ 2365450750 Bus1PhaseCACFrequency 2507;
BA_ "SigType" SG_ 2365450750 Bus1PhaseCACFrequency 1;
BA_ "SPN" SG_ 2365450750 Bs1PhseCLineNeutralACRMSVoltage 2515;
BA_ "SigType" SG_ 2365450750 Bs1PhseCLineNeutralACRMSVoltage 1;
BA_ "SPN" SG_ 2365450750 Bus1PhaseCALineLineACRMSVoltage 2511;
BA_ "SigType" SG_ 2365450750 Bus1PhaseCALineLineACRMSVoltage 1;
BA_ "SPN" SG_ 2365451006 Bus1PhaseBACFrequency 2506;
BA_ "SigType" SG_ 2365451006 Bus1PhaseBACFrequency 1;
BA_ "SPN" SG_ 2365451006 Bs1PhseBLineNeutralACRMSVoltage 2514;
BA_ "SigType" SG_ 2365451006 Bs1PhseBLineNeutralACRMSVoltage 1;
BA_ "SPN" SG_ 2365451006 Bus1PhaseBCLineLineACRMSVoltage 2510;
BA_ "SigType" SG_ 2365451006 Bus1PhaseBCLineLineACRMSVoltage 1;
BA_ "SPN" SG_ 2365451262 Bus1PhaseAACFrequency 2505;
BA_ "SigType" SG_ 2365451262 Bus1PhaseAACFrequency 1;
BA_ "SPN" SG_ 2365451262 Bs1PhseALineNeutralACRMSVoltage 2513;
BA_ "SigType" SG_ 2365451262 Bs1PhseALineNeutralACRMSVoltage 1;
BA_ "SPN" SG_ 2365451262 Bus1PhaseABLineLineACRMSVoltage 2509;
BA_ "SigType" SG_ 2365451262 Bus1PhaseABLineLineACRMSVoltage 1;
BA_ "SPN" SG_ 2365450494 Bus1_GeneratorACPhaseDifference 2516;
BA_ "SigType" SG_ 2365450494 Bus1_GeneratorACPhaseDifference 1;
BA_ "SPN" SG_ 2365450494 Bus1_GeneratorInSync 2529;
BA_ "SigType" SG_ 2365450494 Bus1_GeneratorInSync 4;
BA_ "SPN" SG_ 2365450494 Bus1_GeneratorVoltageMatch 2527;
BA_ "SigType" SG_ 2365450494 Bus1_GeneratorVoltageMatch 4;
BA_ "SPN" SG_ 2365450494 Bus1_GeneratorFrequencyMatch 2528;
BA_ "SigType" SG_ 2365450494 Bus1_GeneratorFrequencyMatch 4;
BA_ "SPN" SG_ 2365450494 Bus1_GeneratorPhaseMatch 2526;
BA_ "SigType" SG_ 2365450494 Bus1_GeneratorPhaseMatch 4;
BA_ "SPN" SG_ 2365450494 Bus1_GeneratorDeadBus 2530;
BA_ "SigType" SG_ 2365450494 Bus1_GeneratorDeadBus 4;
BA_ "SPN" SG_ 2365451518 Bus1AverageACFrequency 2504;
BA_ "SigType" SG_ 2365451518 Bus1AverageACFrequency 1;
BA_ "SPN" SG_ 2365451518 Bs1AvrgeLineNeutralACRMSVoltage 2512;
BA_ "SigType" SG_ 2365451518 Bs1AvrgeLineNeutralACRMSVoltage 1;
BA_ "SPN" SG_ 2365451518 Bus1AverageLineLineACRMSVoltage 2508;
BA_ "SigType" SG_ 2365451518 Bus1AverageLineLineACRMSVoltage 1;
BA_ "SigType" SG_ 2365459966 NumberOfMembers 3;
BA_ "SPN" SG_ 2566838526 AddressAssignment 2847;
BA_ "SPN" SG_ 2566838526 ArbitraryAddressCapable 2844;
BA_ "SPN" SG_ 2566838526 IndustryGroup 2846;
BA_ "SPN" SG_ 2566838526 VehicleSystemInstance 2843;
BA_ "SPN" SG_ 2566838526 Function 2841;
BA_ "SPN" SG_ 2566838526 FunctionInstance 2839;
BA_ "SPN" SG_ 2566838526 ECUInstance 2840;
BA_ "SPN" SG_ 2566838526 ManufacturerCode 2838;
BA_ "SigType" SG_ 2566838526 ManufacturerCode 1;
BA_ "SPN" SG_ 2566838526 IdentityNumber 2837;
BA_ "SPN" SG_ 2364473086 ArbitraryAddressCapable 2844;
BA_ "SPN" SG_ 2364473086 IndustryGroup 2846;
BA_ "SPN" SG_ 2364473086 VehicleSystemInstance 2843;
BA_ "SPN" SG_ 2364473086 Function 2841;
BA_ "SPN" SG_ 2364473086 FunctionInstance 2839;
BA_ "SPN" SG_ 2364473086 ECUInstance 2840;
BA_ "SPN" SG_ 2364473086 ManufacturerCode 2838;
BA_ "SigType" SG_ 2364473086 ManufacturerCode 1;
BA_ "SPN" SG_ 2364473086 IdentityNumber 2837;
BA_ "SPN" SG_ 2362113790 ShrtNameOfActualReportingDevice 2554;
BA_ "SigType" SG_ 2362113790 ShrtNameOfActualReportingDevice 4;
BA_ "SPN" SG_ 2362113790 LengthOfDataForTheReportedPGN 2553;
BA_ "SigType" SG_ 2362113790 LengthOfDataForTheReportedPGN 1;
BA_ "SPN" SG_ 2362113790 PGNofRequstedInformation 2552;
BA_ "SigType" SG_ 2362113790 PGNofRequstedInformation 6;
BA_ "SPN" SG_ 2364276478 SequenceNumber 2572;
BA_ "SPN" SG_ 2364342014 TotalNumberOfPacketsEoMA 2565;
BA_ "SPN" SG_ 2364342014 TotalMessageSizeEoMA 2564;
BA_ "SigType" SG_ 2364342014 TotalMessageSizeEoMA 1;
BA_ "SPN" SG_ 2364342014 TotalMessageSizeBAM 2567;
BA_ "SigType" SG_ 2364342014 TotalMessageSizeBAM 1;
BA_ "SPN" SG_ 2364342014 TotalNumberOfPacketsBAM 2568;
BA_ "SPN" SG_ 2364342014 ConnectionAbortReason 2570;
BA_ "SPN" SG_ 2364342014 NextPacketNumberToBeSent 2562;
BA_ "SPN" SG_ 2364342014 NumberOfPacketsThatCanBeSent 2561;
BA_ "SPN" SG_ 2364342014 PGNumber 2560;
BA_ "SigType" SG_ 2364342014 PGNumber 6;
BA_ "SPN" SG_ 2364342014 MaximumNumberOfPackets 2559;
BA_ "SPN" SG_ 2364342014 TotalNumberOfPackets 2558;
BA_ "SPN" SG_ 2364342014 TotalMessageSize 2557;
BA_ "SigType" SG_ 2364342014 TotalMessageSize 1;
BA_ "SPN" SG_ 2364342014 ControlByte 2556;
BA_ "SPN" SG_ 2362048254 ParameterGroupNumber 2574;
BA_ "SigType" SG_ 2362048254 ParameterGroupNumber 6;
BA_ "SPN" SG_ 2362048254 UseTransferMode 2575;
BA_ "SigType" SG_ 2362048254 UseTransferMode 4;
BA_ "SPN" SG_ 2364210942 ParameterGroupNumber 2540;
BA_ "SigType" SG_ 2364210942 ParameterGroupNumber 6;
BA_ "SPN" SG_ 2499635966 AdditionalAxleGroupLocation 5935;
BA_ "SPN" SG_ 2499635966 AxleGroupWeight 409;
BA_ "SigType" SG_ 2499635966 AxleGroupWeight 1;
BA_ "SPN" SG_ 2499635966 AxleGroupLocation 4073;
BA_ "SPN" SG_ 2633853438 AdditionalAxleGroupLocation 5936;
BA_ "SPN" SG_ 2633853438 AxleGroupFullWeightCalib 407;
BA_ "SigType" SG_ 2633853438 AxleGroupFullWeightCalib 1;
BA_ "SPN" SG_ 2633853438 AxleGroupEmptyWeightCalib 408;
BA_ "SigType" SG_ 2633853438 AxleGroupEmptyWeightCalib 1;
BA_ "SPN" SG_ 2633853438 AxleGroupLocation 4074;
BA_ "SPN" SG_ 2432520702 DsrdAftrclrClntThermostatOpening 4200;
BA_ "SigType" SG_ 2432520702 DsrdAftrclrClntThermostatOpening 1;
BA_ "SPN" SG_ 2432520702 DsrdAftercoolerCoolantIntakeTemp 4199;
BA_ "SigType" SG_ 2432520702 DsrdAftercoolerCoolantIntakeTemp 1;
BA_ "SPN" SG_ 2432520702 AftercoolerCoolantThermostatMode 4198;
BA_ "SigType" SG_ 2432520702 AftercoolerCoolantThermostatMode 5;
BA_ "SPN" SG_ 2566745086 RarDriveAxleGroupWeightAvailable 5934;
BA_ "SigType" SG_ 2566745086 RarDriveAxleGroupWeightAvailable 5;
BA_ "SPN" SG_ 2566745086 RarSteerAxleGroupWeightAvailable 5933;
BA_ "SigType" SG_ 2566745086 RarSteerAxleGroupWeightAvailable 5;
BA_ "SPN" SG_ 2566745086 AddtnlTrlrAxlGrupWeightAvailable 4072;
BA_ "SigType" SG_ 2566745086 AddtnlTrlrAxlGrupWeightAvailable 5;
BA_ "SPN" SG_ 2566745086 TrailerHAxleGroupWeightAvailable 4071;
BA_ "SigType" SG_ 2566745086 TrailerHAxleGroupWeightAvailable 5;
BA_ "SPN" SG_ 2566745086 TrailerGAxleGroupWeightAvailable 4070;
BA_ "SigType" SG_ 2566745086 TrailerGAxleGroupWeightAvailable 5;
BA_ "SPN" SG_ 2566745086 TrailerFAxleGroupWeightAvailable 4069;
BA_ "SigType" SG_ 2566745086 TrailerFAxleGroupWeightAvailable 5;
BA_ "SPN" SG_ 2566745086 TrailerEAxleGroupWeightAvailable 4068;
BA_ "SigType" SG_ 2566745086 TrailerEAxleGroupWeightAvailable 5;
BA_ "SPN" SG_ 2566745086 TrailerDAxleGroupWeightAvailable 4067;
BA_ "SigType" SG_ 2566745086 TrailerDAxleGroupWeightAvailable 5;
BA_ "SPN" SG_ 2566745086 TrailerCAxleGroupWeightAvailable 4066;
BA_ "SigType" SG_ 2566745086 TrailerCAxleGroupWeightAvailable 5;
BA_ "SPN" SG_ 2566745086 TrailerBAxleGroupWeightAvailable 4065;
BA_ "SigType" SG_ 2566745086 TrailerBAxleGroupWeightAvailable 5;
BA_ "SPN" SG_ 2566745086 TrailerAAxleGroupWeightAvailable 4064;
BA_ "SigType" SG_ 2566745086 TrailerAAxleGroupWeightAvailable 5;
BA_ "SPN" SG_ 2566745086 AddtnlTrctrAxlGrpWeightAvailable 4063;
BA_ "SigType" SG_ 2566745086 AddtnlTrctrAxlGrpWeightAvailable 5;
BA_ "SPN" SG_ 2566745086 TagAxleGroupWeightAvailable 4062;
BA_ "SigType" SG_ 2566745086 TagAxleGroupWeightAvailable 5;
BA_ "SPN" SG_ 2566745086 DriveAxleGroupWeightAvailable 4061;
BA_ "SigType" SG_ 2566745086 DriveAxleGroupWeightAvailable 5;
BA_ "SPN" SG_ 2566745086 LiftAxleGroupWeightAvailable 4060;
BA_ "SigType" SG_ 2566745086 LiftAxleGroupWeightAvailable 5;
BA_ "SPN" SG_ 2566745086 SteerAxleGroupWeightAvailable 4059;
BA_ "SigType" SG_ 2566745086 SteerAxleGroupWeightAvailable 5;
BA_ "SPN" SG_ 2566739198 FlashRedStopLamp 3039;
BA_ "SigType" SG_ 2566739198 FlashRedStopLamp 5;
BA_ "SPN" SG_ 2566739198 FlashProtectLamp 3041;
BA_ "SigType" SG_ 2566739198 FlashProtectLamp 5;
BA_ "SPN" SG_ 2566739198 FlashMalfuncIndicatorLamp 3038;
BA_ "SigType" SG_ 2566739198 FlashMalfuncIndicatorLamp 5;
BA_ "SPN" SG_ 2566739198 FlashAmberWarningLamp 3040;
BA_ "SigType" SG_ 2566739198 FlashAmberWarningLamp 5;
BA_ "SPN" SG_ 2566739198 MalfunctionIndicatorLampStatus 1213;
BA_ "SigType" SG_ 2566739198 MalfunctionIndicatorLampStatus 5;
BA_ "SPN" SG_ 2566739198 AmberWarningLampStatus 624;
BA_ "SigType" SG_ 2566739198 AmberWarningLampStatus 5;
BA_ "SPN" SG_ 2566739198 RedStopLampState 623;
BA_ "SigType" SG_ 2566739198 RedStopLampState 4;
BA_ "SPN" SG_ 2566739198 ProtectLampStatus 987;
BA_ "SigType" SG_ 2566739198 ProtectLampStatus 5;
BA_ "SigType" SG_ 2566739198 DTC5 7;
BA_ "SigType" SG_ 2566739198 DTC4 7;
BA_ "SigType" SG_ 2566739198 DTC3 7;
BA_ "SigType" SG_ 2566739198 DTC2 7;
BA_ "SigType" SG_ 2566739198 DTC1 7;
BA_ "SPN" SG_ 2566739454 FlashRedStopLamp 3039;
BA_ "SigType" SG_ 2566739454 FlashRedStopLamp 5;
BA_ "SPN" SG_ 2566739454 FlashProtectLamp 3041;
BA_ "SigType" SG_ 2566739454 FlashProtectLamp 5;
BA_ "SPN" SG_ 2566739454 FlashMalfuncIndicatorLamp 3038;
BA_ "SigType" SG_ 2566739454 FlashMalfuncIndicatorLamp 5;
BA_ "SPN" SG_ 2566739454 FlashAmberWarningLamp 3040;
BA_ "SigType" SG_ 2566739454 FlashAmberWarningLamp 5;
BA_ "SPN" SG_ 2566739454 MalfunctionIndicatorLampStatus 1213;
BA_ "SigType" SG_ 2566739454 MalfunctionIndicatorLampStatus 5;
BA_ "SPN" SG_ 2566739454 AmberWarningLampStatus 624;
BA_ "SigType" SG_ 2566739454 AmberWarningLampStatus 5;
BA_ "SPN" SG_ 2566739454 RedStopLampState 623;
BA_ "SigType" SG_ 2566739454 RedStopLampState 4;
BA_ "SPN" SG_ 2566739454 ProtectLampStatus 987;
BA_ "SigType" SG_ 2566739454 ProtectLampStatus 5;
BA_ "SigType" SG_ 2566739454 DTC5 7;
BA_ "SigType" SG_ 2566739454 DTC4 7;
BA_ "SigType" SG_ 2566739454 DTC3 7;
BA_ "SigType" SG_ 2566739454 DTC2 7;
BA_ "SigType" SG_ 2566739454 DTC1 7;
BA_ "SPN" SG_ 2566739710 FlashRedStopLamp 3039;
BA_ "SigType" SG_ 2566739710 FlashRedStopLamp 5;
BA_ "SPN" SG_ 2566739710 FlashProtectLamp 3041;
BA_ "SigType" SG_ 2566739710 FlashProtectLamp 5;
BA_ "SPN" SG_ 2566739710 FlashMalfuncIndicatorLamp 3038;
BA_ "SigType" SG_ 2566739710 FlashMalfuncIndicatorLamp 5;
BA_ "SPN" SG_ 2566739710 FlashAmberWarningLamp 3040;
BA_ "SigType" SG_ 2566739710 FlashAmberWarningLamp 5;
BA_ "SPN" SG_ 2566739710 MalfunctionIndicatorLampStatus 1213;
BA_ "SigType" SG_ 2566739710 MalfunctionIndicatorLampStatus 5;
BA_ "SPN" SG_ 2566739710 AmberWarningLampStatus 624;
BA_ "SigType" SG_ 2566739710 AmberWarningLampStatus 5;
BA_ "SPN" SG_ 2566739710 RedStopLampState 623;
BA_ "SigType" SG_ 2566739710 RedStopLampState 4;
BA_ "SPN" SG_ 2566739710 ProtectLampStatus 987;
BA_ "SigType" SG_ 2566739710 ProtectLampStatus 5;
BA_ "SigType" SG_ 2566739710 DTC5 7;
BA_ "SigType" SG_ 2566739710 DTC4 7;
BA_ "SigType" SG_ 2566739710 DTC3 7;
BA_ "SigType" SG_ 2566739710 DTC2 7;
BA_ "SigType" SG_ 2566739710 DTC1 7;
BA_ "SPN" SG_ 2566739966 FlashRedStopLamp 3039;
BA_ "SigType" SG_ 2566739966 FlashRedStopLamp 5;
BA_ "SPN" SG_ 2566739966 FlashProtectLamp 3041;
BA_ "SigType" SG_ 2566739966 FlashProtectLamp 5;
BA_ "SPN" SG_ 2566739966 FlashMalfuncIndicatorLamp 3038;
BA_ "SigType" SG_ 2566739966 FlashMalfuncIndicatorLamp 5;
BA_ "SPN" SG_ 2566739966 FlashAmberWarningLamp 3040;
BA_ "SigType" SG_ 2566739966 FlashAmberWarningLamp 5;
BA_ "SPN" SG_ 2566739966 MalfunctionIndicatorLampStatus 1213;
BA_ "SigType" SG_ 2566739966 MalfunctionIndicatorLampStatus 5;
BA_ "SPN" SG_ 2566739966 AmberWarningLampStatus 624;
BA_ "SigType" SG_ 2566739966 AmberWarningLampStatus 5;
BA_ "SPN" SG_ 2566739966 RedStopLampState 623;
BA_ "SigType" SG_ 2566739966 RedStopLampState 4;
BA_ "SPN" SG_ 2566739966 ProtectLampStatus 987;
BA_ "SigType" SG_ 2566739966 ProtectLampStatus 5;
BA_ "SigType" SG_ 2566739966 DTC5 7;
BA_ "SigType" SG_ 2566739966 DTC4 7;
BA_ "SigType" SG_ 2566739966 DTC3 7;
BA_ "SigType" SG_ 2566739966 DTC2 7;
BA_ "SigType" SG_ 2566739966 DTC1 7;
BA_ "SPN" SG_ 2566740222 FlashRedStopLamp 3039;
BA_ "SigType" SG_ 2566740222 FlashRedStopLamp 5;
BA_ "SPN" SG_ 2566740222 FlashProtectLamp 3041;
BA_ "SigType" SG_ 2566740222 FlashProtectLamp 5;
BA_ "SPN" SG_ 2566740222 FlashMalfuncIndicatorLamp 3038;
BA_ "SigType" SG_ 2566740222 FlashMalfuncIndicatorLamp 5;
BA_ "SPN" SG_ 2566740222 FlashAmberWarningLamp 3040;
BA_ "SigType" SG_ 2566740222 FlashAmberWarningLamp 5;
BA_ "SPN" SG_ 2566740222 MalfunctionIndicatorLampStatus 1213;
BA_ "SigType" SG_ 2566740222 MalfunctionIndicatorLampStatus 5;
BA_ "SPN" SG_ 2566740222 AmberWarningLampStatus 624;
BA_ "SigType" SG_ 2566740222 AmberWarningLampStatus 5;
BA_ "SPN" SG_ 2566740222 RedStopLampState 623;
BA_ "SigType" SG_ 2566740222 RedStopLampState 4;
BA_ "SPN" SG_ 2566740222 ProtectLampStatus 987;
BA_ "SigType" SG_ 2566740222 ProtectLampStatus 5;
BA_ "SigType" SG_ 2566740222 DTC5 7;
BA_ "SigType" SG_ 2566740222 DTC4 7;
BA_ "SigType" SG_ 2566740222 DTC3 7;
BA_ "SigType" SG_ 2566740222 DTC2 7;
BA_ "SigType" SG_ 2566740222 DTC1 7;
BA_ "SPN" SG_ 2566740478 FlashRedStopLamp 3039;
BA_ "SigType" SG_ 2566740478 FlashRedStopLamp 5;
BA_ "SPN" SG_ 2566740478 FlashProtectLamp 3041;
BA_ "SigType" SG_ 2566740478 FlashProtectLamp 5;
BA_ "SPN" SG_ 2566740478 FlashMalfuncIndicatorLamp 3038;
BA_ "SigType" SG_ 2566740478 FlashMalfuncIndicatorLamp 5;
BA_ "SPN" SG_ 2566740478 FlashAmberWarningLamp 3040;
BA_ "SigType" SG_ 2566740478 FlashAmberWarningLamp 5;
BA_ "SPN" SG_ 2566740478 MalfunctionIndicatorLampStatus 1213;
BA_ "SigType" SG_ 2566740478 MalfunctionIndicatorLampStatus 5;
BA_ "SPN" SG_ 2566740478 AmberWarningLampStatus 624;
BA_ "SigType" SG_ 2566740478 AmberWarningLampStatus 5;
BA_ "SPN" SG_ 2566740478 RedStopLampState 623;
BA_ "SigType" SG_ 2566740478 RedStopLampState 4;
BA_ "SPN" SG_ 2566740478 ProtectLampStatus 987;
BA_ "SigType" SG_ 2566740478 ProtectLampStatus 5;
BA_ "SigType" SG_ 2566740478 DTC5 7;
BA_ "SigType" SG_ 2566740478 DTC4 7;
BA_ "SigType" SG_ 2566740478 DTC3 7;
BA_ "SigType" SG_ 2566740478 DTC2 7;
BA_ "SigType" SG_ 2566740478 DTC1 7;
BA_ "SPN" SG_ 2566740734 FlashRedStopLamp 3039;
BA_ "SigType" SG_ 2566740734 FlashRedStopLamp 5;
BA_ "SPN" SG_ 2566740734 FlashProtectLamp 3041;
BA_ "SigType" SG_ 2566740734 FlashProtectLamp 5;
BA_ "SPN" SG_ 2566740734 FlashMalfuncIndicatorLamp 3038;
BA_ "SigType" SG_ 2566740734 FlashMalfuncIndicatorLamp 5;
BA_ "SPN" SG_ 2566740734 FlashAmberWarningLamp 3040;
BA_ "SigType" SG_ 2566740734 FlashAmberWarningLamp 5;
BA_ "SPN" SG_ 2566740734 MalfunctionIndicatorLampStatus 1213;
BA_ "SigType" SG_ 2566740734 MalfunctionIndicatorLampStatus 5;
BA_ "SPN" SG_ 2566740734 AmberWarningLampStatus 624;
BA_ "SigType" SG_ 2566740734 AmberWarningLampStatus 5;
BA_ "SPN" SG_ 2566740734 RedStopLampState 623;
BA_ "SigType" SG_ 2566740734 RedStopLampState 4;
BA_ "SPN" SG_ 2566740734 ProtectLampStatus 987;
BA_ "SigType" SG_ 2566740734 ProtectLampStatus 5;
BA_ "SigType" SG_ 2566740734 DTC5 7;
BA_ "SigType" SG_ 2566740734 DTC4 7;
BA_ "SigType" SG_ 2566740734 DTC3 7;
BA_ "SigType" SG_ 2566740734 DTC2 7;
BA_ "SigType" SG_ 2566740734 DTC1 7;
BA_ "SPN" SG_ 2566740990 FlashRedStopLamp 3039;
BA_ "SigType" SG_ 2566740990 FlashRedStopLamp 5;
BA_ "SPN" SG_ 2566740990 FlashProtectLamp 3041;
BA_ "SigType" SG_ 2566740990 FlashProtectLamp 5;
BA_ "SPN" SG_ 2566740990 FlashMalfuncIndicatorLamp 3038;
BA_ "SigType" SG_ 2566740990 FlashMalfuncIndicatorLamp 5;
BA_ "SPN" SG_ 2566740990 FlashAmberWarningLamp 3040;
BA_ "SigType" SG_ 2566740990 FlashAmberWarningLamp 5;
BA_ "SPN" SG_ 2566740990 MalfunctionIndicatorLampStatus 1213;
BA_ "SigType" SG_ 2566740990 MalfunctionIndicatorLampStatus 5;
BA_ "SPN" SG_ 2566740990 AmberWarningLampStatus 624;
BA_ "SigType" SG_ 2566740990 AmberWarningLampStatus 5;
BA_ "SPN" SG_ 2566740990 RedStopLampState 623;
BA_ "SigType" SG_ 2566740990 RedStopLampState 4;
BA_ "SPN" SG_ 2566740990 ProtectLampStatus 987;
BA_ "SigType" SG_ 2566740990 ProtectLampStatus 5;
BA_ "SigType" SG_ 2566740990 DTC5 7;
BA_ "SigType" SG_ 2566740990 DTC4 7;
BA_ "SigType" SG_ 2566740990 DTC3 7;
BA_ "SigType" SG_ 2566740990 DTC2 7;
BA_ "SigType" SG_ 2566740990 DTC1 7;
BA_ "SPN" SG_ 2566741246 FlashRedStopLamp 3039;
BA_ "SigType" SG_ 2566741246 FlashRedStopLamp 5;
BA_ "SPN" SG_ 2566741246 FlashProtectLamp 3041;
BA_ "SigType" SG_ 2566741246 FlashProtectLamp 5;
BA_ "SPN" SG_ 2566741246 FlashMalfuncIndicatorLamp 3038;
BA_ "SigType" SG_ 2566741246 FlashMalfuncIndicatorLamp 5;
BA_ "SPN" SG_ 2566741246 FlashAmberWarningLamp 3040;
BA_ "SigType" SG_ 2566741246 FlashAmberWarningLamp 5;
BA_ "SPN" SG_ 2566741246 MalfunctionIndicatorLampStatus 1213;
BA_ "SigType" SG_ 2566741246 MalfunctionIndicatorLampStatus 5;
BA_ "SPN" SG_ 2566741246 AmberWarningLampStatus 624;
BA_ "SigType" SG_ 2566741246 AmberWarningLampStatus 5;
BA_ "SPN" SG_ 2566741246 RedStopLampState 623;
BA_ "SigType" SG_ 2566741246 RedStopLampState 4;
BA_ "SPN" SG_ 2566741246 ProtectLampStatus 987;
BA_ "SigType" SG_ 2566741246 ProtectLampStatus 5;
BA_ "SigType" SG_ 2566741246 DTC5 7;
BA_ "SigType" SG_ 2566741246 DTC4 7;
BA_ "SigType" SG_ 2566741246 DTC3 7;
BA_ "SigType" SG_ 2566741246 DTC2 7;
BA_ "SigType" SG_ 2566741246 DTC1 7;
BA_ "SPN" SG_ 2566741502 FlashRedStopLamp 3039;
BA_ "SigType" SG_ 2566741502 FlashRedStopLamp 5;
BA_ "SPN" SG_ 2566741502 FlashProtectLamp 3041;
BA_ "SigType" SG_ 2566741502 FlashProtectLamp 5;
BA_ "SPN" SG_ 2566741502 FlashMalfuncIndicatorLamp 3038;
BA_ "SigType" SG_ 2566741502 FlashMalfuncIndicatorLamp 5;
BA_ "SPN" SG_ 2566741502 FlashAmberWarningLamp 3040;
BA_ "SigType" SG_ 2566741502 FlashAmberWarningLamp 5;
BA_ "SPN" SG_ 2566741502 MalfunctionIndicatorLampStatus 1213;
BA_ "SigType" SG_ 2566741502 MalfunctionIndicatorLampStatus 5;
BA_ "SPN" SG_ 2566741502 AmberWarningLampStatus 624;
BA_ "SigType" SG_ 2566741502 AmberWarningLampStatus 5;
BA_ "SPN" SG_ 2566741502 RedStopLampState 623;
BA_ "SigType" SG_ 2566741502 RedStopLampState 4;
BA_ "SPN" SG_ 2566741502 ProtectLampStatus 987;
BA_ "SigType" SG_ 2566741502 ProtectLampStatus 5;
BA_ "SigType" SG_ 2566741502 DTC5 7;
BA_ "SigType" SG_ 2566741502 DTC4 7;
BA_ "SigType" SG_ 2566741502 DTC3 7;
BA_ "SigType" SG_ 2566741502 DTC2 7;
BA_ "SigType" SG_ 2566741502 DTC1 7;
VAL_ 2566764286 SPNSupportTypeSTR3 1 "SupportedInScaledTestResults" 0 "NotSupportedInScaledTestResults" ;
VAL_ 2566764286 SPNSupportTypeSTR2 1 "SupportedInScaledTestResults" 0 "NotSupportedInScaledTestResults" ;
VAL_ 2566764286 SPNSupportTypeEFF3 1 "SupportedInExFreezeFrame" 0 "NotSupportedInExFreezeFrame" ;
VAL_ 2566764286 SPNSupportTypeEFF2 1 "SupportedInExFreezeFrame" 0 "NotSupportedInExFreezeFrame" ;
VAL_ 2566764286 SPNSupportTypeDS3 1 "SupportedInDataStream" 0 "NotSupportedInDataStream" ;
VAL_ 2566764286 SPNSupportTypeDS2 1 "SupportedInDataStream" 0 "NotSupportedInDataStream" ;
VAL_ 2566764286 SPNSupportTypeSTR1 1 "SupportedInScaledTestResults" 0 "NotSupportedInScaledTestResults" ;
VAL_ 2566764286 SPNSupportTypeDS1 1 "SupportedInDataStream" 0 "NotSupportedInDataStream" ;
VAL_ 2566764286 SPNSupportTypeEFF1 1 "SupportedInExFreezeFrame" 0 "NotSupportedInExFreezeFrame" ;
VAL_ 2566764030 FlashRedStopLamp 3 "Unavailable / Do Not Flash" 2 "Reserved" 1 "Fast Flash" 0 "Slow Flash" ;
VAL_ 2566764030 FlashProtectLamp 3 "Unavailable / Do Not Flash" 2 "Reserved" 1 "Fast Flash" 0 "Slow Flash" ;
VAL_ 2566764030 FlashMalfuncIndicatorLamp 3 "Unavailable / Do Not Flash" 2 "Reserved" 1 "Fast Flash" 0 "Slow Flash" ;
VAL_ 2566764030 FlashAmberWarningLamp 3 "Unavailable / Do Not Flash" 2 "Reserved" 1 "Fast Flash" 0 "Slow Flash" ;
VAL_ 2566764030 MalfunctionIndicatorLampStatus 3 "Not available" 2 "Reserved" 1 "Lamp on" 0 "Lamp off" ;
VAL_ 2566764030 RedStopLampState 3 "Not available" 2 "Reserved" 1 "Lamp on" 0 "Lamp off" ;
VAL_ 2566764030 AmberWarningLampStatus 3 "Not available" 2 "Reserved" 1 "Lamp on" 0 "Lamp off" ;
VAL_ 2566764030 ProtectLampStatus 3 "Not available" 2 "Reserved" 1 "Lamp on" 0 "Lamp off" ;
VAL_ 2361655038 FailureModeIdentifier1 31 "Not available" 19 "Received network data in error" 18 "Below normal (moderately severe)" 17 "Below normal (least severe)" 16 "Above normal (moderately severe)" 15 "Above normal (least severe)" 14 "Special intstructions" 13 "Out of calibration" 12 "Bad intelligent device" 11 "Root cause not known" 10 "Abnormal rate of change" 9 "Abnormal update rate" 8 "Abnormal frequency" 7 "Mechanical system not responding" 6 "Current above normal" 5 "Current below normal" 4 "Voltage below normal" 3 "Voltage above normal" 2 "Data erratic" 1 "Below normal (most severe)" 0 "Above normal (most severe)" ;
VAL_ 2566834945 MalfunctionIndicatorLampStatus 3 "Not available" 2 "Reserved" 1 "Lamp on" 0 "Lamp off" ;
VAL_ 2566834945 RedStopLampState 3 "Not available" 2 "Reserved" 1 "Lamp on" 0 "Lamp off" ;
VAL_ 2566834945 AmberWarningLampStatus 3 "Not available" 2 "Reserved" 1 "Lamp on" 0 "Lamp off" ;
VAL_ 2566834945 ProtectLampStatus 3 "Not available" 2 "Reserved" 1 "Lamp on" 0 "Lamp off" ;
VAL_ 2566834945 FlashRedStopLamp 3 "Unavailable / Do Not Flash" 2 "Reserved" 1 "Fast Flash" 0 "Slow Flash" ;
VAL_ 2566834945 FlashProtectLamp 3 "Unavailable / Do Not Flash" 2 "Reserved" 1 "Fast Flash" 0 "Slow Flash" ;
VAL_ 2566834945 FlashMalfuncIndicatorLamp 3 "Unavailable / Do Not Flash" 2 "Reserved" 1 "Fast Flash" 0 "Slow Flash" ;
VAL_ 2566834945 FlashAmberWarningLamp 3 "Unavailable / Do Not Flash" 2 "Reserved" 1 "Fast Flash" 0 "Slow Flash" ;
VAL_ 2363031294 Seed 255 "NoFurtherKeyRequiredOfTool" 1 "UseLongSeedOrKeyFromDataSecMsg" 0 "SeedCompleted_BeginSendingKey" ;
VAL_ 2363031294 EDCP_Extension 9 "DataInErrIndAndDataInSeedIsTime" 6 "DataInErrorIndicator" 3 "ConcatenateDataAsLowerEDCParam" 2 "ConcatenateDataAsHigherEDCParam" 0 "Completed" 255 "NoErrIndicator/EDCParamAvailable" ;
VAL_ 2363031294 ErrorIndicator 16777215 "NoErrorIndicatorAvailable" 65540 "TransprtNotComplWithinTimeAllowd" 65539 "TransportNotInitWithinTimeAllowd" 65538 "NoResponseInTheTimeAllowed" 65537 "ModuleExceedingNumberOfRetries" 65536 "AbortFromExtToNormalSoftwareProc" 4103 "VehicleNotInParkOrNotStationary" 4102 "EngineRunning" 4101 "NotInEngineeringOrDevelopmentMode" 4100 "NotInDiagnosticMode" 4099 "InvalidKey" 4098 "InvalidUserLevel" 4097 "InvalidPassword" 4096 "SecurityErrorGeneral" 266 "NameDoesNotConformToExpectdValue" 265 "DataDoesNotConformToValueRanges" 264 "AddrForBootLoadExeInvalidBoundary" 263 "AddrForBootLoadExeOutsideExeMem" 262 "OpReqExeTransfAndEraseOfProgMem" 261 "OpRequiresPriorEraseOfProgramMem" 260 "OpRequiresPriorEraseOfDataMem" 259 "ReqMemoryExceededAvailableMemory" 258 "LengthNotValidForMemStructAndOp" 257 "AddressNotOnValidBoundary" 256 "AddressingOrDataGeneralError" 36 "InternalFailurePreventingReq" 35 "PROMDidNotVerifyOnWrite" 34 "FLASHDidNotVerifyOnWrite" 33 "RAMDidNotVerifyOnWrite" 32 "EDCParaNotCorrectForDataStream" 31 "ProcessUnspecReqFromThisAddress" 23 "ProcessingEDCPGenerationReq" 22 "ProcessingBootLoadReq" 19 "ProcessingStatusReq" 18 "ProcessingWriteReq" 17 "ProcessingReadReq" 16 "ProcessingEraseReq" 2 "ProcessingForSomeoneElse" 1 "ErrorNotIdentified" 0 "NoError" ;
VAL_ 2363031294 Status 7 "Reserved" 6 "Reserved" 5 "OperationFailed" 4 "OperationCompleted" 3 "Reserved" 2 "Reserved" 1 "Busy" 0 "Proceed" ;
VAL_ 2363096830 KeyOrUserLevel 65535 "NoKeyAvailable" 0 "UseLongSeedOrKey" ;
VAL_ 2363096830 PointerExtension 0 "SPN_SPACE" ;
VAL_ 2363096830 Command 7 "EDCP_Generation" 6 "BootLoad" 5 "OperationFailed" 4 "OperationCompleted" 3 "StatusRequest" 2 "Write" 1 "Read" 0 "Erase" ;
VAL_ 2363096830 PointerType 1 "DirectedSpatialAddressing" 0 "DirectMemoryAddressing" ;
VAL_ 2363490046 ProprietaryNetwork2 3 "Don't care" 2 "Reserved" 1 "Start broadcast" 0 "Stop broadcast" ;
VAL_ 2363490046 ProprietaryNetwork1 3 "Don't care" 2 "Reserved" 1 "Start broadcast" 0 "Stop broadcast" ;
VAL_ 2363490046 HoldSignal 15 "Not available" 1 "Devices whose broadcast state ha" 0 "All devices" ;
VAL_ 2363490046 J1939Network3 3 "Don't care" 2 "Reserved" 1 "Start broadcast" 0 "Stop broadcast" ;
VAL_ 2363490046 J1939Network2 3 "Don't care" 2 "Reserved" 1 "Start broadcast" 0 "Stop broadcast" ;
VAL_ 2363490046 ISO9141 3 "Don't care" 2 "Reserved" 1 "Start broadcast" 0 "Stop broadcast" ;
VAL_ 2363490046 SAE_J1850 3 "Don't care" 2 "Reserved" 1 "Start broadcast" 0 "Stop broadcast" ;
VAL_ 2363490046 ManufacturerSpecificPort 3 "Don't care" 2 "Reserved" 1 "Start broadcast" 0 "Stop broadcast" ;
VAL_ 2363490046 CurrentDataLink 3 "Don't care" 2 "Reserved" 1 "Start broadcast" 0 "Stop broadcast" ;
VAL_ 2363490046 SAE_J1587 3 "Don't care" 2 "Reserved" 1 "Start broadcast" 0 "Stop broadcast" ;
VAL_ 2363490046 SAE_J1922 3 "Don't care" 2 "Reserved" 1 "Start broadcast" 0 "Stop broadcast" ;
VAL_ 2363490046 J1939Network1 3 "Don't care" 2 "Reserved" 1 "Start broadcast" 0 "Stop broadcast" ;
VAL_ 2363490046 SuspendSignal 15 "NotAvailable" 14 "ResumingNormalBroadcastPattern" 3 "TemporarySuspensionOfSomeMessages" 2 "TemporarySuspensionOfAllBroadcasts" 1 "IndefiniteSuspensionOfSomeMessages" 0 "IndefiniteSuspensionOfAllBroadcasts" ;
VAL_ 2566837502 FlashRedStopLamp 3 "Unavailable / Do Not Flash" 2 "Reserved" 1 "Fast Flash" 0 "Slow Flash" ;
VAL_ 2566837502 FlashProtectLamp 3 "Unavailable / Do Not Flash" 2 "Reserved" 1 "Fast Flash" 0 "Slow Flash" ;
VAL_ 2566837502 MalfunctionIndicatorLampStatus 3 "Not available" 2 "Reserved" 1 "Lamp on" 0 "Lamp off" ;
VAL_ 2566837502 RedStopLampState 3 "Not available" 2 "Reserved" 1 "Lamp on" 0 "Lamp off" ;
VAL_ 2566837502 AmberWarningLampStatus 3 "Not available" 2 "Reserved" 1 "Lamp on" 0 "Lamp off" ;
VAL_ 2566837502 ProtectLampStatus 3 "Not available" 2 "Reserved" 1 "Lamp on" 0 "Lamp off" ;
VAL_ 2566837502 FlashMalfuncIndicatorLamp 3 "Unavailable / Do Not Flash" 2 "Reserved" 1 "Fast Flash" 0 "Slow Flash" ;
VAL_ 2566837502 FlashAmberWarningLamp 3 "Unavailable / Do Not Flash" 2 "Reserved" 1 "Fast Flash" 0 "Slow Flash" ;
VAL_ 2566834942 FlashRedStopLamp 3 "Unavailable / Do Not Flash" 2 "Reserved" 1 "Fast Flash" 0 "Slow Flash" ;
VAL_ 2566834942 FlashProtectLamp 3 "Unavailable / Do Not Flash" 2 "Reserved" 1 "Fast Flash" 0 "Slow Flash" ;
VAL_ 2566834942 FlashMalfuncIndicatorLamp 3 "Unavailable / Do Not Flash" 2 "Reserved" 1 "Fast Flash" 0 "Slow Flash" ;
VAL_ 2566834942 FlashAmberWarningLamp 3 "Unavailable / Do Not Flash" 2 "Reserved" 1 "Fast Flash" 0 "Slow Flash" ;
VAL_ 2566834942 MalfunctionIndicatorLampStatus 3 "Not available" 2 "Reserved" 1 "Lamp on" 0 "Lamp off" ;
VAL_ 2566834942 AmberWarningLampStatus 3 "Not available" 2 "Reserved" 1 "Lamp on" 0 "Lamp off" ;
VAL_ 2566834942 RedStopLampState 3 "Not available" 2 "Reserved" 1 "Lamp on" 0 "Lamp off" ;
VAL_ 2566834942 ProtectLampStatus 3 "Not available" 2 "Reserved" 1 "Lamp on" 0 "Lamp off" ;
VAL_ 2365454334 UtlityOverallPowerFactorLagging 3 "Not Available or Not Installed" 2 "Error" 1 "Lagging" 0 "Leading" ;
VAL_ 2365452030 UtilityPhaseCPowerFactorLagging 3 "Not Available or Not Installed" 2 "Error" 1 "Lagging" 0 "Leading" ;
VAL_ 2365452798 UtilityPhaseBPowerFactorLagging 3 "Not Available or Not Installed" 2 "Error" 1 "Lagging" 0 "Leading" ;
VAL_ 2365453566 UtilityPhaseAPowerFactorLagging 3 "Not Available or Not Installed" 2 "Error" 1 "Lagging" 0 "Leading" ;
VAL_ 2365457662 GnrtorOverallPowerFactorLagging 3 "NotAvailable_NotInstalled" 2 "Error" 1 "Lagging" 0 "Leading" ;
VAL_ 2365455358 GnratorPhaseCPowerFactorLagging 3 "NotAvailable_NotInstalled" 2 "Error" 1 "Lagging" 0 "Leading" ;
VAL_ 2365456126 GnratorPhaseBPowerFactorLagging 3 "NotAvailable_NotInstalled" 2 "Error" 1 "Lagging" 0 "Leading" ;
VAL_ 2365456894 GnratorPhaseAPowerFactorLagging 3 "NotAvailable_NotInstalled" 2 "Error" 1 "Lagging" 0 "Leading" ;
VAL_ 2365450238 Bus1_UtilityInSync 3 "NotAvailable" 2 "Error" 1 "Sycnchronized" 0 "NotSynchronized" ;
VAL_ 2365450238 Bus1_UtilityVoltageMatch 3 "NotAvailable" 2 "Error" 1 "VoltagesMatch" 0 "VolatagesDoNotMatch" ;
VAL_ 2365450238 Bus1_UtilityFrequencyMatch 3 "NotAvailable" 2 "Error" 1 "FrequenciesMatch" 0 "FrequenciesDoNotMatch" ;
VAL_ 2365450238 Bus1_UtilityPhaseMatch 3 "NotAvailable" 2 "Error" 1 "PhasesMatch" 0 "PhasesDoNotMatch" ;
VAL_ 2365450238 Bus1_UtilityDeadBus 3 "NotAvailable" 2 "Error" 1 "BusIsDead" 0 "BusIsNotDead" ;
VAL_ 2365450494 Bus1_GeneratorInSync 3 "NotAvailable" 2 "Error" 1 "Sycnchronized" 0 "NotSynchronized" ;
VAL_ 2365450494 Bus1_GeneratorVoltageMatch 3 "NotAvailable" 2 "Error" 1 "VoltagesMatch" 0 "VolatagesDoNotMatch" ;
VAL_ 2365450494 Bus1_GeneratorFrequencyMatch 3 "NotAvailable" 2 "Error" 1 "FrequenciesMatch" 0 "FrequenciesDoNotMatch" ;
VAL_ 2365450494 Bus1_GeneratorPhaseMatch 3 "NotAvailable" 2 "Error" 1 "PhasesMatch" 0 "PhasesDoNotMatch" ;
VAL_ 2365450494 Bus1_GeneratorDeadBus 3 "NotAvailable" 2 "Error" 1 "BusIsDead" 0 "BusIsNotDead" ;
VAL_ 2566838526 IndustryGroup 6 "Reserved for SAE" 7 "Reserved for SAE" 5 "IndustrialProcessCtrlStationary" 4 "Marine" 3 "Construction" 2 "Agricultural and Forestry" 1 "On-Highway" 0 "Global" ;
VAL_ 2566838526 Function 127 "Reserved" 126 "Reserved" 125 "Reserved" 124 "Reserved" 123 "Reserved" 122 "Reserved" 121 "Reserved" 120 "Reserved" 119 "Reserved" 118 "Reserved" 117 "Reserved" 116 "Reserved" 115 "Reserved" 114 "Reserved" 113 "Reserved" 112 "Reserved" 111 "Reserved" 110 "Reserved" 109 "Reserved" 108 "Reserved" 107 "Reserved" 106 "Reserved" 105 "Reserved" 104 "Reserved" 103 "Reserved" 102 "Reserved" 101 "Reserved" 42 "Water Pump Control" 41 "Lighting - Operator Controls" 40 "Seat Control" 39 "Ignition Control Module" 38 "Tire Pressure Control" 37 "Cab Controller" 36 "Pneumatic - System Controller" 35 "Suspension - System Controller" 34 "Hydraulic Pump Controller" 33 "System Monitor" 32 "Headway Controller" 31 "Propulsion Battery Charger" 30 "Management Computer" 29 "Virtual Terminal (in cab)" 28 "Off Vehicle Gateway" 27 "Power TakeOff (Secondary or Front)" 26 "Body Controller" 25 "Network Interconnect ECU" 24 "Vehicle Security" 23 "Vehicle Navigation" 22 "Aerodynamic Control" 21 "Cab Climate Control" 20 "Trip Recorder" 19 "Instrument Cluster" 18 "Suspension - Drive Axle" 17 "Suspension - Steer Axle" 16 "Steering Controller" 15 "Fuel System" 14 "Cruise Control" 13 "Retarder - Driveline" 12 "Retarder - Engine" 11 "Brakes - Drive Axle" 10 "Brakes - Steer Axle" 9 "Brakes - System Controller" 8 "Axle - Drive" 7 "Axle - Steering" 6 "Power TakeOff - (Main or Rear)" 5 "Shift Control/Console" 4 "Battery Pack Monitor" 3 "Transmission" 2 "Electric Propulsion Control" 1 "Auxiliary Power Unit (APU)" 0 "Engine" 100 "Reserved" 99 "Reserved" 98 "Reserved" 97 "Reserved" 96 "Reserved" 95 "Reserved" 94 "Reserved" 93 "Reserved" 92 "Reserved" 91 "Reserved" 90 "Reserved" 89 "Reserved" 88 "Reserved" 87 "Reserved" 86 "Reserved" 85 "Reserved" 84 "Reserved" 83 "Reserved" 82 "Reserved" 81 "Reserved" 80 "Reserved" 79 "Reserved" 78 "Fire Suppression System" 77 "Fuel Properties Sensor" 76 "Temperature Sensor" 75 "Supplemental Fan" 74 "Lubrication System" 73 "Rollover Detection Control" 72 "Coolant Valve Controller" 71 "Transfer Case Control" 70 "Auxiliary Regeneration Device" 69 "Engine Emission Aftertreatement System" 68 "Aftertreatment system gas measurement" 67 "Electrical System Controller" 66 "I/O Controller" 65 "Gas Flow Measurement" 64 "Endurance Braking" 63 "Engine Valve Controller" 62 "On-Board Diagnostic Unit" 61 "File Server/Printer" 60 "Cab Display" 59 "Starter" 58 "Fan Drive Control" 57 "Steering Column Unit" 56 "Communications Unit, Radio" 55 "Communications Unit, Satellite" 54 "Communications Unit, Cellular" 53 "Alternator/Charging System" 52 "Chassis Controller" 51 "Forward-Looking Collision Warning System" 50 "Auxiliary Heater" 49 "Clutch/Converter Control" 48 "Ramp Control" 47 "Information System Controller" 46 "Oil Sensor Unit" 45 "Vehicle Dynamic Stability Control" 44 "Exhaust Emission Control" 43 "Transmission Display" ;
VAL_ 2566838526 VehicleSystem 0 "Non-specific System" 127 "Not Available" ;
VAL_ 2566838526 ManufacturerCode 454 "NGK Spark Plug Co. Ltd" 453 "Cooper Bussmann" 452 "WIKA Alexander Wiegand SE & Co. KG" 451 "Parker Hannifin Corp" 450 "Dycor Technologies Ltd." 449 "Polaris Industries Inc" 448 "Stanadyne Corporation, Electronics Systems" 447 "Great Plains Mfg." 446 "CertTech, L.L.C." 445 "KAT MECHATRONIC, Electronic Product Division" 444 "ITT Power Solutions" 443 "SignalQuest, Inc." 442 "Horsch Maschinen GmbH" 441 "PTG Reifendruckregelsysteme GmbH" 440 "Cummins Power Generation" 439 "Hyundai Heavy Industries" 438 "Comar Systems Ltd" 437 "Digital Yacht Limited" 436 "Kinze Manufacturing" 435 "Zunhammer GmbH" 434 "Stored Energy Systems" 433 "Rowe Electronics" 432 "S&A Systems, Inc." 431 "Tohatsu Corporation" 430 "Auteq Telematica S.A." 520 "Trapeze" 519 "Peeters Landbouwmachines b.v." 518 "Transas USA Inc." 517 "Noland Engineering" 516 "AVAT Automation GmbH" 515 "GINAF Trucks Nederland B.V." 514 "DISTek Integration, Inc." 513 "FarmscanAg" 512 "Inpower LLC" 511 "Sulky" 510 "Marinesoft Co. Ltd" 509 "MOTORTECH GmbH" 508 "Transtech Innovations" 507 "Test Center ISOBUS" 506 "IHI STAR Machinery Corporation" 505 "Yetter Farm Equipment" 504 "Vesper Marine" 503 "Naviop S.R.L." 502 "Attwood Corporation" 501 "Agrotronix S.A." 500 "Oxbo International Corporation" 499 "LCJ Capteurs" 498 "Innovative Design Solutions, Inc" 497 "SENTRON Sistemas Embarcados" 496 "W. Gessmann GmbH" 495 "HOLMER Maschinenbau GmbH" 494 "Synerject" 493 "Watcheye" 492 "Inergy Automotive Systems" 491 "Penny and Giles Ltd" 490 "QuikQ" 489 "Appareo Systems" 488 "The Charles Machine Works, Inc." 487 "DSE Test Solutions A/S" 486 "Westport Innovations Inc." 485 "MATT automotive" 484 "Headsight Inc." 483 "Valeo" 482 "Tricon Electronics" 481 "Chetco Digital Instruments" 480 "EnerDel, Inc." 479 "Vapor Bus International" 478 "OceanSat BV" 477 "OilQuick AB" 476 "Hummingbird Marine Electronics" 475 "GME" 474 "Persen Technologies Inc." 473 "Boss Industries, Inc." 472 "Tenneco Inc." 471 "Sea Cross Marine AB" 470 "SI-TEX Marine Electronics" 469 "RA Consulting GmbH" 468 "Tyco Fire Protection Products" 467 "Lely Industries N.V." 466 "Veethree Electronics and Marine LLC" 465 "Ashcroft Inc" 464 "Leach International Corporation" 463 "PROBOTIQ" 462 "IHI Shibaura Machinery Corporation" 461 "HAWE Hydraulik SE" 460 "San Giorgio S.E.I.N." 459 "Alltek Marine Electronics Corp" 458 "Control Solutions, Inc." 457 "RUSELPROM-ElectricDrive Ltd" 456 "General Kinetics" 455 "ADZ NAGANO GmbH" 429 "Rota Engineering Ltd." 428 "Mfg_428" 427 "em-trak Marine Electronics Ltd" 426 "Egersund Marine Electronics AS" 425 "Methode Electronics Inc, MDI" 424 "Odyne LLC" 423 "BSM Wireless, Inc." 422 "True Heading AB" 421 "Vertex Standard Co, Ltd" 420 "Vermeer Corporation, ACS Group" 419 "Fusion Electronics Ltd" 418 "Intellistick Inc" 417 "KZValve" 416 "Kubota Corporation" 415 "Valid Manufacturing Ltd." 414 "Cattron Group International" 413 "Datapross Nijbroek bv" 412 "WebTech Wireless Inc." 411 "Hy-Drive Technologies Ltd." 410 "COBO S.p.A. Divisione 3B6" 409 "Transfluid S.r.L." 408 "Corvus Energy Ltd." 407 "Comtech Mobile Datacom" 406 "Vecima Networks Inc." 405 "Wema System AS" 404 "Com Nav Marine Ltd" 403 "Trackwell ADS, Inc." 402 "Simma Software, Inc." 401 "Torqeedo GmbH" 400 "Livorsi Marine" 399 "ISEKI & Co., Ltd." 398 "Hilite International" 397 "Sanyo-kiki Co Ltd." 396 "Beyond Measure" 395 "GENTEC S.R.L." 394 "Capi 2 Nederland BV" 393 "Harvest Tec, Inc" 392 "Tianyuan Technology Co Ltd." 391 "Electronic Design for Industry, Inc" 390 "Partech Inc." 389 "Benchmark Electronics, Minnesota Division" 388 "Innomatix, LLC" 387 "Orscheln Products, LLC" 386 "JLG Automation BVBA" 385 "Johnson Outdoor Marine Electronics" 384 "Camano Light" 383 "MCL Industries" 382 "National Agricultural and Food Research Organization" 380 "Suntech International Ltd." 379 "Yamabiko Corporation" 378 "Glendinning Marine Products" 377 "ifm electronic gmbh" 376 "Quake Global" 375 "Williams Controls Inc." 372 "Delphi" 381 "B&G" 374 "Northern Lights, Inc." 373 "Electronic Design Inc." 371 "Heinzmann GmbH & Co. KG" 370 "Rolls-Royce Marine AS" 369 "Power Torque Engineering Ltd" 368 "HANSENHOF_electronic" 367 "Fliegl Agrartechnik" 366 "Viewnyx Corp." 365 "Digi-Star, LLC" 364 "OEM Controls Inc." 363 "BEI Duncan" 362 "Alois Poettinger Maschinenfabrik GmbH" 361 "InMach" 360 "HJS Emission Technology GmbH & Co KG" 359 "Ludwig Bergmann GmbH" 358 "Victron Energy BV" 357 "Hardi International A/S" 356 "Fischer Panda Generators, Inc" 355 "Mastervolt International B.V." 354 "Junkkari OY" 353 "Hegemon Electronics, Inc." 352 "SAME DEUTZ-FAHR" 351 "Thrane & Thrane" 350 "Noris Marine Systems GmbH & Co KG" 349 "Suonentiet" 348 "Amazonen Werke H. Dreyer" 347 "Honeywell" 346 "Control Solutions" 345 "Korean Maritime University" 344 "Parvus Corporation" 343 "Baumer Group" 342 "THOMAS MAGNETE GmbH" 341 "Boning GmbH & Co" 340 "Continental AG" 339 "Competence Center ISOBUS e.V." 338 "GRAF-SYTECO" 337 "Carraro S.p.A." 336 "APE s.r.o." 335 "Evo Electric Ltd" 334 "Takata-Petri AG" 333 "Hadley Products Corporation" 332 "HWH Corporation" 331 "Horton, Inc." 330 "Kidde Aerospace and Defense" 329 "Deif A/S" 328 "Qwerty Electronik AB" 252 "Sensor-Technik Wiedemann GmbH" 251 "German Agricultural Society" 250 "Kuhn Group" 249 "Schaltbau GmbH" 233 "Yacht Monitoring Solutions Inc." 232 "TSD Integrated Controls" 1863 "Thomas G. Faria Co." 1862 "Sanshin" 1861 "Vector CANtech" 1860 "MMP" 1859 "Kvasar AB" 1858 "Litton" 1857 "Simrad" 1856 "Trimble" 1855 "Furuno USA" 1854 "Northstar Technologies" 1853 "Japan Radio Co." 1852 "Navionics" 1851 "Raymarine" 1850 "Teleflex" 222 "Generac Power Systems, Inc." 221 "SiE" 220 "Beede Electrical Instrument Company, Inc." 219 "Cat OEM Solutions" 218 "Gits Manufacturing Company" 217 "RM Michaelides Software & Elektronik GmbH" 216 "Paneltronics Inc." 215 "Aetna Engineering/Fireboy-Xintex" 214 "MC elettronica Srl" 213 "CNH Belgium N.V." 212 "Sure Power Industries, Inc." 211 "DNA Group" 210 "Iteris, Inc." 209 "Bell Equip. Co. SA (PTY) LTD" 208 "Drew Technologies, Inc." 207 "Otto Engineering" 206 "port GmbH" 205 "SmarTire Systems Inc" 204 "The Morey Corporation" 203 "MILtronik GmbH" 202 "Curtis Instruments, Inc." 201 "Disenos y Tecnologia S.A." 200 "MGM Brakes" 199 "Actia Corp." 198 "Mystic Valley Communications" 197 "Mechron Power Systems" 196 "LEMKEN GmbH & Co. KG" 195 "General Engine Products" 194 "TriMark Corporation" 193 "Nobletec" 192 "Floscan" 191 "XRS Corporation" 190 "Hella KGaA Hueck & Co." 189 "QUALCOMM" 188 "EMP Corp." 187 "Air-Weigh" 186 "Altronic, Inc." 185 "Beede Electrical Instrument Company" 184 "EIA Electronics" 183 "KDS Controls, Inc." 182 "Vehicle Systems Engineering B.V." 181 "Coretronics, Inc." 180 "Smart Power Systems" 179 "TeeJet Technologies Denmark" 178 "Siemens VDO Automotive AG" 177 "Diagnostic System Associates" 176 "Moritz Aerospace" 175 "Veris Technologies, Inc." 174 "AB Volvo Penta" 173 "Ryeso, Inc." 172 "Yanmar Marine USA" 171 "Wachendorff Elektronik GmbH & Co. KG" 170 "Computronics Corporation Ltd." 169 "Marlin Technologies Inc." 168 "Xantrex" 167 "JLG Industries Inc." 166 "Phoenix International" 165 "CPAC Systems AB" 164 "DaimlerChrysler Off-Highway" 163 "BRP Inc." 162 "Axiomatic Technologies" 161 "Offshore Systems (UK) Limited" 160 "Nido" 159 "NTech Industries Inc." 158 "Firestone Industrial Products Company" 157 "ISSPRO Inc." 156 "ITT Industries - Cannon" 155 "Vetronix Corporation" 154 "Westerbeke Corporation" 153 "Woodward, Industrial Controls Division" 152 "elobau GmbH & Co. KG" 151 "Raven Industries Inc. - Flow Controls Division" 150 "Fleetguard" 149 "Holset" 148 "Blue Water Data, Inc." 147 "Nautibus Electronic GmbH" 146 "Maxima Technologies" 145 "MurCal Controls" 144 "Mercury Marine" 143 "W. Gmeiner GmbH & Co." 142 "TRW Automotive (Commercial Steering Systems)" 141 "Thales Navigation Ltd." 140 "Lowrance Electronics, Inc." 139 "Caterpillar Trimble Control Technologies (CTCT), LLC" 138 "Georg Fritzmeier GmbH & Co. KG" 137 "Maretron" 136 "Komatsu Ltd." 135 "Airmar Technology Corporation" 134 "Iris Technology Ltd." 133 "Bucher Schoerling GmbH" 132 "Mulag-Fahrzeugwerk" 131 "ITT Industries" 130 "Nido - Universal Machines B.V." 129 "OMNEX Control Systems, Inc." 128 "Gerhard Duecker GmbH & Co. KG" 127 "Holland USA" 126 "Driver Tech" 125 "Nevada Automotive Test Center" 124 "Hydac Electronic" 123 "Basler Electric" 122 "FG Wilson (Engineering) Limited" 121 "HED (Hydro Electronic Devices, Inc.)" 120 "RDS Technology Ltd." 119 "IntegriNautics" 118 "Intron GmbH" 117 "HUSCO International" 116 "BEELINE Technologies" 115 "NACCO Materials Handling Group, Inc." 114 "EControls, Inc." 113 "Stress-Tek, Inc." 112 "MECALAC" 111 "Maschinenfabrik Bernard Krone GmbH" 110 "EPIQ Sensor-Nite" 109 "TeeJet Technologies Denmark" 108 "WTK-Elecktronik GmbH" 107 "Grimme Landmaschinen GmbH & Co. KG" 106 "BAE Systems Controls, Inc." 105 "Kiepe Elektrik GmbH & Co. KG" 104 "Claas Selbstfahrende Erntemaschinen GmbH" 103 "CLAAS Agrosystems GmbH & Co. KG" 102 "AGCO GmbH & Co." 101 "Sensoria" 100 "VDO Technik AG" 99 "International Transmissions Ltd (ITL)" 98 "Mueller-Elektronik GmbH & Co." 97 "Ag Leader Technology, Inc." 96 "Mech@tronic IT GmbH" 95 "Pacific Insight Electronics Corp." 94 "CNH Global N.V." 93 "Perkins Engines Company Ltd." 92 "Ag-Chem Equipment Co., Inc." 91 "BSG Bodensee Steuergeraete GmbH" 90 "Knorr-Bremse SfN GmbH" 89 "Kverneland Group, Electronics Division" 88 "Satloc Precision GPS" 87 "J.C. Bamford Excavators Ltd (JCB)" 86 "C.E. Niehoff & Company" 85 "Kohler Co." 84 "New Holland UK Limited" 83 "Bendix VORAD Technologies" 82 "Bobcat/Ingersoll-Rand" 81 "Fire Research Corp" 80 "Twin Disc, Inc." 79 "Daimler Benz AG - Engine Division (PBM)" 78 "Frank W. Murphy Manufacturing, Inc." 77 "Deere Power Systems Group" 76 "unused" 75 "Deere & Co. Agricultural Division" 74 "Eaton Axle-Brake Division" 73 "LeTourneau, Inc." 72 "Sisu Corporation" 71 "Vansco Electronics Ltd." 70 "Flex-Coil Limited" 69 "Trimble Navigation" 68 "Scania" 67 "Funk Manufacturing Company" 66 "John Deere Construction Equipment Division" 65 "MAN Nutzfahrzeuge AG" 64 "unused" 63 "ZF Industries Inc." 62 "Wabco" 61 "Volvo Truck Corp." 60 "Volvo Trucks North America Inc." 59 "VES Inc." 58 "SPX Corporation, OTC Division" 57 "Sauer-Danfoss Co." 56 "SAIC" 55 "Ryder System Inc." 54 "Meritor Wabco" 53 "Continental Automotive Systems US, Inc." 52 "Meritor Automotive, Inc." 51 "Robert Bosch GmbH" 50 "Robert Bosch Corp" 49 "RE America Inc." 48 "Pollak Alphabet" 47 "Phillips Semiconductor" 46 "Noregon Systems, Inc" 45 "PACCAR" 44 "Nippondenso Co. Ltd." 43 "International Truck and Engine Corp. Vehicle Electronics" 42 "International Truck and Engine Corp. Engine Electronics" 41 "Motorola Inc." 40 "Motorola AIEG Inc." 39 "Microfirm Inc." 38 "Micro Processor Systems Inc." 37 "Mack Trucks Inc." 36 "Lucas Ltd." 35 "Kenworth Truck Co." 34 "Kelsey Hayes Co." 33 "John Deere" 32 "Jacobs Vehicle Systems" 31 "J Pollak Corp." 30 "Isuzu Motors Ltd." 29 "Hino Motors Ltd." 28 "Grote Ind. Inc." 27 "GMC" 26 "General Motors Corp., Service Technology Group" 25 "Daimler Trucks North America LLC" 24 "Ford Motor Co., Vehicle Controls" 23 "Ford Motor Co., Heavy Truck" 22 "Ford Motor Co., Electronic Concepts $ Systems" 21 "Echilin Inc., Midland Brake Inc." 20 "Eaton Ltd" 19 "Eaton Corp. Trucking Info Services" 18 "Eaton Corp, Transmission Division" 17 "Eaton Corp. Res & Dev" 16 "Eaton Corp." 15 "Dickey-John Corp." 14 "Detroit Diesel Corporation" 13 "Delco Electronics" 12 "Deere & Company, Precision Farming" 11 "Dearborn Group Inc." 10 "Cummins Engine Co." 9 "Chrysler Corp." 8 "Caterpillar Inc." 7 "Case Corp." 6 "Berifors Electronics AB" 5 "AMP Inc." 4 "Ametek-Dixson" 3 "Ametek, US Gauge Division" 2 "Allison Transmission, GMC" 1 "Allied Signal Inc." 0 "Reserved" 231 "Topcon Positioning Systems, Inc." 230 "Saucon Technologies" 229 "Garmin International Inc." 228 "ZF Marine Electronics" 227 "Lykketronic A/S" 226 "Monaco Coach Corporation" 225 "SKF" 224 "EMMI Network, S.L." 223 "Vaueo Retarder Co., Ltd." 263 "IMMI" 262 "HydraForce, Inc" 261 "Red Dot Corporation" 260 "Reichhardt GmbH" 259 "Jetter AG" 258 "ARAG" 257 "Honda Motor Co., Ltd" 256 "Tyco Electronics AMP" 255 "MEAS France" 254 "GE Sensing" 253 "Mobile Control Systems" 298 "Holley Performance" 297 "Zonar Systems Inc" 296 "micro dynamics GmbH" 295 "BEP Marine" 294 "Grayhill Inc." 293 "Spyder Controls Corp." 292 "IKUSI - Angel Iglesias S.A." 291 "Groeneveld Transport Efficiency BV" 290 "Kuebler GmbH" 289 "Watlow" 288 "Mitsubishi FUSO Truck & Bus Corp." 287 "NTech Industries, Inc" 286 "Coelmo srl" 285 "Sea Recovery Corp" 284 "Mobile Tech Chile" 283 "CWF Hamilton & Co Ltd" 282 "Medallion Instrumentation Systems" 281 "Precision Governors LLC" 311 "Patrick Power Products" 310 "TECNORD srl" 309 "Krauss-Maffei Wegmann GmbH & Co. KG" 308 "Cyntrx" 307 "MBW Technologies" 306 "Sleipner Motor AB" 305 "NovAtel Inc" 304 "EmpirBus AB" 303 "CTS Corporation" 302 "Nissin Kogyo Co., LTD" 301 "Parker Hannifin (UK) Ltd FDE group" 300 "Systron Donner Automotive" 299 "Rauch Landmaschinen GmbH" 280 "Leica Geosystems Pty Ltd" 279 "Geometris LP" 278 "Takata Electronics" 277 "LHP Telematics" 276 "Aqua-Hot Heating Systems" 275 "Navico Egersund AS" 274 "LTW Technology Co., LTD" 273 "Active Research Limited" 272 "Gross Mechanical Laboratories, Inc" 327 "Sonceboz SA" 326 "Akron Brass Company" 325 "ASM Automation Sensorik Messtechnik GmbH" 324 "Snap-on Diagnostics" 323 "Mobileye Vision Technologies Ltd." 322 "MICHENKA s.r.o." 321 "Ultra Electronics, Electrics" 320 "Miedema Landbouwwerktuigenfabriek B.V." 319 "Cadec Global" 318 "SAT Plan" 317 "Navtronics Bvba" 316 "ITT Flow Control" 315 "Icom Incorporated" 314 "CSM GmbH" 313 "Ilmor Engineering, Inc" 312 "Lectronix, Inc." 271 "Cole Hersee" 270 "Tennant" 269 "Saft America Inc.,  Space & Defense Division" 268 "Accurate Technologies" 267 "Red Lion Controls, Inc" 266 "International Thermal Research Ltd" 265 "MTS Sensor Technologie GmbH" 264 "Autolync" 248 "Cooper Standard Automotive Active Systems Group" 247 "ePULSE" 246 "Class 1, Inc" 245 "Capstan Ag Systems, Inc." 244 "Techno-Matic" 243 "eRide, Inc." 242 "Kokusandenki Co. Ltd" 241 "Schneider Automation SAS " 240 "Vanair Mfg" 239 "May & Scofield Ltd" 238 "ZF Friedrichshafen AG" 237 "Agtron Enterprises Inc" 236 "Norac Systems International Inc" 235 "SailorMade Marine Telemetry - Tetra Technology Ltd." 234 "Mondial electronic GmbH" ;
VAL_ 2566838526 VehicleSystem5 127 "Not Available" 0 "Ind. Process Control Stationary" ;
VAL_ 2566838526 VehicleSystem4 125 "Entertainment" 120 "Display" 85 "External Environment" 75 "Sensor Communication Interface" 35 "Electrical Generation" 100 "Deck, Cargo and Fishing Equipment" 90 "Internal Environment" 80 "Instrumentation/General Systems (deprecate)" 70 "Communications" 60 "Navigation" 50 "Propulsion" 40 "Steering and Control Surfaces" 30 "Electrical Distribution" 25 "Inter/Intranetwork Device" 20 "Safety Systems" 10 "System Tools" 127 "Not Available" 0 "Non-specific System" ;
VAL_ 2566838526 VehicleSystem3 8 "Grader" 7 "Four Wheel Drive Loader" 6 "Forklift" 5 "Excavator" 4 "Crawler" 3 "Backhoe" 2 "Articulated Dump Truck" 1 "Skid Steer Loader" 127 "Not Available" 0 "Non-specific System" ;
VAL_ 2566838526 VehicleSystem2 25 "Slurry Applicators" 24 "Utility Vehicles" 23 "Mulchers" 22 "Timber Processing Machines" 21 "Timber loaders" 20 "Forwarders" 19 "Timber Harvesters" 17 "Sensor Systems" 16 "Skidder" 15 "Earth Work" 14 "Special Crops" 13 "Powered Auxiliary Device" 12 "Farm Yard Operations" 11 "Transport/Trailer" 10 "Irrigation" 9 "Forage" 8 "Root Harvesters" 7 "Harvesters" 6 "Sprayers" 5 "Fertilizers" 4 "Planters/Seeders" 3 "Secondary Tillage" 2 "Tillage" 1 "Tractor" 127 "Not Available" 0 "Non-specific System" ;
VAL_ 2566838526 VehicleSystem1 2 "Trailer" 1 "Tractor" 127 "Not Available" 0 "Non-specific System" ;
VAL_ 2364473086 IndustryGroup 6 "Reserved for SAE" 7 "Reserved for SAE" 5 "IndustrialProcessCtrlStationary" 4 "Marine" 3 "Construction" 2 "Agricultural and Forestry" 1 "On-Highway" 0 "Global" ;
VAL_ 2364473086 Function 127 "Reserved" 126 "Reserved" 125 "Reserved" 124 "Reserved" 123 "Reserved" 122 "Reserved" 121 "Reserved" 120 "Reserved" 119 "Reserved" 118 "Reserved" 117 "Reserved" 116 "Reserved" 115 "Reserved" 114 "Reserved" 113 "Reserved" 112 "Reserved" 111 "Reserved" 110 "Reserved" 109 "Reserved" 108 "Reserved" 107 "Reserved" 106 "Reserved" 105 "Reserved" 104 "Reserved" 103 "Reserved" 102 "Reserved" 101 "Reserved" 42 "Water Pump Control" 41 "Lighting - Operator Controls" 40 "Seat Control" 39 "Ignition Control Module" 38 "Tire Pressure Control" 37 "Cab Controller" 36 "Pneumatic - System Controller" 35 "Suspension - System Controller" 34 "Hydraulic Pump Controller" 33 "System Monitor" 32 "Headway Controller" 31 "Propulsion Battery Charger" 30 "Management Computer" 29 "Virtual Terminal (in cab)" 28 "Off Vehicle Gateway" 27 "Power TakeOff (Secondary or Front)" 26 "Body Controller" 25 "Network Interconnect ECU" 24 "Vehicle Security" 23 "Vehicle Navigation" 22 "Aerodynamic Control" 21 "Cab Climate Control" 20 "Trip Recorder" 19 "Instrument Cluster" 18 "Suspension - Drive Axle" 17 "Suspension - Steer Axle" 16 "Steering Controller" 15 "Fuel System" 14 "Cruise Control" 13 "Retarder - Driveline" 12 "Retarder - Engine" 11 "Brakes - Drive Axle" 10 "Brakes - Steer Axle" 9 "Brakes - System Controller" 8 "Axle - Drive" 7 "Axle - Steering" 6 "Power TakeOff - (Main or Rear)" 5 "Shift Control/Console" 4 "Battery Pack Monitor" 3 "Transmission" 2 "Electric Propulsion Control" 1 "Auxiliary Power Unit (APU)" 0 "Engine" 100 "Reserved" 99 "Reserved" 98 "Reserved" 97 "Reserved" 96 "Reserved" 95 "Reserved" 94 "Reserved" 93 "Reserved" 92 "Reserved" 91 "Reserved" 90 "Reserved" 89 "Reserved" 88 "Reserved" 87 "Reserved" 86 "Reserved" 85 "Reserved" 84 "Reserved" 83 "Reserved" 82 "Reserved" 81 "Reserved" 80 "Reserved" 79 "Reserved" 78 "Fire Suppression System" 77 "Fuel Properties Sensor" 76 "Temperature Sensor" 75 "Supplemental Fan" 74 "Lubrication System" 73 "Rollover Detection Control" 72 "Coolant Valve Controller" 71 "Transfer Case Control" 70 "Auxiliary Regeneration Device" 69 "Engine Emission Aftertreatement System" 68 "Aftertreatment system gas measurement" 67 "Electrical System Controller" 66 "I/O Controller" 65 "Gas Flow Measurement" 64 "Endurance Braking" 63 "Engine Valve Controller" 62 "On-Board Diagnostic Unit" 61 "File Server/Printer" 60 "Cab Display" 59 "Starter" 58 "Fan Drive Control" 57 "Steering Column Unit" 56 "Communications Unit, Radio" 55 "Communications Unit, Satellite" 54 "Communications Unit, Cellular" 53 "Alternator/Charging System" 52 "Chassis Controller" 51 "Forward-Looking Collision Warning System" 50 "Auxiliary Heater" 49 "Clutch/Converter Control" 48 "Ramp Control" 47 "Information System Controller" 46 "Oil Sensor Unit" 45 "Vehicle Dynamic Stability Control" 44 "Exhaust Emission Control" 43 "Transmission Display" ;
VAL_ 2364473086 ManufacturerCode 454 "NGK Spark Plug Co. Ltd" 453 "Cooper Bussmann" 452 "WIKA Alexander Wiegand SE & Co. KG" 451 "Parker Hannifin Corp" 450 "Dycor Technologies Ltd." 449 "Polaris Industries Inc" 448 "Stanadyne Corporation, Electronics Systems" 447 "Great Plains Mfg." 446 "CertTech, L.L.C." 445 "KAT MECHATRONIC, Electronic Product Division" 444 "ITT Power Solutions" 443 "SignalQuest, Inc." 442 "Horsch Maschinen GmbH" 441 "PTG Reifendruckregelsysteme GmbH" 440 "Cummins Power Generation" 439 "Hyundai Heavy Industries" 438 "Comar Systems Ltd" 437 "Digital Yacht Limited" 436 "Kinze Manufacturing" 435 "Zunhammer GmbH" 434 "Stored Energy Systems" 433 "Rowe Electronics" 432 "S&A Systems, Inc." 431 "Tohatsu Corporation" 430 "Auteq Telematica S.A." 520 "Trapeze" 519 "Peeters Landbouwmachines b.v." 518 "Transas USA Inc." 517 "Noland Engineering" 516 "AVAT Automation GmbH" 515 "GINAF Trucks Nederland B.V." 514 "DISTek Integration, Inc." 513 "FarmscanAg" 512 "Inpower LLC" 511 "Sulky" 510 "Marinesoft Co. Ltd" 509 "MOTORTECH GmbH" 508 "Transtech Innovations" 507 "Test Center ISOBUS" 506 "IHI STAR Machinery Corporation" 505 "Yetter Farm Equipment" 504 "Vesper Marine" 503 "Naviop S.R.L." 502 "Attwood Corporation" 501 "Agrotronix S.A." 500 "Oxbo International Corporation" 499 "LCJ Capteurs" 498 "Innovative Design Solutions, Inc" 497 "SENTRON Sistemas Embarcados" 496 "W. Gessmann GmbH" 495 "HOLMER Maschinenbau GmbH" 494 "Synerject" 493 "Watcheye" 492 "Inergy Automotive Systems" 491 "Penny and Giles Ltd" 490 "QuikQ" 489 "Appareo Systems" 488 "The Charles Machine Works, Inc." 487 "DSE Test Solutions A/S" 486 "Westport Innovations Inc." 485 "MATT automotive" 484 "Headsight Inc." 483 "Valeo" 482 "Tricon Electronics" 481 "Chetco Digital Instruments" 480 "EnerDel, Inc." 479 "Vapor Bus International" 478 "OceanSat BV" 477 "OilQuick AB" 476 "Hummingbird Marine Electronics" 475 "GME" 474 "Persen Technologies Inc." 473 "Boss Industries, Inc." 472 "Tenneco Inc." 471 "Sea Cross Marine AB" 470 "SI-TEX Marine Electronics" 469 "RA Consulting GmbH" 468 "Tyco Fire Protection Products" 467 "Lely Industries N.V." 466 "Veethree Electronics and Marine LLC" 465 "Ashcroft Inc" 464 "Leach International Corporation" 463 "PROBOTIQ" 462 "IHI Shibaura Machinery Corporation" 461 "HAWE Hydraulik SE" 460 "San Giorgio S.E.I.N." 459 "Alltek Marine Electronics Corp" 458 "Control Solutions, Inc." 457 "RUSELPROM-ElectricDrive Ltd" 456 "General Kinetics" 455 "ADZ NAGANO GmbH" 429 "Rota Engineering Ltd." 428 "Mfg_428" 427 "em-trak Marine Electronics Ltd" 426 "Egersund Marine Electronics AS" 425 "Methode Electronics Inc, MDI" 424 "Odyne LLC" 423 "BSM Wireless, Inc." 422 "True Heading AB" 421 "Vertex Standard Co, Ltd" 420 "Vermeer Corporation, ACS Group" 419 "Fusion Electronics Ltd" 418 "Intellistick Inc" 417 "KZValve" 416 "Kubota Corporation" 415 "Valid Manufacturing Ltd." 414 "Cattron Group International" 413 "Datapross Nijbroek bv" 412 "WebTech Wireless Inc." 411 "Hy-Drive Technologies Ltd." 410 "COBO S.p.A. Divisione 3B6" 409 "Transfluid S.r.L." 408 "Corvus Energy Ltd." 407 "Comtech Mobile Datacom" 406 "Vecima Networks Inc." 405 "Wema System AS" 404 "Com Nav Marine Ltd" 403 "Trackwell ADS, Inc." 402 "Simma Software, Inc." 401 "Torqeedo GmbH" 400 "Livorsi Marine" 399 "ISEKI & Co., Ltd." 398 "Hilite International" 397 "Sanyo-kiki Co Ltd." 396 "Beyond Measure" 395 "GENTEC S.R.L." 394 "Capi 2 Nederland BV" 393 "Harvest Tec, Inc" 392 "Tianyuan Technology Co Ltd." 391 "Electronic Design for Industry, Inc" 390 "Partech Inc." 389 "Benchmark Electronics, Minnesota Division" 388 "Innomatix, LLC" 387 "Orscheln Products, LLC" 386 "JLG Automation BVBA" 385 "Johnson Outdoor Marine Electronics" 384 "Camano Light" 383 "MCL Industries" 382 "National Agricultural and Food Research Organization" 380 "Suntech International Ltd." 379 "Yamabiko Corporation" 378 "Glendinning Marine Products" 377 "ifm electronic gmbh" 376 "Quake Global" 375 "Williams Controls Inc." 372 "Delphi" 381 "B&G" 374 "Northern Lights, Inc." 373 "Electronic Design Inc." 371 "Heinzmann GmbH & Co. KG" 370 "Rolls-Royce Marine AS" 369 "Power Torque Engineering Ltd" 368 "HANSENHOF_electronic" 367 "Fliegl Agrartechnik" 366 "Viewnyx Corp." 365 "Digi-Star, LLC" 364 "OEM Controls Inc." 363 "BEI Duncan" 362 "Alois Poettinger Maschinenfabrik GmbH" 361 "InMach" 360 "HJS Emission Technology GmbH & Co KG" 359 "Ludwig Bergmann GmbH" 358 "Victron Energy BV" 357 "Hardi International A/S" 356 "Fischer Panda Generators, Inc" 355 "Mastervolt International B.V." 354 "Junkkari OY" 353 "Hegemon Electronics, Inc." 352 "SAME DEUTZ-FAHR" 351 "Thrane & Thrane" 350 "Noris Marine Systems GmbH & Co KG" 349 "Suonentiet" 348 "Amazonen Werke H. Dreyer" 347 "Honeywell" 346 "Control Solutions" 345 "Korean Maritime University" 344 "Parvus Corporation" 343 "Baumer Group" 342 "THOMAS MAGNETE GmbH" 341 "Boning GmbH & Co" 340 "Continental AG" 339 "Competence Center ISOBUS e.V." 338 "GRAF-SYTECO" 337 "Carraro S.p.A." 336 "APE s.r.o." 335 "Evo Electric Ltd" 334 "Takata-Petri AG" 333 "Hadley Products Corporation" 332 "HWH Corporation" 331 "Horton, Inc." 330 "Kidde Aerospace and Defense" 329 "Deif A/S" 328 "Qwerty Electronik AB" 252 "Sensor-Technik Wiedemann GmbH" 251 "German Agricultural Society" 250 "Kuhn Group" 249 "Schaltbau GmbH" 233 "Yacht Monitoring Solutions Inc." 232 "TSD Integrated Controls" 1863 "Thomas G. Faria Co." 1862 "Sanshin" 1861 "Vector CANtech" 1860 "MMP" 1859 "Kvasar AB" 1858 "Litton" 1857 "Simrad" 1856 "Trimble" 1855 "Furuno USA" 1854 "Northstar Technologies" 1853 "Japan Radio Co." 1852 "Navionics" 1851 "Raymarine" 1850 "Teleflex" 222 "Generac Power Systems, Inc." 221 "SiE" 220 "Beede Electrical Instrument Company, Inc." 219 "Cat OEM Solutions" 218 "Gits Manufacturing Company" 217 "RM Michaelides Software & Elektronik GmbH" 216 "Paneltronics Inc." 215 "Aetna Engineering/Fireboy-Xintex" 214 "MC elettronica Srl" 213 "CNH Belgium N.V." 212 "Sure Power Industries, Inc." 211 "DNA Group" 210 "Iteris, Inc." 209 "Bell Equip. Co. SA (PTY) LTD" 208 "Drew Technologies, Inc." 207 "Otto Engineering" 206 "port GmbH" 205 "SmarTire Systems Inc" 204 "The Morey Corporation" 203 "MILtronik GmbH" 202 "Curtis Instruments, Inc." 201 "Disenos y Tecnologia S.A." 200 "MGM Brakes" 199 "Actia Corp." 198 "Mystic Valley Communications" 197 "Mechron Power Systems" 196 "LEMKEN GmbH & Co. KG" 195 "General Engine Products" 194 "TriMark Corporation" 193 "Nobletec" 192 "Floscan" 191 "XRS Corporation" 190 "Hella KGaA Hueck & Co." 189 "QUALCOMM" 188 "EMP Corp." 187 "Air-Weigh" 186 "Altronic, Inc." 185 "Beede Electrical Instrument Company" 184 "EIA Electronics" 183 "KDS Controls, Inc." 182 "Vehicle Systems Engineering B.V." 181 "Coretronics, Inc." 180 "Smart Power Systems" 179 "TeeJet Technologies Denmark" 178 "Siemens VDO Automotive AG" 177 "Diagnostic System Associates" 176 "Moritz Aerospace" 175 "Veris Technologies, Inc." 174 "AB Volvo Penta" 173 "Ryeso, Inc." 172 "Yanmar Marine USA" 171 "Wachendorff Elektronik GmbH & Co. KG" 170 "Computronics Corporation Ltd." 169 "Marlin Technologies Inc." 168 "Xantrex" 167 "JLG Industries Inc." 166 "Phoenix International" 165 "CPAC Systems AB" 164 "DaimlerChrysler Off-Highway" 163 "BRP Inc." 162 "Axiomatic Technologies" 161 "Offshore Systems (UK) Limited" 160 "Nido" 159 "NTech Industries Inc." 158 "Firestone Industrial Products Company" 157 "ISSPRO Inc." 156 "ITT Industries - Cannon" 155 "Vetronix Corporation" 154 "Westerbeke Corporation" 153 "Woodward, Industrial Controls Division" 152 "elobau GmbH & Co. KG" 151 "Raven Industries Inc. - Flow Controls Division" 150 "Fleetguard" 149 "Holset" 148 "Blue Water Data, Inc." 147 "Nautibus Electronic GmbH" 146 "Maxima Technologies" 145 "MurCal Controls" 144 "Mercury Marine" 143 "W. Gmeiner GmbH & Co." 142 "TRW Automotive (Commercial Steering Systems)" 141 "Thales Navigation Ltd." 140 "Lowrance Electronics, Inc." 139 "Caterpillar Trimble Control Technologies (CTCT), LLC" 138 "Georg Fritzmeier GmbH & Co. KG" 137 "Maretron" 136 "Komatsu Ltd." 135 "Airmar Technology Corporation" 134 "Iris Technology Ltd." 133 "Bucher Schoerling GmbH" 132 "Mulag-Fahrzeugwerk" 131 "ITT Industries" 130 "Nido - Universal Machines B.V." 129 "OMNEX Control Systems, Inc." 128 "Gerhard Duecker GmbH & Co. KG" 127 "Holland USA" 126 "Driver Tech" 125 "Nevada Automotive Test Center" 124 "Hydac Electronic" 123 "Basler Electric" 122 "FG Wilson (Engineering) Limited" 121 "HED (Hydro Electronic Devices, Inc.)" 120 "RDS Technology Ltd." 119 "IntegriNautics" 118 "Intron GmbH" 117 "HUSCO International" 116 "BEELINE Technologies" 115 "NACCO Materials Handling Group, Inc." 114 "EControls, Inc." 113 "Stress-Tek, Inc." 112 "MECALAC" 111 "Maschinenfabrik Bernard Krone GmbH" 110 "EPIQ Sensor-Nite" 109 "TeeJet Technologies Denmark" 108 "WTK-Elecktronik GmbH" 107 "Grimme Landmaschinen GmbH & Co. KG" 106 "BAE Systems Controls, Inc." 105 "Kiepe Elektrik GmbH & Co. KG" 104 "Claas Selbstfahrende Erntemaschinen GmbH" 103 "CLAAS Agrosystems GmbH & Co. KG" 102 "AGCO GmbH & Co." 101 "Sensoria" 100 "VDO Technik AG" 99 "International Transmissions Ltd (ITL)" 98 "Mueller-Elektronik GmbH & Co." 97 "Ag Leader Technology, Inc." 96 "Mech@tronic IT GmbH" 95 "Pacific Insight Electronics Corp." 94 "CNH Global N.V." 93 "Perkins Engines Company Ltd." 92 "Ag-Chem Equipment Co., Inc." 91 "BSG Bodensee Steuergeraete GmbH" 90 "Knorr-Bremse SfN GmbH" 89 "Kverneland Group, Electronics Division" 88 "Satloc Precision GPS" 87 "J.C. Bamford Excavators Ltd (JCB)" 86 "C.E. Niehoff & Company" 85 "Kohler Co." 84 "New Holland UK Limited" 83 "Bendix VORAD Technologies" 82 "Bobcat/Ingersoll-Rand" 81 "Fire Research Corp" 80 "Twin Disc, Inc." 79 "Daimler Benz AG - Engine Division (PBM)" 78 "Frank W. Murphy Manufacturing, Inc." 77 "Deere Power Systems Group" 76 "unused" 75 "Deere & Co. Agricultural Division" 74 "Eaton Axle-Brake Division" 73 "LeTourneau, Inc." 72 "Sisu Corporation" 71 "Vansco Electronics Ltd." 70 "Flex-Coil Limited" 69 "Trimble Navigation" 68 "Scania" 67 "Funk Manufacturing Company" 66 "John Deere Construction Equipment Division" 65 "MAN Nutzfahrzeuge AG" 64 "unused" 63 "ZF Industries Inc." 62 "Wabco" 61 "Volvo Truck Corp." 60 "Volvo Trucks North America Inc." 59 "VES Inc." 58 "SPX Corporation, OTC Division" 57 "Sauer-Danfoss Co." 56 "SAIC" 55 "Ryder System Inc." 54 "Meritor Wabco" 53 "Continental Automotive Systems US, Inc." 52 "Meritor Automotive, Inc." 51 "Robert Bosch GmbH" 50 "Robert Bosch Corp" 49 "RE America Inc." 48 "Pollak Alphabet" 47 "Phillips Semiconductor" 46 "Noregon Systems, Inc" 45 "PACCAR" 44 "Nippondenso Co. Ltd." 43 "International Truck and Engine Corp. Vehicle Electronics" 42 "International Truck and Engine Corp. Engine Electronics" 41 "Motorola Inc." 40 "Motorola AIEG Inc." 39 "Microfirm Inc." 38 "Micro Processor Systems Inc." 37 "Mack Trucks Inc." 36 "Lucas Ltd." 35 "Kenworth Truck Co." 34 "Kelsey Hayes Co." 33 "John Deere" 32 "Jacobs Vehicle Systems" 31 "J Pollak Corp." 30 "Isuzu Motors Ltd." 29 "Hino Motors Ltd." 28 "Grote Ind. Inc." 27 "GMC" 26 "General Motors Corp., Service Technology Group" 25 "Daimler Trucks North America LLC" 24 "Ford Motor Co., Vehicle Controls" 23 "Ford Motor Co., Heavy Truck" 22 "Ford Motor Co., Electronic Concepts $ Systems" 21 "Echilin Inc., Midland Brake Inc." 20 "Eaton Ltd" 19 "Eaton Corp. Trucking Info Services" 18 "Eaton Corp, Transmission Division" 17 "Eaton Corp. Res & Dev" 16 "Eaton Corp." 15 "Dickey-John Corp." 14 "Detroit Diesel Corporation" 13 "Delco Electronics" 12 "Deere & Company, Precision Farming" 11 "Dearborn Group Inc." 10 "Cummins Engine Co." 9 "Chrysler Corp." 8 "Caterpillar Inc." 7 "Case Corp." 6 "Berifors Electronics AB" 5 "AMP Inc." 4 "Ametek-Dixson" 3 "Ametek, US Gauge Division" 2 "Allison Transmission, GMC" 1 "Allied Signal Inc." 0 "Reserved" 231 "Topcon Positioning Systems, Inc." 230 "Saucon Technologies" 229 "Garmin International Inc." 228 "ZF Marine Electronics" 227 "Lykketronic A/S" 226 "Monaco Coach Corporation" 225 "SKF" 224 "EMMI Network, S.L." 223 "Vaueo Retarder Co., Ltd." 263 "IMMI" 262 "HydraForce, Inc" 261 "Red Dot Corporation" 260 "Reichhardt GmbH" 259 "Jetter AG" 258 "ARAG" 257 "Honda Motor Co., Ltd" 256 "Tyco Electronics AMP" 255 "MEAS France" 254 "GE Sensing" 253 "Mobile Control Systems" 298 "Holley Performance" 297 "Zonar Systems Inc" 296 "micro dynamics GmbH" 295 "BEP Marine" 294 "Grayhill Inc." 293 "Spyder Controls Corp." 292 "IKUSI - Angel Iglesias S.A." 291 "Groeneveld Transport Efficiency BV" 290 "Kuebler GmbH" 289 "Watlow" 288 "Mitsubishi FUSO Truck & Bus Corp." 287 "NTech Industries, Inc" 286 "Coelmo srl" 285 "Sea Recovery Corp" 284 "Mobile Tech Chile" 283 "CWF Hamilton & Co Ltd" 282 "Medallion Instrumentation Systems" 281 "Precision Governors LLC" 311 "Patrick Power Products" 310 "TECNORD srl" 309 "Krauss-Maffei Wegmann GmbH & Co. KG" 308 "Cyntrx" 307 "MBW Technologies" 306 "Sleipner Motor AB" 305 "NovAtel Inc" 304 "EmpirBus AB" 303 "CTS Corporation" 302 "Nissin Kogyo Co., LTD" 301 "Parker Hannifin (UK) Ltd FDE group" 300 "Systron Donner Automotive" 299 "Rauch Landmaschinen GmbH" 280 "Leica Geosystems Pty Ltd" 279 "Geometris LP" 278 "Takata Electronics" 277 "LHP Telematics" 276 "Aqua-Hot Heating Systems" 275 "Navico Egersund AS" 274 "LTW Technology Co., LTD" 273 "Active Research Limited" 272 "Gross Mechanical Laboratories, Inc" 327 "Sonceboz SA" 326 "Akron Brass Company" 325 "ASM Automation Sensorik Messtechnik GmbH" 324 "Snap-on Diagnostics" 323 "Mobileye Vision Technologies Ltd." 322 "MICHENKA s.r.o." 321 "Ultra Electronics, Electrics" 320 "Miedema Landbouwwerktuigenfabriek B.V." 319 "Cadec Global" 318 "SAT Plan" 317 "Navtronics Bvba" 316 "ITT Flow Control" 315 "Icom Incorporated" 314 "CSM GmbH" 313 "Ilmor Engineering, Inc" 312 "Lectronix, Inc." 271 "Cole Hersee" 270 "Tennant" 269 "Saft America Inc.,  Space & Defense Division" 268 "Accurate Technologies" 267 "Red Lion Controls, Inc" 266 "International Thermal Research Ltd" 265 "MTS Sensor Technologie GmbH" 264 "Autolync" 248 "Cooper Standard Automotive Active Systems Group" 247 "ePULSE" 246 "Class 1, Inc" 245 "Capstan Ag Systems, Inc." 244 "Techno-Matic" 243 "eRide, Inc." 242 "Kokusandenki Co. Ltd" 241 "Schneider Automation SAS " 240 "Vanair Mfg" 239 "May & Scofield Ltd" 238 "ZF Friedrichshafen AG" 237 "Agtron Enterprises Inc" 236 "Norac Systems International Inc" 235 "SailorMade Marine Telemetry - Tetra Technology Ltd." 234 "Mondial electronic GmbH" ;
VAL_ 2364473086 VehicleSystem 0 "Non-specific System" 127 "Not Available" ;
VAL_ 2364473086 VehicleSystem5 127 "Not Available" 0 "Ind. Process Control Stationary" ;
VAL_ 2364473086 VehicleSystem4 125 "Entertainment" 120 "Display" 85 "External Environment" 75 "Sensor Communication Interface" 35 "Electrical Generation" 100 "Deck, Cargo and Fishing Equipment" 90 "Internal Environment" 80 "Instrumentation/General Systems (deprecate)" 70 "Communications" 60 "Navigation" 50 "Propulsion" 40 "Steering and Control Surfaces" 30 "Electrical Distribution" 25 "Inter/Intranetwork Device" 20 "Safety Systems" 10 "System Tools" 127 "Not Available" 0 "Non-specific System" ;
VAL_ 2364473086 VehicleSystem3 8 "Grader" 7 "Four Wheel Drive Loader" 6 "Forklift" 5 "Excavator" 4 "Crawler" 3 "Backhoe" 2 "Articulated Dump Truck" 1 "Skid Steer Loader" 127 "Not Available" 0 "Non-specific System" ;
VAL_ 2364473086 VehicleSystem2 25 "Slurry Applicators" 24 "Utility Vehicles" 23 "Mulchers" 22 "Timber Processing Machines" 21 "Timber loaders" 20 "Forwarders" 19 "Timber Harvesters" 17 "Sensor Systems" 16 "Skidder" 15 "Earth Work" 14 "Special Crops" 13 "Powered Auxiliary Device" 12 "Farm Yard Operations" 11 "Transport/Trailer" 10 "Irrigation" 9 "Forage" 8 "Root Harvesters" 7 "Harvesters" 6 "Sprayers" 5 "Fertilizers" 4 "Planters/Seeders" 3 "Secondary Tillage" 2 "Tillage" 1 "Tractor" 127 "Not Available" 0 "Non-specific System" ;
VAL_ 2364473086 VehicleSystem1 2 "Trailer" 1 "Tractor" 127 "Not Available" 0 "Non-specific System" ;
VAL_ 2364342014 PGNumber 255 "NotAvailable" ;
VAL_ 2364342014 ControlByte 24 "EAbort" 23 "EEoMACK" 22 "EDPO" 21 "ECTS" 20 "ERTS" 255 "Abort" 32 "BAM" 19 "EoMA" 17 "CTS" 16 "RTS" ;
VAL_ 2362048254 UseTransferMode 3 "NA" 2 "Undefined" 1 "Yes" 0 "No" ;
VAL_ 2499635966 AdditionalAxleGroupLocation 2 "Rear Drive axle group" 1 "Rear Steer axle group" 0 "Reserved" ;
VAL_ 2499635966 AxleGroupLocation 15 "Reserved" 14 "Additional trailer axle group" 13 "Trailer H axle group" 12 "Trailer G axle group" 11 "Trailer F axle group" 10 "Trailer E axle group" 9 "Trailer D axle group" 8 "Trailer C axle group" 7 "Trailer B axle group" 6 "Trailer A axle group" 5 "Additional tractor axle group" 4 "Tag axle group" 3 "Sole or Forward-most Drive axle group" 2 "Lift axle group" 1 "Sole or Forward-most Steer axle group" 0 "Reserved" ;
VAL_ 2633853438 AdditionalAxleGroupLocation 2 "Rear Drive axle group" 1 "Rear Steer axle group" 0 "Reserved" ;
VAL_ 2633853438 AxleGroupLocation 15 "Reserved" 14 "Additional trailer axle group" 13 "Trailer H axle group" 12 "Trailer G axle group" 11 "Trailer F axle group" 10 "Trailer E axle group" 9 "Trailer D axle group" 8 "Trailer C axle group" 7 "Trailer B axle group" 6 "Trailer A axle group" 5 "Additional tractor axle group" 4 "Tag axle group" 3 "Sole or Forward-most Drive axle group" 2 "Lift axle group" 1 "Sole or Forward-most Steer axle group" 0 "Reserved" ;
VAL_ 2432520702 AftercoolerCoolantThermostatMode 3 "dont care/reserved" 2 "reserved" 1 "position control mode used for service only" 0 "temperature control mode" ;
VAL_ 2566745086 RarDriveAxleGroupWeightAvailable 3 "Not available / not applicable" 2 "Reserved" 1 "Rear drive axle group present" 0 "Rear drive axle group not present" ;
VAL_ 2566745086 RarSteerAxleGroupWeightAvailable 3 "Not available / not applicable" 2 "Reserved" 1 "Rear Steer axle group present" 0 "Rear Steer axle group not present" ;
VAL_ 2566745086 AddtnlTrlrAxlGrupWeightAvailable 3 "Not available / not applicable" 2 "Reserved" 1 "Additional trailer axle group present" 0 "Additional trailer axle group not present" ;
VAL_ 2566745086 TrailerHAxleGroupWeightAvailable 3 "Not available / not applicable" 2 "Reserved" 1 "Trailer H axle group present" 0 "Trailer H axle group not present" ;
VAL_ 2566745086 TrailerGAxleGroupWeightAvailable 3 "Not available / not applicable" 2 "Reserved" 1 "Trailer G axle group present" 0 "Trailer G axle group not present" ;
VAL_ 2566745086 TrailerFAxleGroupWeightAvailable 3 "Not available / not applicable" 2 "Reserved" 1 "Trailer F axle group present" 0 "Trailer F axle group not present" ;
VAL_ 2566745086 TrailerEAxleGroupWeightAvailable 3 "Not available / not applicable" 2 "Reserved" 1 "Trailer E axle group present" 0 "Trailer E axle group not present" ;
VAL_ 2566745086 TrailerDAxleGroupWeightAvailable 3 "Not available / not applicable" 2 "Reserved" 1 "Trailer D axle group present" 0 "Trailer D axle group not present" ;
VAL_ 2566745086 TrailerCAxleGroupWeightAvailable 3 "Not available / not applicable" 2 "Reserved" 1 "Trailer C axle group present" 0 "Trailer C axle group not present" ;
VAL_ 2566745086 TrailerBAxleGroupWeightAvailable 3 "Not available / not applicable" 2 "Reserved" 1 "Trailer B axle group present" 0 "Trailer B axle group not present" ;
VAL_ 2566745086 TrailerAAxleGroupWeightAvailable 3 "Not available / not applicable" 2 "Reserved" 1 "Trailer A axle group present" 0 "Trailer A axle group not present" ;
VAL_ 2566745086 AddtnlTrctrAxlGrpWeightAvailable 3 "Not available / not applicable" 2 "Reserved" 1 "Additional tractor axle group present" 0 "Additional tractor axle group not present" ;
VAL_ 2566745086 TagAxleGroupWeightAvailable 3 "Not available / not applicable" 2 "Reserved" 1 "Tag axle group present" 0 "Tag axle group not present" ;
VAL_ 2566745086 DriveAxleGroupWeightAvailable 3 "Not available / not applicable" 2 "Reserved" 1 "Drive axle group present" 0 "Drive axle group not present" ;
VAL_ 2566745086 LiftAxleGroupWeightAvailable 3 "Not available / not applicable" 2 "Reserved" 1 "Lift axle group present" 0 "Lift axle group not present" ;
VAL_ 2566745086 SteerAxleGroupWeightAvailable 3 "Not available / not applicable" 2 "Reserved" 1 "Steer axle group present" 0 "Steer axle group not present" ;
VAL_ 2566739198 FlashRedStopLamp 3 "Unavailable / Do Not Flash" 2 "Reserved" 1 "Fast Flash" 0 "Slow Flash" ;
VAL_ 2566739198 FlashProtectLamp 3 "Unavailable / Do Not Flash" 2 "Reserved" 1 "Fast Flash" 0 "Slow Flash" ;
VAL_ 2566739198 FlashMalfuncIndicatorLamp 3 "Unavailable / Do Not Flash" 2 "Reserved" 1 "Fast Flash" 0 "Slow Flash" ;
VAL_ 2566739198 FlashAmberWarningLamp 3 "Unavailable / Do Not Flash" 2 "Reserved" 1 "Fast Flash" 0 "Slow Flash" ;
VAL_ 2566739198 MalfunctionIndicatorLampStatus 3 "Not available" 2 "Reserved" 1 "Lamp on" 0 "Lamp off" ;
VAL_ 2566739198 AmberWarningLampStatus 3 "Not available" 2 "Reserved" 1 "Lamp on" 0 "Lamp off" ;
VAL_ 2566739198 RedStopLampState 3 "Not available" 2 "Reserved" 1 "Lamp on" 0 "Lamp off" ;
VAL_ 2566739198 ProtectLampStatus 3 "Not available" 2 "Reserved" 1 "Lamp on" 0 "Lamp off" ;
VAL_ 2566739454 FlashRedStopLamp 3 "Unavailable / Do Not Flash" 2 "Reserved" 1 "Fast Flash" 0 "Slow Flash" ;
VAL_ 2566739454 FlashProtectLamp 3 "Unavailable / Do Not Flash" 2 "Reserved" 1 "Fast Flash" 0 "Slow Flash" ;
VAL_ 2566739454 FlashMalfuncIndicatorLamp 3 "Unavailable / Do Not Flash" 2 "Reserved" 1 "Fast Flash" 0 "Slow Flash" ;
VAL_ 2566739454 FlashAmberWarningLamp 3 "Unavailable / Do Not Flash" 2 "Reserved" 1 "Fast Flash" 0 "Slow Flash" ;
VAL_ 2566739454 MalfunctionIndicatorLampStatus 3 "Not available" 2 "Reserved" 1 "Lamp on" 0 "Lamp off" ;
VAL_ 2566739454 AmberWarningLampStatus 3 "Not available" 2 "Reserved" 1 "Lamp on" 0 "Lamp off" ;
VAL_ 2566739454 RedStopLampState 3 "Not available" 2 "Reserved" 1 "Lamp on" 0 "Lamp off" ;
VAL_ 2566739454 ProtectLampStatus 3 "Not available" 2 "Reserved" 1 "Lamp on" 0 "Lamp off" ;
VAL_ 2566739710 FlashRedStopLamp 3 "Unavailable / Do Not Flash" 2 "Reserved" 1 "Fast Flash" 0 "Slow Flash" ;
VAL_ 2566739710 FlashProtectLamp 3 "Unavailable / Do Not Flash" 2 "Reserved" 1 "Fast Flash" 0 "Slow Flash" ;
VAL_ 2566739710 FlashMalfuncIndicatorLamp 3 "Unavailable / Do Not Flash" 2 "Reserved" 1 "Fast Flash" 0 "Slow Flash" ;
VAL_ 2566739710 FlashAmberWarningLamp 3 "Unavailable / Do Not Flash" 2 "Reserved" 1 "Fast Flash" 0 "Slow Flash" ;
VAL_ 2566739710 MalfunctionIndicatorLampStatus 3 "Not available" 2 "Reserved" 1 "Lamp on" 0 "Lamp off" ;
VAL_ 2566739710 AmberWarningLampStatus 3 "Not available" 2 "Reserved" 1 "Lamp on" 0 "Lamp off" ;
VAL_ 2566739710 RedStopLampState 3 "Not available" 2 "Reserved" 1 "Lamp on" 0 "Lamp off" ;
VAL_ 2566739710 ProtectLampStatus 3 "Not available" 2 "Reserved" 1 "Lamp on" 0 "Lamp off" ;
VAL_ 2566739966 FlashRedStopLamp 3 "Unavailable / Do Not Flash" 2 "Reserved" 1 "Fast Flash" 0 "Slow Flash" ;
VAL_ 2566739966 FlashProtectLamp 3 "Unavailable / Do Not Flash" 2 "Reserved" 1 "Fast Flash" 0 "Slow Flash" ;
VAL_ 2566739966 FlashMalfuncIndicatorLamp 3 "Unavailable / Do Not Flash" 2 "Reserved" 1 "Fast Flash" 0 "Slow Flash" ;
VAL_ 2566739966 FlashAmberWarningLamp 3 "Unavailable / Do Not Flash" 2 "Reserved" 1 "Fast Flash" 0 "Slow Flash" ;
VAL_ 2566739966 MalfunctionIndicatorLampStatus 3 "Not available" 2 "Reserved" 1 "Lamp on" 0 "Lamp off" ;
VAL_ 2566739966 AmberWarningLampStatus 3 "Not available" 2 "Reserved" 1 "Lamp on" 0 "Lamp off" ;
VAL_ 2566739966 RedStopLampState 3 "Not available" 2 "Reserved" 1 "Lamp on" 0 "Lamp off" ;
VAL_ 2566739966 ProtectLampStatus 3 "Not available" 2 "Reserved" 1 "Lamp on" 0 "Lamp off" ;
VAL_ 2566740222 FlashRedStopLamp 3 "Unavailable / Do Not Flash" 2 "Reserved" 1 "Fast Flash" 0 "Slow Flash" ;
VAL_ 2566740222 FlashProtectLamp 3 "Unavailable / Do Not Flash" 2 "Reserved" 1 "Fast Flash" 0 "Slow Flash" ;
VAL_ 2566740222 FlashMalfuncIndicatorLamp 3 "Unavailable / Do Not Flash" 2 "Reserved" 1 "Fast Flash" 0 "Slow Flash" ;
VAL_ 2566740222 FlashAmberWarningLamp 3 "Unavailable / Do Not Flash" 2 "Reserved" 1 "Fast Flash" 0 "Slow Flash" ;
VAL_ 2566740222 MalfunctionIndicatorLampStatus 3 "Not available" 2 "Reserved" 1 "Lamp on" 0 "Lamp off" ;
VAL_ 2566740222 AmberWarningLampStatus 3 "Not available" 2 "Reserved" 1 "Lamp on" 0 "Lamp off" ;
VAL_ 2566740222 RedStopLampState 3 "Not available" 2 "Reserved" 1 "Lamp on" 0 "Lamp off" ;
VAL_ 2566740222 ProtectLampStatus 3 "Not available" 2 "Reserved" 1 "Lamp on" 0 "Lamp off" ;
VAL_ 2566740478 FlashRedStopLamp 3 "Unavailable / Do Not Flash" 2 "Reserved" 1 "Fast Flash" 0 "Slow Flash" ;
VAL_ 2566740478 FlashProtectLamp 3 "Unavailable / Do Not Flash" 2 "Reserved" 1 "Fast Flash" 0 "Slow Flash" ;
VAL_ 2566740478 FlashMalfuncIndicatorLamp 3 "Unavailable / Do Not Flash" 2 "Reserved" 1 "Fast Flash" 0 "Slow Flash" ;
VAL_ 2566740478 FlashAmberWarningLamp 3 "Unavailable / Do Not Flash" 2 "Reserved" 1 "Fast Flash" 0 "Slow Flash" ;
VAL_ 2566740478 MalfunctionIndicatorLampStatus 3 "Not available" 2 "Reserved" 1 "Lamp on" 0 "Lamp off" ;
VAL_ 2566740478 AmberWarningLampStatus 3 "Not available" 2 "Reserved" 1 "Lamp on" 0 "Lamp off" ;
VAL_ 2566740478 RedStopLampState 3 "Not available" 2 "Reserved" 1 "Lamp on" 0 "Lamp off" ;
VAL_ 2566740478 ProtectLampStatus 3 "Not available" 2 "Reserved" 1 "Lamp on" 0 "Lamp off" ;
VAL_ 2566740734 FlashRedStopLamp 3 "Unavailable / Do Not Flash" 2 "Reserved" 1 "Fast Flash" 0 "Slow Flash" ;
VAL_ 2566740734 FlashProtectLamp 3 "Unavailable / Do Not Flash" 2 "Reserved" 1 "Fast Flash" 0 "Slow Flash" ;
VAL_ 2566740734 FlashMalfuncIndicatorLamp 3 "Unavailable / Do Not Flash" 2 "Reserved" 1 "Fast Flash" 0 "Slow Flash" ;
VAL_ 2566740734 FlashAmberWarningLamp 3 "Unavailable / Do Not Flash" 2 "Reserved" 1 "Fast Flash" 0 "Slow Flash" ;
VAL_ 2566740734 MalfunctionIndicatorLampStatus 3 "Not available" 2 "Reserved" 1 "Lamp on" 0 "Lamp off" ;
VAL_ 2566740734 AmberWarningLampStatus 3 "Not available" 2 "Reserved" 1 "Lamp on" 0 "Lamp off" ;
VAL_ 2566740734 RedStopLampState 3 "Not available" 2 "Reserved" 1 "Lamp on" 0 "Lamp off" ;
VAL_ 2566740734 ProtectLampStatus 3 "Not available" 2 "Reserved" 1 "Lamp on" 0 "Lamp off" ;
VAL_ 2566740990 FlashRedStopLamp 3 "Unavailable / Do Not Flash" 2 "Reserved" 1 "Fast Flash" 0 "Slow Flash" ;
VAL_ 2566740990 FlashProtectLamp 3 "Unavailable / Do Not Flash" 2 "Reserved" 1 "Fast Flash" 0 "Slow Flash" ;
VAL_ 2566740990 FlashMalfuncIndicatorLamp 3 "Unavailable / Do Not Flash" 2 "Reserved" 1 "Fast Flash" 0 "Slow Flash" ;
VAL_ 2566740990 FlashAmberWarningLamp 3 "Unavailable / Do Not Flash" 2 "Reserved" 1 "Fast Flash" 0 "Slow Flash" ;
VAL_ 2566740990 MalfunctionIndicatorLampStatus 3 "Not available" 2 "Reserved" 1 "Lamp on" 0 "Lamp off" ;
VAL_ 2566740990 AmberWarningLampStatus 3 "Not available" 2 "Reserved" 1 "Lamp on" 0 "Lamp off" ;
VAL_ 2566740990 RedStopLampState 3 "Not available" 2 "Reserved" 1 "Lamp on" 0 "Lamp off" ;
VAL_ 2566740990 ProtectLampStatus 3 "Not available" 2 "Reserved" 1 "Lamp on" 0 "Lamp off" ;
VAL_ 2566741246 FlashRedStopLamp 3 "Unavailable / Do Not Flash" 2 "Reserved" 1 "Fast Flash" 0 "Slow Flash" ;
VAL_ 2566741246 FlashProtectLamp 3 "Unavailable / Do Not Flash" 2 "Reserved" 1 "Fast Flash" 0 "Slow Flash" ;
VAL_ 2566741246 FlashMalfuncIndicatorLamp 3 "Unavailable / Do Not Flash" 2 "Reserved" 1 "Fast Flash" 0 "Slow Flash" ;
VAL_ 2566741246 FlashAmberWarningLamp 3 "Unavailable / Do Not Flash" 2 "Reserved" 1 "Fast Flash" 0 "Slow Flash" ;
VAL_ 2566741246 MalfunctionIndicatorLampStatus 3 "Not available" 2 "Reserved" 1 "Lamp on" 0 "Lamp off" ;
VAL_ 2566741246 AmberWarningLampStatus 3 "Not available" 2 "Reserved" 1 "Lamp on" 0 "Lamp off" ;
VAL_ 2566741246 RedStopLampState 3 "Not available" 2 "Reserved" 1 "Lamp on" 0 "Lamp off" ;
VAL_ 2566741246 ProtectLampStatus 3 "Not available" 2 "Reserved" 1 "Lamp on" 0 "Lamp off" ;
VAL_ 2566741502 FlashRedStopLamp 3 "Unavailable / Do Not Flash" 2 "Reserved" 1 "Fast Flash" 0 "Slow Flash" ;
VAL_ 2566741502 FlashProtectLamp 3 "Unavailable / Do Not Flash" 2 "Reserved" 1 "Fast Flash" 0 "Slow Flash" ;
VAL_ 2566741502 FlashMalfuncIndicatorLamp 3 "Unavailable / Do Not Flash" 2 "Reserved" 1 "Fast Flash" 0 "Slow Flash" ;
VAL_ 2566741502 FlashAmberWarningLamp 3 "Unavailable / Do Not Flash" 2 "Reserved" 1 "Fast Flash" 0 "Slow Flash" ;
VAL_ 2566741502 MalfunctionIndicatorLampStatus 3 "Not available" 2 "Reserved" 1 "Lamp on" 0 "Lamp off" ;
VAL_ 2566741502 AmberWarningLampStatus 3 "Not available" 2 "Reserved" 1 "Lamp on" 0 "Lamp off" ;
VAL_ 2566741502 RedStopLampState 3 "Not available" 2 "Reserved" 1 "Lamp on" 0 "Lamp off" ;
VAL_ 2566741502 ProtectLampStatus 3 "Not available" 2 "Reserved" 1 "Lamp on" 0 "Lamp off" ;
